VERSION "BodyCAN"

NS_ :

BS_:

BU_: CCM CEM DDM ETC ILCM PDM POT RLDM RRDM SMD SMP TRM Vector_XXX

BO_ 1120 CemBodyFr06: 8 CEM
 SG_ CmprReqAcCapReqOvr : 62|7@0+ (1,0) [0|100] "%"  CCM
 SG_ CmprReqAcCapReqOvr_UB : 63|1@0+ (1,0) [0|1] ""  CCM
 SG_ CmptmtClngPreStrtReq : 42|2@0+ (1,0) [0|3] ""  CCM
 SG_ CmptmtClngPreStrtReq_UB : 43|1@0+ (1,0) [0|1] ""  CCM
 SG_ SecRowLeDefdMassgProgCfg_UB : 13|1@0+ (1,0) [0|1] ""  Vector_XXX
 SG_ SecRowLeDefdMassgProgCfgMassgBag : 23|1@0+ (1,0) [0|1] ""  Vector_XXX
 SG_ SecRowLeDefdMassgProgCfgMas_0000 : 22|1@0+ (1,0) [0|1] ""  Vector_XXX
 SG_ SecRowLeDefdMassgProgCfgMas_0001 : 21|1@0+ (1,0) [0|1] ""  Vector_XXX
 SG_ SecRowLeDefdMassgProgCfgMas_0002 : 20|1@0+ (1,0) [0|1] ""  Vector_XXX
 SG_ SecRowLeDefdMassgProgCfgMas_0003 : 19|1@0+ (1,0) [0|1] ""  Vector_XXX
 SG_ SecRowLeDefdMassgProgCfgMas_0004 : 18|1@0+ (1,0) [0|1] ""  Vector_XXX
 SG_ SecRowLeDefdMassgProgCfgMas_0005 : 17|1@0+ (1,0) [0|1] ""  Vector_XXX
 SG_ SecRowLeDefdMassgProgCfgMas_0006 : 16|1@0+ (1,0) [0|1] ""  Vector_XXX
 SG_ SecRowLeDefdMassgProgCfgMas_0007 : 31|1@0+ (1,0) [0|1] ""  Vector_XXX
 SG_ SecRowLeDefdMassgProgCfgMas_0008 : 30|1@0+ (1,0) [0|1] ""  Vector_XXX
 SG_ SecRowLeDefdMassgProgCfgMas_0009 : 29|1@0+ (1,0) [0|1] ""  Vector_XXX
 SG_ SecRowLeDefdMassgProgCfgMas_0010 : 28|1@0+ (1,0) [0|1] ""  Vector_XXX
 SG_ SecRowLeDefdMassgProgCfgMas_0011 : 27|1@0+ (1,0) [0|1] ""  Vector_XXX
 SG_ SecRowLeDefdMassgProgCfgMas_0012 : 26|1@0+ (1,0) [0|1] ""  Vector_XXX
 SG_ SecRowLeDefdMassgProgCfgMas_0013 : 25|1@0+ (1,0) [0|1] ""  Vector_XXX
 SG_ SecRowLeDefdMassgProgCfgMas_0014 : 24|1@0+ (1,0) [0|1] ""  Vector_XXX
 SG_ SecRowLeDefdMassgProgCfgMassgFrq : 39|2@0+ (1,0) [0|3] ""  Vector_XXX
 SG_ SecRowLeDefdMassgProgCfgMassgInt : 37|2@0+ (1,0) [0|3] ""  Vector_XXX
 SG_ SecRowLeDefdMassgProgCfgMassProg : 35|4@0+ (1,0) [0|15] "Unitless"  Vector_XXX
 SG_ SecRowLeDefdMassgProgCfgMas_0015 : 9|2@0+ (1,0) [0|3] ""  Vector_XXX
 SG_ SecRowLeDefdMassgProgCfgMassSeqC : 12|3@0+ (1,0) [0|7] "Unitless"  Vector_XXX

BO_ 1171 CemBodyFr08: 8 CEM
 SG_ AmbTRaw_UB : 45|1@0+ (1,0) [0|1] ""  CCM,DDM,PDM,RLDM,RRDM
 SG_ AmbTRawAmbTVal : 42|11@0+ (0.1,-70) [-70|134.7] "degC"  CCM,DDM,PDM,RLDM,RRDM
 SG_ AmbTRawQly : 44|2@0+ (1,0) [0|3] ""  CCM,DDM,PDM,RLDM,RRDM
 SG_ BltLockStAtDrvr_UB : 21|1@0+ (1,0) [0|1] ""  CCM
 SG_ BltLockStAtDrvrBltLockSt1 : 23|1@0+ (1,0) [0|1] ""  CCM
 SG_ BltLockStAtDrvrBltLockSts : 22|1@0+ (1,0) [0|1] ""  CCM
 SG_ BltLockStAtPass_UB : 34|1@0+ (1,0) [0|1] ""  CCM
 SG_ BltLockStAtPassBltLockSt1 : 33|1@0+ (1,0) [0|1] ""  CCM
 SG_ BltLockStAtPassBltLockSts : 32|1@0+ (1,0) [0|1] ""  CCM
 SG_ BltLockStAtRowSecLe_UB : 4|1@0+ (1,0) [0|1] ""  CCM
 SG_ BltLockStAtRowSecLeBltLockEquid : 7|1@0+ (1,0) [0|1] ""  CCM
 SG_ BltLockStAtRowSecLeBltLockSt1 : 6|1@0+ (1,0) [0|1] ""  CCM
 SG_ BltLockStAtRowSecLeBltLockSts : 5|1@0+ (1,0) [0|1] ""  CCM
 SG_ BltLockStAtRowSecMid_UB : 3|1@0+ (1,0) [0|1] ""  CCM
 SG_ BltLockStAtRowSecMidBltLockEquid : 2|1@0+ (1,0) [0|1] ""  CCM
 SG_ BltLockStAtRowSecMidBltLockSt1 : 1|1@0+ (1,0) [0|1] ""  CCM
 SG_ BltLockStAtRowSecMidBltLockSts : 0|1@0+ (1,0) [0|1] ""  CCM
 SG_ BltLockStAtRowSecRi_UB : 28|1@0+ (1,0) [0|1] ""  CCM
 SG_ BltLockStAtRowSecRiBltLockEquid : 31|1@0+ (1,0) [0|1] ""  CCM
 SG_ BltLockStAtRowSecRiBltLockSt1 : 30|1@0+ (1,0) [0|1] ""  CCM
 SG_ BltLockStAtRowSecRiBltLockSts : 29|1@0+ (1,0) [0|1] ""  CCM
 SG_ BltLockStAtRowThrdLe_UB : 27|1@0+ (1,0) [0|1] ""  CCM
 SG_ BltLockStAtRowThrdLeBltLockEquid : 26|1@0+ (1,0) [0|1] ""  CCM
 SG_ BltLockStAtRowThrdLeBltLockSt1 : 25|1@0+ (1,0) [0|1] ""  CCM
 SG_ BltLockStAtRowThrdLeBltLockSts : 24|1@0+ (1,0) [0|1] ""  CCM
 SG_ BltLockStAtRowThrdRi_UB : 36|1@0+ (1,0) [0|1] ""  CCM
 SG_ BltLockStAtRowThrdRiBltLockEquid : 39|1@0+ (1,0) [0|1] ""  CCM
 SG_ BltLockStAtRowThrdRiBltLockSt1 : 38|1@0+ (1,0) [0|1] ""  CCM
 SG_ BltLockStAtRowThrdRiBltLockSts : 37|1@0+ (1,0) [0|1] ""  CCM
 SG_ CooltHeatrTIntk : 15|8@0+ (1,-40) [-40|210] "degC"  CCM
 SG_ CooltHeatrTIntk_UB : 16|1@0+ (1,0) [0|1] ""  CCM
 SG_ CooltHeatrTOutl : 63|8@0+ (1,-40) [-40|210] "degC"  CCM
 SG_ CooltHeatrTOutl_UB : 47|1@0+ (1,0) [0|1] ""  CCM
 SG_ DrvrPfmncAlrmReq : 19|3@0+ (1,0) [0|7] ""  CCM,SMD
 SG_ DrvrPfmncAlrmReq_UB : 20|1@0+ (1,0) [0|1] ""  CCM,SMD
 SG_ RemChkTInVeh : 35|1@0+ (1,0) [0|1] ""  CCM
 SG_ RemChkTInVeh_UB : 46|1@0+ (1,0) [0|1] ""  CCM

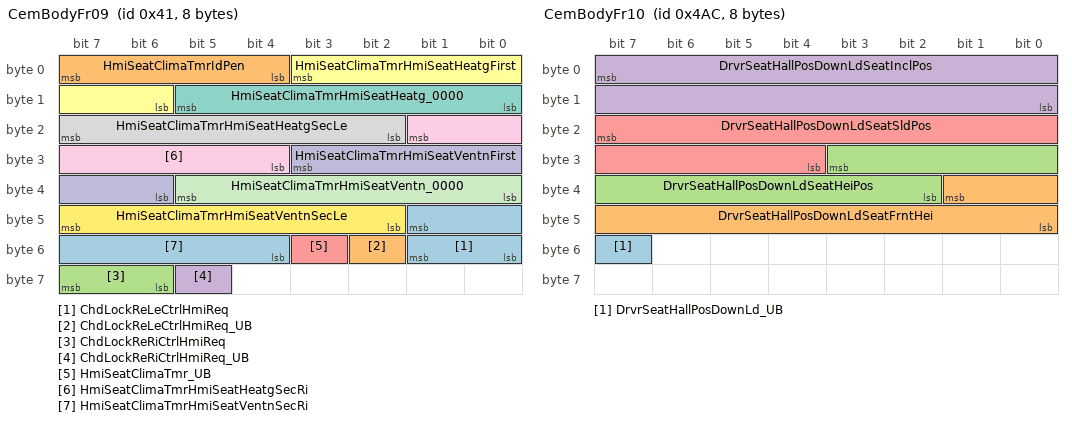
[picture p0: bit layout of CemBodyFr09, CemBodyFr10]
BO_ 65 CemBodyFr09: 8 CEM
 SG_ ChdLockReLeCtrlHmiReq : 49|2@0+ (1,0) [0|3] ""  DDM
 SG_ ChdLockReLeCtrlHmiReq_UB : 50|1@0+ (1,0) [0|1] ""  DDM
 SG_ ChdLockReRiCtrlHmiReq : 63|2@0+ (1,0) [0|3] ""  DDM
 SG_ ChdLockReRiCtrlHmiReq_UB : 61|1@0+ (1,0) [0|1] ""  DDM
 SG_ HmiSeatClimaTmr_UB : 51|1@0+ (1,0) [0|1] ""  SMD,SMP
 SG_ HmiSeatClimaTmrHmiSeatHeatgFirst : 3|6@0+ (1,0) [0|59] "Mins"  SMD,SMP
 SG_ HmiSeatClimaTmrHmiSeatHeatg_0000 : 13|6@0+ (1,0) [0|59] "Mins"  SMD,SMP
 SG_ HmiSeatClimaTmrHmiSeatHeatgSecLe : 23|6@0+ (1,0) [0|59] "Mins"  SMD,SMP
 SG_ HmiSeatClimaTmrHmiSeatHeatgSecRi : 17|6@0+ (1,0) [0|59] "Mins"  SMD,SMP
 SG_ HmiSeatClimaTmrHmiSeatVentnFirst : 27|6@0+ (1,0) [0|59] "Mins"  SMD,SMP
 SG_ HmiSeatClimaTmrHmiSeatVentn_0000 : 37|6@0+ (1,0) [0|59] "Mins"  SMD,SMP
 SG_ HmiSeatClimaTmrHmiSeatVentnSecLe : 47|6@0+ (1,0) [0|59] "Mins"  SMD,SMP
 SG_ HmiSeatClimaTmrHmiSeatVentnSecRi : 41|6@0+ (1,0) [0|59] "Mins"  SMD,SMP
 SG_ HmiSeatClimaTmrIdPen : 7|4@0+ (1,0) [0|15] ""  SMD,SMP

BO_ 1196 CemBodyFr10: 8 CEM
 SG_ DrvrSeatHallPosDownLd_UB : 55|1@0+ (1,0) [0|1] ""  SMD
 SG_ DrvrSeatHallPosDownLdSeatFrntHei : 33|10@0+ (1,0) [0|1023] "Unitless"  SMD
 SG_ DrvrSeatHallPosDownLdSeatHeiPos : 27|10@0+ (1,0) [0|1023] "Unitless"  SMD
 SG_ DrvrSeatHallPosDownLdSeatInclPos : 7|16@0+ (1,0) [0|65535] "Unitless"  SMD
 SG_ DrvrSeatHallPosDownLdSeatSldPos : 23|12@0+ (1,0) [0|4095] "Unitless"  SMD

BO_ 234 CemBodyFr102: 8 CEM
 SG_ DoorSldngLeReReq_UB : 21|1@0+ (1,0) [0|1] ""  Vector_XXX
 SG_ DoorSldngLeReReqChks : 7|8@0+ (1,0) [0|255] "Unitless"  Vector_XXX
 SG_ DoorSldngLeReReqCntr : 15|4@0+ (1,0) [0|15] "Unitless"  Vector_XXX
 SG_ DoorSldngLeReReqDoorOpenerReq : 23|2@0+ (1,0) [0|3] ""  Vector_XXX
 SG_ DoorSldngLeReReqTrigSrc : 11|3@0+ (1,0) [0|7] ""  Vector_XXX
 SG_ DoorSldngRiReReq_UB : 55|1@0+ (1,0) [0|1] ""  Vector_XXX
 SG_ DoorSldngRiReReqChks : 31|8@0+ (1,0) [0|255] "Unitless"  Vector_XXX
 SG_ DoorSldngRiReReqCntr : 39|4@0+ (1,0) [0|15] "Unitless"  Vector_XXX
 SG_ DoorSldngRiReReqDoorOpenerReq : 47|2@0+ (1,0) [0|3] ""  Vector_XXX
 SG_ DoorSldngRiReReqTrigSrc : 35|3@0+ (1,0) [0|7] ""  Vector_XXX
 SG_ FirstRowLeDefdMassgProgSeln : 45|1@0+ (1,0) [0|1] ""  SMD
 SG_ FirstRowLeDefdMassgProgSeln_UB : 44|1@0+ (1,0) [0|1] ""  SMD
 SG_ FirstRowRiDefdMassgProgSeln : 43|1@0+ (1,0) [0|1] ""  SMP
 SG_ FirstRowRiDefdMassgProgSeln_UB : 42|1@0+ (1,0) [0|1] ""  SMP
 SG_ FRDSDoorOpenInd : 41|1@0+ (1,0) [0|1] ""  Vector_XXX
 SG_ FRDSDoorOpenInd_UB : 40|1@0+ (1,0) [0|1] ""  Vector_XXX
 SG_ FRDSLockgSts : 20|1@0+ (1,0) [0|1] ""  Vector_XXX
 SG_ FRDSLockgSts_UB : 19|1@0+ (1,0) [0|1] ""  Vector_XXX
 SG_ TrsmParkLockd_UB : 54|1@0+ (1,0) [0|1] ""  Vector_XXX
 SG_ TrsmParkLockdChks : 63|8@0+ (1,0) [0|255] "Unitless"  Vector_XXX
 SG_ TrsmParkLockdCntr : 51|4@0+ (1,0) [0|15] "Unitless"  Vector_XXX
 SG_ TrsmParkLockdTrsmParkLockd : 53|2@0+ (1,0) [0|3] ""  Vector_XXX

BO_ 91 CemBodyFr103: 8 CEM
 SG_ HvBattLimnIndcn : 23|16@0+ (1,0) [0|65535] "Unitless"  DDM
 SG_ HvBattLimnIndcn_UB : 11|1@0+ (1,0) [0|1] ""  DDM
 SG_ SeatFoldRaiseReqRowSecLe : 39|2@0+ (1,0) [0|3] ""  Vector_XXX
 SG_ SeatFoldRaiseReqRowSecLe_UB : 37|1@0+ (1,0) [0|1] ""  Vector_XXX
 SG_ SeatFoldRaiseReqRowSecMid : 36|2@0+ (1,0) [0|3] ""  Vector_XXX
 SG_ SeatFoldRaiseReqRowSecMid_UB : 34|1@0+ (1,0) [0|1] ""  Vector_XXX
 SG_ SeatFoldRaiseReqRowSecRi : 33|2@0+ (1,0) [0|3] ""  Vector_XXX
 SG_ SeatFoldRaiseReqRowSecRi_UB : 47|1@0+ (1,0) [0|1] ""  Vector_XXX
 SG_ SeatFoldRaiseReqRowThrdLe : 46|2@0+ (1,0) [0|3] ""  Vector_XXX
 SG_ SeatFoldRaiseReqRowThrdLe_UB : 44|1@0+ (1,0) [0|1] ""  Vector_XXX
 SG_ SeatFoldRaiseReqRowThrdRi : 9|2@0+ (1,0) [0|3] ""  Vector_XXX
 SG_ SeatFoldRaiseReqRowThrdRi_UB : 10|1@0+ (1,0) [0|1] ""  Vector_XXX
 SG_ ShortDropWinDrvrDoor : 7|2@0+ (1,0) [0|3] ""  DDM
 SG_ ShortDropWinDrvrDoor_UB : 5|1@0+ (1,0) [0|1] ""  DDM
 SG_ ShortDropWinLeReDoor : 4|2@0+ (1,0) [0|3] ""  RLDM
 SG_ ShortDropWinLeReDoor_UB : 2|1@0+ (1,0) [0|1] ""  RLDM
 SG_ ShortDropWinPassDoor : 1|2@0+ (1,0) [0|3] ""  PDM
 SG_ ShortDropWinPassDoor_UB : 15|1@0+ (1,0) [0|1] ""  PDM
 SG_ ShortDropWinRiReDoor : 14|2@0+ (1,0) [0|3] ""  RRDM
 SG_ ShortDropWinRiReDoor_UB : 12|1@0+ (1,0) [0|1] ""  RRDM

BO_ 132 CemBodyFr104: 8 CEM
 SG_ LeReWinBtnDwn : 3|1@0+ (1,0) [0|1] ""  RLDM
 SG_ LeReWinBtnDwn_UB : 5|1@0+ (1,0) [0|1] ""  RLDM
 SG_ LeReWinBtnRise : 4|1@0+ (1,0) [0|1] ""  RLDM
 SG_ LeReWinBtnRise_UB : 6|1@0+ (1,0) [0|1] ""  RLDM
 SG_ MusicInfoForMusicShow2_UB : 2|1@0+ (1,0) [0|1] ""  ILCM
 SG_ MusicInfoForMusicShow2DownSampli : 15|4@0+ (1,0) [0|15] "Unitless"  ILCM
 SG_ MusicInfoForMusicShow2MaxFFT100m : 11|4@0+ (1,0) [0|15] "Unitless"  ILCM
 SG_ MusicInfoForMusicShow2MaxFF_0000 : 23|8@0+ (1,0) [0|255] "Unitless"  ILCM
 SG_ MusicInfoForMusicShow2Segment1FF : 31|4@0+ (1,0) [0|15] "Unitless"  ILCM
 SG_ MusicInfoForMusicShow2Segment2FF : 27|4@0+ (1,0) [0|15] "Unitless"  ILCM
 SG_ MusicInfoForMusicShow2Segment3FF : 39|4@0+ (1,0) [0|15] "Unitless"  ILCM
 SG_ MusicInfoForMusicShow2Segment4FF : 35|4@0+ (1,0) [0|15] "Unitless"  ILCM
 SG_ MusicInfoForMusicShow2Segment5FF : 47|4@0+ (1,0) [0|15] "Unitless"  ILCM
 SG_ MusicInfoForMusicShow2Segment6FF : 43|4@0+ (1,0) [0|15] "Unitless"  ILCM
 SG_ MusicInfoForMusicShow2Segment7FF : 55|4@0+ (1,0) [0|15] "Unitless"  ILCM
 SG_ MusicInfoForMusicShow2Segment8FF : 51|4@0+ (1,0) [0|15] "Unitless"  ILCM
 SG_ MusicInfoForMusicShow2StateFlagA : 1|1@0+ (1,0) [0|1] ""  ILCM
 SG_ MusicInfoForMusicShow2StateFlagN : 0|1@0+ (1,0) [0|1] ""  ILCM
 SG_ MusicInfoForMusicShow2TimeFlagAu : 63|4@0+ (1,0) [0|15] "Unitless"  ILCM
 SG_ MusicInfoForMusicShow2TimeFlagMe : 59|4@0+ (1,0) [0|15] "Unitless"  ILCM

BO_ 136 CemBodyFr105: 8 CEM
 SG_ MusicInfoForMusicShow3_UB : 2|1@0+ (1,0) [0|1] ""  ILCM
 SG_ MusicInfoForMusicShow3DownSampli : 15|4@0+ (1,0) [0|15] "Unitless"  ILCM
 SG_ MusicInfoForMusicShow3MaxFFT100m : 11|4@0+ (1,0) [0|15] "Unitless"  ILCM
 SG_ MusicInfoForMusicShow3MaxFF_0000 : 23|8@0+ (1,0) [0|255] "Unitless"  ILCM
 SG_ MusicInfoForMusicShow3Segment1FF : 31|4@0+ (1,0) [0|15] "Unitless"  ILCM
 SG_ MusicInfoForMusicShow3Segment2FF : 27|4@0+ (1,0) [0|15] "Unitless"  ILCM
 SG_ MusicInfoForMusicShow3Segment3FF : 39|4@0+ (1,0) [0|15] "Unitless"  ILCM
 SG_ MusicInfoForMusicShow3Segment4FF : 35|4@0+ (1,0) [0|15] "Unitless"  ILCM
 SG_ MusicInfoForMusicShow3Segment5FF : 47|4@0+ (1,0) [0|15] "Unitless"  ILCM
 SG_ MusicInfoForMusicShow3Segment6FF : 43|4@0+ (1,0) [0|15] "Unitless"  ILCM
 SG_ MusicInfoForMusicShow3Segment7FF : 55|4@0+ (1,0) [0|15] "Unitless"  ILCM
 SG_ MusicInfoForMusicShow3Segment8FF : 51|4@0+ (1,0) [0|15] "Unitless"  ILCM
 SG_ MusicInfoForMusicShow3StateFlagA : 1|1@0+ (1,0) [0|1] ""  ILCM
 SG_ MusicInfoForMusicShow3StateFlagN : 0|1@0+ (1,0) [0|1] ""  ILCM
 SG_ MusicInfoForMusicShow3TimeFlagAu : 63|4@0+ (1,0) [0|15] "Unitless"  ILCM
 SG_ MusicInfoForMusicShow3TimeFlagMe : 59|4@0+ (1,0) [0|15] "Unitless"  ILCM
 SG_ RiReWinBtnDwn : 3|1@0+ (1,0) [0|1] ""  RRDM
 SG_ RiReWinBtnDwn_UB : 5|1@0+ (1,0) [0|1] ""  RRDM
 SG_ RiReWinBtnRise : 4|1@0+ (1,0) [0|1] ""  RRDM
 SG_ RiReWinBtnRise_UB : 6|1@0+ (1,0) [0|1] ""  RRDM

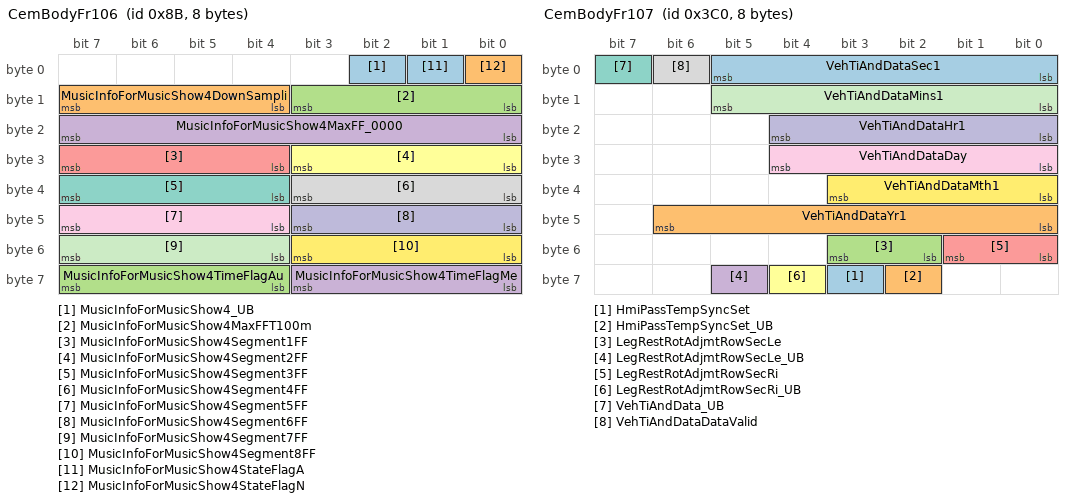
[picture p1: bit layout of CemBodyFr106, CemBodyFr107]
BO_ 139 CemBodyFr106: 8 CEM
 SG_ MusicInfoForMusicShow4_UB : 2|1@0+ (1,0) [0|1] ""  ILCM
 SG_ MusicInfoForMusicShow4DownSampli : 15|4@0+ (1,0) [0|15] "Unitless"  ILCM
 SG_ MusicInfoForMusicShow4MaxFFT100m : 11|4@0+ (1,0) [0|15] "Unitless"  ILCM
 SG_ MusicInfoForMusicShow4MaxFF_0000 : 23|8@0+ (1,0) [0|255] "Unitless"  ILCM
 SG_ MusicInfoForMusicShow4Segment1FF : 31|4@0+ (1,0) [0|15] "Unitless"  ILCM
 SG_ MusicInfoForMusicShow4Segment2FF : 27|4@0+ (1,0) [0|15] "Unitless"  ILCM
 SG_ MusicInfoForMusicShow4Segment3FF : 39|4@0+ (1,0) [0|15] "Unitless"  ILCM
 SG_ MusicInfoForMusicShow4Segment4FF : 35|4@0+ (1,0) [0|15] "Unitless"  ILCM
 SG_ MusicInfoForMusicShow4Segment5FF : 47|4@0+ (1,0) [0|15] "Unitless"  ILCM
 SG_ MusicInfoForMusicShow4Segment6FF : 43|4@0+ (1,0) [0|15] "Unitless"  ILCM
 SG_ MusicInfoForMusicShow4Segment7FF : 55|4@0+ (1,0) [0|15] "Unitless"  ILCM
 SG_ MusicInfoForMusicShow4Segment8FF : 51|4@0+ (1,0) [0|15] "Unitless"  ILCM
 SG_ MusicInfoForMusicShow4StateFlagA : 1|1@0+ (1,0) [0|1] ""  ILCM
 SG_ MusicInfoForMusicShow4StateFlagN : 0|1@0+ (1,0) [0|1] ""  ILCM
 SG_ MusicInfoForMusicShow4TimeFlagAu : 63|4@0+ (1,0) [0|15] "Unitless"  ILCM
 SG_ MusicInfoForMusicShow4TimeFlagMe : 59|4@0+ (1,0) [0|15] "Unitless"  ILCM

BO_ 960 CemBodyFr107: 8 CEM
 SG_ HmiPassTempSyncSet : 59|1@0+ (1,0) [0|1] ""  CCM
 SG_ HmiPassTempSyncSet_UB : 58|1@0+ (1,0) [0|1] ""  CCM
 SG_ LegRestRotAdjmtRowSecLe : 51|2@0+ (1,0) [0|3] ""  Vector_XXX
 SG_ LegRestRotAdjmtRowSecLe_UB : 61|1@0+ (1,0) [0|1] ""  Vector_XXX
 SG_ LegRestRotAdjmtRowSecRi : 49|2@0+ (1,0) [0|3] ""  Vector_XXX
 SG_ LegRestRotAdjmtRowSecRi_UB : 60|1@0+ (1,0) [0|1] ""  Vector_XXX
 SG_ VehTiAndData_UB : 7|1@0+ (1,0) [0|1] ""  CCM,ILCM
 SG_ VehTiAndDataDataValid : 6|1@0+ (1,0) [0|1] ""  CCM,ILCM
 SG_ VehTiAndDataDay : 28|5@0+ (1,0) [1|31] "Days"  CCM,ILCM
 SG_ VehTiAndDataHr1 : 20|5@0+ (1,0) [0|23] "hours"  CCM,ILCM
 SG_ VehTiAndDataMins1 : 13|6@0+ (1,0) [0|59] "Mins"  CCM,ILCM
 SG_ VehTiAndDataMth1 : 35|4@0+ (1,0) [1|12] "Month"  CCM,ILCM
 SG_ VehTiAndDataSec1 : 5|6@0+ (1,0) [0|59] "s"  CCM,ILCM
 SG_ VehTiAndDataYr1 : 46|7@0+ (1,0) [0|99] "Year"  CCM,ILCM

BO_ 243 CemBodyFr108: 8 CEM
 SG_ ActvnOfPudLi : 53|1@0+ (1,0) [0|1] ""  DDM,PDM
 SG_ ActvnOfPudLi_UB : 52|1@0+ (1,0) [0|1] ""  DDM,PDM
 SG_ CushExtnSecRowLe : 39|2@0+ (1,0) [0|3] ""  Vector_XXX
 SG_ CushExtnSecRowLe_UB : 47|1@0+ (1,0) [0|1] ""  Vector_XXX
 SG_ CushExtnSecRowRi : 41|2@0+ (1,0) [0|3] ""  Vector_XXX
 SG_ CushExtnSecRowRi_UB : 42|1@0+ (1,0) [0|1] ""  Vector_XXX
 SG_ HmiElecAirFrntSwtReq_UB : 62|1@0+ (1,0) [0|1] ""  CCM
 SG_ HmiElecAirFrntSwtReqHmiElecAirDr : 59|1@0+ (1,0) [0|1] ""  CCM
 SG_ HmiElecAirFrntSwtReqHmiElec_0000 : 58|1@0+ (1,0) [0|1] ""  CCM
 SG_ HmiElecAirFrntSwtReqHmiElecAirPa : 57|1@0+ (1,0) [0|1] ""  CCM
 SG_ HmiElecAirFrntSwtReqHmiElec_0001 : 56|1@0+ (1,0) [0|1] ""  CCM
 SG_ HmiElecAirReSwtReq_UB : 63|1@0+ (1,0) [0|1] ""  CCM
 SG_ HmiElecAirReSwtReqHmiElecAirReLe : 49|1@0+ (1,0) [0|1] ""  CCM
 SG_ HmiElecAirReSwtReqHmiElecAirReRi : 48|1@0+ (1,0) [0|1] ""  CCM
 SG_ RearWinDimEna : 61|2@0+ (1,0) [0|3] ""  RLDM,RRDM
 SG_ RearWinDimEna_UB : 51|1@0+ (1,0) [0|1] ""  RLDM,RRDM
 SG_ RollAgGlb_UB : 30|1@0+ (1,0) [0|1] ""  Vector_XXX
 SG_ RollAgGlbQf : 1|2@0+ (1,0) [0|3] ""  Vector_XXX
 SG_ RollAgGlbVal : 15|16@0- (3.0518E-005,0) [-0.999983306|0.999983306] "rad"  Vector_XXX
 SG_ SecRowLeLoadAndStoreReq_UB : 7|1@0+ (1,0) [0|1] ""  Vector_XXX
 SG_ SecRowLeLoadAndStoreReqErgoPosn : 3|2@0+ (1,0) [0|3] ""  Vector_XXX
 SG_ SecRowLeLoadAndStoreReqErgoSetgE : 6|3@0+ (1,0) [0|7] ""  Vector_XXX
 SG_ SecRowRiLoadAndStoreReq_UB : 29|1@0+ (1,0) [0|1] ""  Vector_XXX
 SG_ SecRowRiLoadAndStoreReqErgoPosn : 28|2@0+ (1,0) [0|3] ""  Vector_XXX
 SG_ SecRowRiLoadAndStoreReqErgoSetgE : 26|3@0+ (1,0) [0|7] ""  Vector_XXX
 SG_ SecRowRiSeatDispMassgFct_UB : 31|1@0+ (1,0) [0|1] ""  Vector_XXX
 SG_ SecRowRiSeatDispMassgFctMassgInt : 33|2@0+ (1,0) [0|3] ""  Vector_XXX
 SG_ SecRowRiSeatDispMassgFctMassgPro : 36|3@0+ (1,0) [0|7] ""  Vector_XXX
 SG_ SecRowRiSeatDispMassgFctOnOff : 37|1@0+ (1,0) [0|1] ""  Vector_XXX
 SG_ ShoulderAdjmtRowSecLe : 44|2@0+ (1,0) [0|3] ""  Vector_XXX
 SG_ ShoulderAdjmtRowSecLe_UB : 45|1@0+ (1,0) [0|1] ""  Vector_XXX
 SG_ ShoulderAdjmtRowSecRi : 55|2@0+ (1,0) [0|3] ""  Vector_XXX
 SG_ ShoulderAdjmtRowSecRi_UB : 46|1@0+ (1,0) [0|1] ""  Vector_XXX

BO_ 818 CemBodyFr109: 8 CEM
 SG_ HmiCmptmtSecRowLeAirDistbn : 7|3@0+ (1,0) [0|7] ""  CCM
 SG_ HmiCmptmtSecRowLeAirDistbn_UB : 4|1@0+ (1,0) [0|1] ""  CCM
 SG_ HmiCmptmtSecRowRiAirDistbn : 2|3@0+ (1,0) [0|7] ""  CCM
 SG_ HmiCmptmtSecRowRiAirDistbn_UB : 3|1@0+ (1,0) [0|1] ""  CCM
 SG_ HmiDrvrClimaAutReq : 17|1@0+ (1,0) [0|1] ""  CCM
 SG_ HmiDrvrClimaAutReq_UB : 18|1@0+ (1,0) [0|1] ""  CCM
 SG_ HmiDrvrHvacFanLvl : 15|4@0+ (1,0) [0|15] ""  CCM
 SG_ HmiDrvrHvacFanLvl_UB : 23|1@0+ (1,0) [0|1] ""  CCM
 SG_ HmiPassClimaAutReq : 19|1@0+ (1,0) [0|1] ""  CCM
 SG_ HmiPassClimaAutReq_UB : 20|1@0+ (1,0) [0|1] ""  CCM
 SG_ HmiPassHvacFanLvl : 11|4@0+ (1,0) [0|15] ""  CCM
 SG_ HmiPassHvacFanLvl_UB : 16|1@0+ (1,0) [0|1] ""  CCM
 SG_ HmiSecRowLeClimaAutReq : 21|1@0+ (1,0) [0|1] ""  CCM
 SG_ HmiSecRowLeClimaAutReq_UB : 22|1@0+ (1,0) [0|1] ""  CCM
 SG_ HmiSecRowLeHvacFanLvl : 31|4@0+ (1,0) [0|15] ""  CCM
 SG_ HmiSecRowLeHvacFanLvl_UB : 27|1@0+ (1,0) [0|1] ""  CCM
 SG_ HmiSecRowRiClimaAutReq : 26|1@0+ (1,0) [0|1] ""  CCM
 SG_ HmiSecRowRiClimaAutReq_UB : 25|1@0+ (1,0) [0|1] ""  CCM
 SG_ HmiSecRowRiHvacFanLvl : 39|4@0+ (1,0) [0|15] ""  CCM
 SG_ HmiSecRowRiHvacFanLvl_UB : 24|1@0+ (1,0) [0|1] ""  CCM

BO_ 224 CEMBodyFr11: 8 CEM
 SG_ DoorPassSts : 31|2@0+ (1,0) [0|3] ""  CCM,DDM,ILCM,PDM,RLDM,RRDM,SMP,TRM
 SG_ DoorPassSts_UB : 29|1@0+ (1,0) [0|1] ""  CCM,DDM,ILCM,PDM,RLDM,RRDM,SMP,TRM
 SG_ DoorRiReSts : 13|2@0+ (1,0) [0|3] ""  CCM,DDM,ILCM,PDM,RLDM,RRDM,TRM
 SG_ DoorRiReSts_UB : 14|1@0+ (1,0) [0|1] ""  CCM,DDM,ILCM,PDM,RLDM,RRDM,TRM
 SG_ HvPwrAvlForClimaEstimd : 25|10@0+ (20,0) [0|20460] "W"  CCM
 SG_ HvPwrAvlForClimaEstimd_UB : 26|1@0+ (1,0) [0|1] ""  CCM
 SG_ IntrBriSts : 43|4@0+ (1,0) [0|15] "Unitless"  CCM,DDM,ILCM,PDM,RLDM,RRDM
 SG_ IntrBriSts_UB : 44|1@0+ (1,0) [0|1] ""  CCM,DDM,ILCM,PDM,RLDM,RRDM
 SG_ MirrTintgCmd : 54|7@0+ (1,0) [0|100] "%"  DDM,PDM
 SG_ MirrTintgCmd_UB : 55|1@0+ (1,0) [0|1] ""  DDM,PDM
 SG_ SecRowLeSeatDispSpplFct : 7|3@0+ (1,0) [0|7] ""  Vector_XXX
 SG_ SecRowLeSeatDispSpplFct_UB : 4|1@0+ (1,0) [0|1] ""  Vector_XXX
 SG_ SecRowRiSeatDispSpplFct : 3|3@0+ (1,0) [0|7] ""  Vector_XXX
 SG_ SecRowRiSeatDispSpplFct_UB : 0|1@0+ (1,0) [0|1] ""  Vector_XXX
 SG_ SecRowSeatDispBtnPsd_UB : 10|1@0+ (1,0) [0|1] ""  Vector_XXX
 SG_ SecRowSeatDispBtnPsdSecRowLeSeat : 8|1@0+ (1,0) [0|1] ""  Vector_XXX
 SG_ SecRowSeatDispBtnPsdSecRowRiSeat : 9|1@0+ (1,0) [0|1] ""  Vector_XXX
 SG_ SteerWhlHeatgDesPwr : 23|8@0+ (1,0) [0|255] "Unitless"  CCM
 SG_ SteerWhlHeatgDesPwr_UB : 11|1@0+ (1,0) [0|1] ""  CCM
 SG_ TopPosTrFromHmi : 58|3@0+ (1,0) [0|7] ""  POT
 SG_ TopPosTrFromHmi_UB : 15|1@0+ (1,0) [0|1] ""  POT
 SG_ TrlrLampChkReqFromHmi : 63|2@0+ (1,0) [0|3] ""  TRM
 SG_ TrlrLampChkReqFromHmi_UB : 61|1@0+ (1,0) [0|1] ""  TRM
 SG_ TrlrLiFogActvt : 59|1@0+ (1,0) [0|1] ""  TRM
 SG_ TrlrLiFogActvt_UB : 60|1@0+ (1,0) [0|1] ""  TRM
 SG_ TrPosnUpprProgmReq : 28|1@0+ (1,0) [0|1] ""  POT
 SG_ TrPosnUpprProgmReq_UB : 27|1@0+ (1,0) [0|1] ""  POT
 SG_ TrSts : 47|2@0+ (1,0) [0|3] ""  CCM,TRM
 SG_ TrSts_UB : 45|1@0+ (1,0) [0|1] ""  CCM,TRM

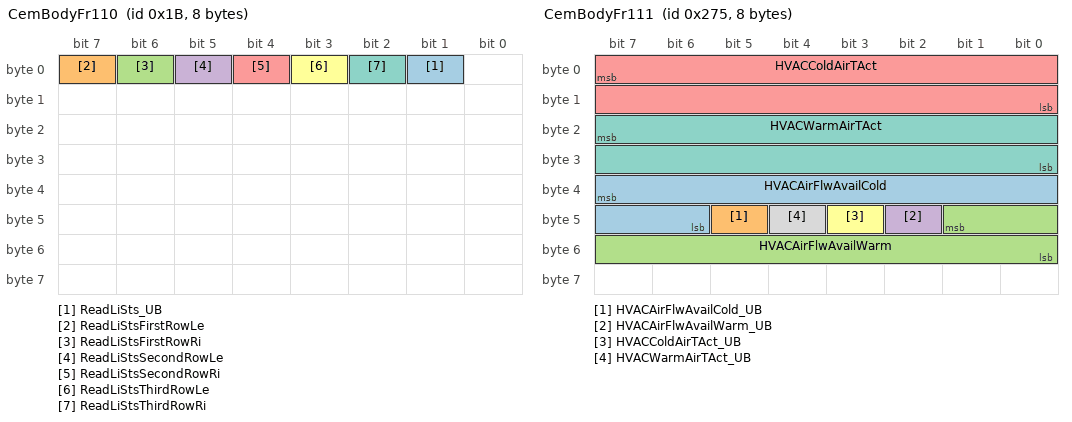
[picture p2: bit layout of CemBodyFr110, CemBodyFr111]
BO_ 27 CemBodyFr110: 8 CEM
 SG_ ReadLiSts_UB : 1|1@0+ (1,0) [0|1] ""  Vector_XXX
 SG_ ReadLiStsFirstRowLe : 7|1@0+ (1,0) [0|1] ""  Vector_XXX
 SG_ ReadLiStsFirstRowRi : 6|1@0+ (1,0) [0|1] ""  Vector_XXX
 SG_ ReadLiStsSecondRowLe : 5|1@0+ (1,0) [0|1] ""  Vector_XXX
 SG_ ReadLiStsSecondRowRi : 4|1@0+ (1,0) [0|1] ""  Vector_XXX
 SG_ ReadLiStsThirdRowLe : 3|1@0+ (1,0) [0|1] ""  Vector_XXX
 SG_ ReadLiStsThirdRowRi : 2|1@0+ (1,0) [0|1] ""  Vector_XXX

BO_ 629 CemBodyFr111: 8 CEM
 SG_ HVACAirFlwAvailCold : 39|10@0+ (1,0) [0|1000] "Kg / h"  Vector_XXX
 SG_ HVACAirFlwAvailCold_UB : 45|1@0+ (1,0) [0|1] ""  Vector_XXX
 SG_ HVACAirFlwAvailWarm : 41|10@0+ (1,0) [0|1000] "Kg / h"  Vector_XXX
 SG_ HVACAirFlwAvailWarm_UB : 42|1@0+ (1,0) [0|1] ""  Vector_XXX
 SG_ HVACColdAirTAct : 7|16@0+ (0.5,-40) [-40|254] "degC"  Vector_XXX
 SG_ HVACColdAirTAct_UB : 43|1@0+ (1,0) [0|1] ""  Vector_XXX
 SG_ HVACWarmAirTAct : 23|16@0+ (0.5,-40) [-40|254] "degC"  Vector_XXX
 SG_ HVACWarmAirTAct_UB : 44|1@0+ (1,0) [0|1] ""  Vector_XXX

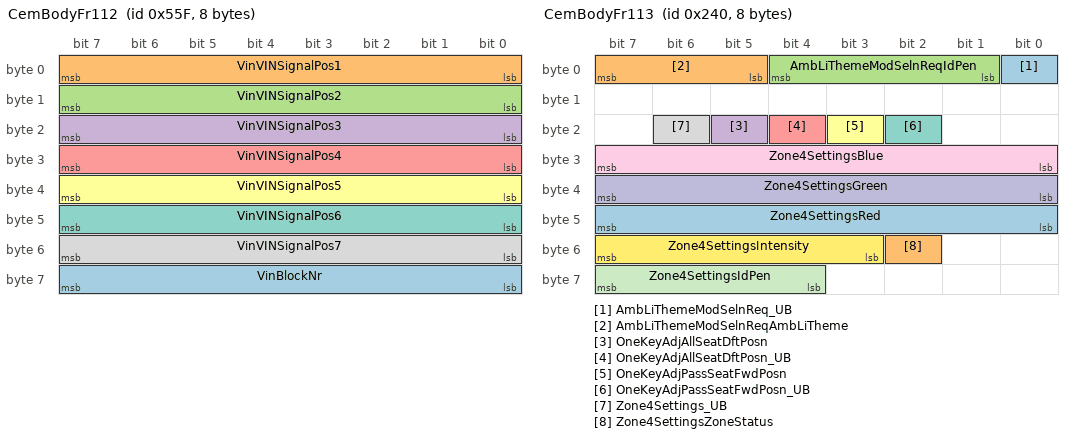
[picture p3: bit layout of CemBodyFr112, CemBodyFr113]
BO_ 1375 CemBodyFr112: 8 CEM
 SG_ VinBlockNr : 63|8@0+ (1,0) [0|255] "Unitless"  CCM
 SG_ VinVINSignalPos1 : 7|8@0+ (1,0) [0|255] "Unitless"  CCM
 SG_ VinVINSignalPos2 : 15|8@0+ (1,0) [0|255] "Unitless"  CCM
 SG_ VinVINSignalPos3 : 23|8@0+ (1,0) [0|255] "Unitless"  CCM
 SG_ VinVINSignalPos4 : 31|8@0+ (1,0) [0|255] "Unitless"  CCM
 SG_ VinVINSignalPos5 : 39|8@0+ (1,0) [0|255] "Unitless"  CCM
 SG_ VinVINSignalPos6 : 47|8@0+ (1,0) [0|255] "Unitless"  CCM
 SG_ VinVINSignalPos7 : 55|8@0+ (1,0) [0|255] "Unitless"  CCM

BO_ 576 CemBodyFr113: 8 CEM
 SG_ AmbLiThemeModSelnReq_UB : 0|1@0+ (1,0) [0|1] ""  ILCM
 SG_ AmbLiThemeModSelnReqAmbLiTheme : 7|3@0+ (1,0) [0|7] ""  ILCM
 SG_ AmbLiThemeModSelnReqIdPen : 4|4@0+ (1,0) [0|15] ""  ILCM
 SG_ OneKeyAdjAllSeatDftPosn : 21|1@0+ (1,0) [0|1] ""  SMD,SMP
 SG_ OneKeyAdjAllSeatDftPosn_UB : 20|1@0+ (1,0) [0|1] ""  SMD,SMP
 SG_ OneKeyAdjPassSeatFwdPosn : 19|1@0+ (1,0) [0|1] ""  SMP
 SG_ OneKeyAdjPassSeatFwdPosn_UB : 18|1@0+ (1,0) [0|1] ""  SMP
 SG_ Zone4Settings_UB : 22|1@0+ (1,0) [0|1] ""  ILCM
 SG_ Zone4SettingsBlue : 31|8@0+ (1,0) [0|255] "Unitless"  ILCM
 SG_ Zone4SettingsGreen : 39|8@0+ (1,0) [0|255] "Unitless"  ILCM
 SG_ Zone4SettingsIdPen : 63|4@0+ (1,0) [0|15] ""  ILCM
 SG_ Zone4SettingsIntensity : 55|5@0+ (1,0) [0|31] "Unitless"  ILCM
 SG_ Zone4SettingsRed : 47|8@0+ (1,0) [0|255] "Unitless"  ILCM
 SG_ Zone4SettingsZoneStatus : 50|1@0+ (1,0) [0|1] ""  ILCM

BO_ 592 CemBodyFr114: 8 CEM
 SG_ AmbLiSpeechCorrlnReq_UB : 10|1@0+ (1,0) [0|1] ""  ILCM
 SG_ AmbLiSpeechCorrlnReqIdPen : 4|4@0+ (1,0) [0|15] ""  ILCM
 SG_ AmbLiSpeechCorrlnReqOnOff1 : 0|1@0+ (1,0) [0|1] ""  ILCM
 SG_ DrvrSeatFldUnfld : 59|2@0+ (1,0) [0|3] ""  SMD
 SG_ DrvrSeatFldUnfld_UB : 23|1@0+ (1,0) [0|1] ""  SMD
 SG_ DrvrSeatHMIpivtCntrl : 57|2@0+ (1,0) [0|3] ""  SMD
 SG_ DrvrSeatHMIpivtCntrl_UB : 22|1@0+ (1,0) [0|1] ""  SMD
 SG_ DrvrSeatSts : 7|2@0+ (1,0) [0|3] ""  CCM,ILCM,SMD
 SG_ DrvrSeatSts_UB : 5|1@0+ (1,0) [0|1] ""  CCM,ILCM,SMD
 SG_ RoadInclnForPOD : 15|5@0+ (1,0) [0|31] ""  Vector_XXX
 SG_ RoadInclnForPOD_UB : 9|1@0+ (1,0) [0|1] ""  Vector_XXX
 SG_ RollAgGlbForPOD : 20|5@0+ (1,0) [0|31] ""  Vector_XXX
 SG_ RollAgGlbForPOD_UB : 8|1@0+ (1,0) [0|1] ""  Vector_XXX
 SG_ Zone5Settings_UB : 21|1@0+ (1,0) [0|1] ""  ILCM
 SG_ Zone5SettingsBlue : 31|8@0+ (1,0) [0|255] "Unitless"  ILCM
 SG_ Zone5SettingsGreen : 39|8@0+ (1,0) [0|255] "Unitless"  ILCM
 SG_ Zone5SettingsIdPen : 63|4@0+ (1,0) [0|15] ""  ILCM
 SG_ Zone5SettingsIntensity : 55|5@0+ (1,0) [0|31] "Unitless"  ILCM
 SG_ Zone5SettingsRed : 47|8@0+ (1,0) [0|255] "Unitless"  ILCM
 SG_ Zone5SettingsZoneStatus : 50|1@0+ (1,0) [0|1] ""  ILCM

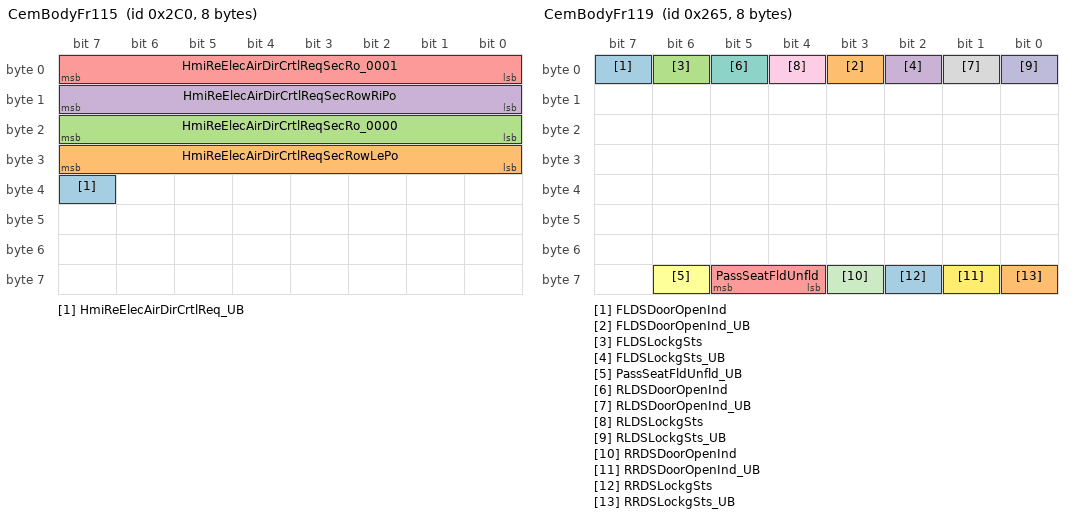
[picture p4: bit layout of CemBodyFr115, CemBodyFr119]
BO_ 704 CemBodyFr115: 8 CEM
 SG_ HmiReElecAirDirCrtlReq_UB : 39|1@0+ (1,0) [0|1] ""  CCM
 SG_ HmiReElecAirDirCrtlReqSecRowLePo : 31|8@0+ (1,0) [0|255] "Unitless"  CCM
 SG_ HmiReElecAirDirCrtlReqSecRo_0000 : 23|8@0+ (1,0) [0|255] "Unitless"  CCM
 SG_ HmiReElecAirDirCrtlReqSecRowRiPo : 15|8@0+ (1,0) [0|255] "Unitless"  CCM
 SG_ HmiReElecAirDirCrtlReqSecRo_0001 : 7|8@0+ (1,0) [0|255] "Unitless"  CCM

BO_ 529 CemBodyFr116: 8 CEM
 SG_ AirClngReq : 9|2@0+ (1,0) [0|3] ""  CCM
 SG_ AirClngReq_UB : 33|1@0+ (1,0) [0|1] ""  CCM
 SG_ AmbLiBriAutAdjmt_UB : 32|1@0+ (1,0) [0|1] ""  ILCM
 SG_ AmbLiBriAutAdjmtCenDispBriSnsrRa : 47|5@0+ (1,0) [0|31] "Unitless"  ILCM
 SG_ AmbLiBriAutAdjmtIdPen : 55|4@0+ (1,0) [0|15] ""  ILCM
 SG_ AmbLiBriAutAdjmtOnOff1 : 42|1@0+ (1,0) [0|1] ""  ILCM
 SG_ AmbLiChrgCorrlnReq_UB : 10|1@0+ (1,0) [0|1] ""  ILCM
 SG_ AmbLiChrgCorrlnReqIdPen : 15|4@0+ (1,0) [0|15] ""  ILCM
 SG_ AmbLiChrgCorrlnReqOnOff1 : 11|1@0+ (1,0) [0|1] ""  ILCM
 SG_ AmbLiClimateCorrlnReq_UB : 18|1@0+ (1,0) [0|1] ""  ILCM
 SG_ AmbLiClimateCorrlnReqIdPen : 23|4@0+ (1,0) [0|15] ""  ILCM
 SG_ AmbLiClimateCorrlnReqOnOff1 : 19|1@0+ (1,0) [0|1] ""  ILCM
 SG_ AmbLiDrvModCorrlnReq_UB : 26|1@0+ (1,0) [0|1] ""  ILCM
 SG_ AmbLiDrvModCorrlnReqIdPen : 31|4@0+ (1,0) [0|15] ""  ILCM
 SG_ AmbLiDrvModCorrlnReqOnOff1 : 27|1@0+ (1,0) [0|1] ""  ILCM
 SG_ AmbLiMod_UB : 63|1@0+ (1,0) [0|1] ""  ILCM
 SG_ AmbLiModAmbLiMod : 62|3@0+ (1,0) [0|7] ""  ILCM
 SG_ AmbLiModIdPen : 59|4@0+ (1,0) [0|15] ""  ILCM
 SG_ AmbLiStrtCorrlnReq_UB : 34|1@0+ (1,0) [0|1] ""  ILCM
 SG_ AmbLiStrtCorrlnReqIdPen : 39|4@0+ (1,0) [0|15] ""  ILCM
 SG_ AmbLiStrtCorrlnReqOnOff1 : 35|1@0+ (1,0) [0|1] ""  ILCM
 SG_ AmbLiStyleSelnReq_UB : 0|1@0+ (1,0) [0|1] ""  ILCM
 SG_ AmbLiStyleSelnReqIdPen : 7|4@0+ (1,0) [0|15] ""  ILCM
 SG_ AmbLiStyleSelnReqScene : 3|3@0+ (1,0) [0|7] ""  ILCM

BO_ 641 CemBodyFr117: 8 CEM
 SG_ ExtSysClimaAirDist : 3|3@0+ (1,0) [0|7] ""  Vector_XXX
 SG_ ExtSysClimaAirDist_UB : 6|1@0+ (1,0) [0|1] ""  Vector_XXX
 SG_ ExtSysClimaAutDefrst : 0|1@0+ (1,0) [0|1] ""  Vector_XXX
 SG_ ExtSysClimaAutDefrst_UB : 5|1@0+ (1,0) [0|1] ""  Vector_XXX
 SG_ ExtSysClimaFanLvl_UB : 4|1@0+ (1,0) [0|1] ""  Vector_XXX
 SG_ ExtSysClimaFanLvlFanLvlFrntRowLe : 15|4@0+ (1,0) [0|15] "Unitless"  Vector_XXX
 SG_ ExtSysClimaFanLvlFanLvlFrntRowRi : 11|4@0+ (1,0) [0|15] "Unitless"  Vector_XXX
 SG_ ExtSysClimaFanLvlFanLvlSecRowLef : 23|4@0+ (1,0) [0|15] "Unitless"  Vector_XXX
 SG_ ExtSysClimaFanLvlFanLvlSecRowRig : 19|4@0+ (1,0) [0|15] "Unitless"  Vector_XXX
 SG_ ExtSysClimaModes : 31|4@0+ (1,0) [0|15] "Unitless"  Vector_XXX
 SG_ ExtSysClimaModes_UB : 7|1@0+ (1,0) [0|1] ""  Vector_XXX
 SG_ ExtSysClimaRecirc : 27|1@0+ (1,0) [0|1] ""  Vector_XXX
 SG_ ExtSysClimaRecirc_UB : 25|1@0+ (1,0) [0|1] ""  Vector_XXX
 SG_ ExtSysClimaReq : 26|1@0+ (1,0) [0|1] ""  Vector_XXX
 SG_ ExtSysClimaReq_UB : 24|1@0+ (1,0) [0|1] ""  Vector_XXX
 SG_ ExtSysClimaTempSp_UB : 37|1@0+ (1,0) [0|1] ""  Vector_XXX
 SG_ ExtSysClimaTempSpTempFrntRowLeft : 36|5@0+ (0.5,15) [15|30.5] "Deg"  Vector_XXX
 SG_ ExtSysClimaTempSpTempFrntRowRigh : 47|5@0+ (0.5,15) [15|30.5] "Deg"  Vector_XXX
 SG_ ExtSysClimaTempSpTempSecRowLeft : 55|5@0+ (0.5,15) [15|30.5] "Deg"  Vector_XXX
 SG_ ExtSysClimaTempSpTempSecRowRight : 63|5@0+ (0.5,15) [15|30.5] "Deg"  Vector_XXX

BO_ 392 CemBodyFr118: 8 CEM
 SG_ DISClimaCmptTempSp : 44|5@0+ (0.5,15) [15|30.5] "Deg"  Vector_XXX
 SG_ DISClimaCmptTempSp_UB : 53|1@0+ (1,0) [0|1] ""  Vector_XXX
 SG_ DISClimaDefrstReq : 55|1@0+ (1,0) [0|1] ""  Vector_XXX
 SG_ DISClimaDefrstReq_UB : 52|1@0+ (1,0) [0|1] ""  Vector_XXX
 SG_ DISClimaFanLvl : 20|4@0+ (1,0) [0|15] "Unitless"  Vector_XXX
 SG_ DISClimaFanLvl_UB : 16|1@0+ (1,0) [0|1] ""  Vector_XXX
 SG_ DISClimaRecircReq : 54|1@0+ (1,0) [0|1] ""  Vector_XXX
 SG_ DISClimaRecircReq_UB : 51|1@0+ (1,0) [0|1] ""  Vector_XXX
 SG_ DoorSwipDrvrOperReq_UB : 21|1@0+ (1,0) [0|1] ""  Vector_XXX
 SG_ DoorSwipDrvrOperReqChks : 7|8@0+ (1,0) [0|255] "Unitless"  Vector_XXX
 SG_ DoorSwipDrvrOperReqCntr : 15|4@0+ (1,0) [0|15] "Unitless"  Vector_XXX
 SG_ DoorSwipDrvrOperReqDoorOpenerReq : 23|2@0+ (1,0) [0|3] ""  Vector_XXX
 SG_ DoorSwipDrvrOperReqTrigSrc : 11|3@0+ (1,0) [0|7] ""  Vector_XXX
 SG_ DoorSwipLeReOperReq_UB : 45|1@0+ (1,0) [0|1] ""  Vector_XXX
 SG_ DoorSwipLeReOperReqChks : 31|8@0+ (1,0) [0|255] "Unitless"  Vector_XXX
 SG_ DoorSwipLeReOperReqCntr : 39|4@0+ (1,0) [0|15] "Unitless"  Vector_XXX
 SG_ DoorSwipLeReOperReqDoorOpenerReq : 47|2@0+ (1,0) [0|3] ""  Vector_XXX
 SG_ DoorSwipLeReOperReqTrigSrc : 35|3@0+ (1,0) [0|7] ""  Vector_XXX
 SG_ PassSeatHMIpivtCntrl : 50|2@0+ (1,0) [0|3] ""  SMP
 SG_ PassSeatHMIpivtCntrl_UB : 48|1@0+ (1,0) [0|1] ""  SMP
 SG_ SwipDoorDrvrDisb : 63|1@0+ (1,0) [0|1] ""  Vector_XXX
 SG_ SwipDoorDrvrDisb_UB : 59|1@0+ (1,0) [0|1] ""  Vector_XXX
 SG_ SwipDoorLeReDisb : 62|1@0+ (1,0) [0|1] ""  Vector_XXX
 SG_ SwipDoorLeReDisb_UB : 58|1@0+ (1,0) [0|1] ""  Vector_XXX
 SG_ SwipDoorPassDisb : 61|1@0+ (1,0) [0|1] ""  Vector_XXX
 SG_ SwipDoorPassDisb_UB : 57|1@0+ (1,0) [0|1] ""  Vector_XXX
 SG_ SwipDoorRiReDisb : 60|1@0+ (1,0) [0|1] ""  Vector_XXX
 SG_ SwipDoorRiReDisb_UB : 56|1@0+ (1,0) [0|1] ""  Vector_XXX

BO_ 613 CemBodyFr119: 8 CEM
 SG_ FLDSDoorOpenInd : 7|1@0+ (1,0) [0|1] ""  Vector_XXX
 SG_ FLDSDoorOpenInd_UB : 3|1@0+ (1,0) [0|1] ""  Vector_XXX
 SG_ FLDSLockgSts : 6|1@0+ (1,0) [0|1] ""  Vector_XXX
 SG_ FLDSLockgSts_UB : 2|1@0+ (1,0) [0|1] ""  Vector_XXX
 SG_ PassSeatFldUnfld : 61|2@0+ (1,0) [0|3] ""  SMP
 SG_ PassSeatFldUnfld_UB : 62|1@0+ (1,0) [0|1] ""  SMP
 SG_ RLDSDoorOpenInd : 5|1@0+ (1,0) [0|1] ""  Vector_XXX
 SG_ RLDSDoorOpenInd_UB : 1|1@0+ (1,0) [0|1] ""  Vector_XXX
 SG_ RLDSLockgSts : 4|1@0+ (1,0) [0|1] ""  Vector_XXX
 SG_ RLDSLockgSts_UB : 0|1@0+ (1,0) [0|1] ""  Vector_XXX
 SG_ RRDSDoorOpenInd : 59|1@0+ (1,0) [0|1] ""  Vector_XXX
 SG_ RRDSDoorOpenInd_UB : 57|1@0+ (1,0) [0|1] ""  Vector_XXX
 SG_ RRDSLockgSts : 58|1@0+ (1,0) [0|1] ""  Vector_XXX
 SG_ RRDSLockgSts_UB : 56|1@0+ (1,0) [0|1] ""  Vector_XXX

BO_ 240 CEMBodyFr12: 8 CEM
 SG_ DoorDrvrHndlCmd : 43|2@0+ (1,0) [0|3] ""  DDM
 SG_ DoorDrvrHndlCmd_UB : 47|1@0+ (1,0) [0|1] ""  DDM
 SG_ DoorLeReHndlCmd : 41|2@0+ (1,0) [0|3] ""  RLDM
 SG_ DoorLeReHndlCmd_UB : 54|1@0+ (1,0) [0|1] ""  RLDM
 SG_ DoorPassHndlCmd : 49|2@0+ (1,0) [0|3] ""  PDM
 SG_ DoorPassHndlCmd_UB : 53|1@0+ (1,0) [0|1] ""  PDM
 SG_ DoorRiReHndlCmd : 51|2@0+ (1,0) [0|3] ""  RRDM
 SG_ DoorRiReHndlCmd_UB : 52|1@0+ (1,0) [0|1] ""  RRDM
 SG_ DrvrCtrlOfPassSeatFrntReqd : 60|1@0+ (1,0) [0|1] ""  SMD
 SG_ DrvrCtrlOfPassSeatFrntReqd_UB : 61|1@0+ (1,0) [0|1] ""  SMD
 SG_ OnBdChrgrHndlSts1 : 59|4@0+ (1,0) [0|15] ""  CCM
 SG_ OnBdChrgrHndlSts1_UB : 55|1@0+ (1,0) [0|1] ""  CCM
 SG_ TrlrLiPosnActvt : 45|2@0+ (1,0) [0|3] ""  TRM
 SG_ TrlrLiPosnActvt_UB : 46|1@0+ (1,0) [0|1] ""  TRM
 SG_ VehModMngtGlbSafe1_UB : 7|1@0+ (1,0) [0|1] ""  CCM,DDM,ILCM,PDM,POT,RLDM,RRDM,SMD,SMP,TRM
 SG_ VehModMngtGlbSafe1CarModSts1 : 2|3@0+ (1,0) [0|7] ""  CCM,DDM,ILCM,PDM,POT,RLDM,RRDM,SMD,SMP,TRM
 SG_ VehModMngtGlbSafe1CarModSubtypWd : 5|3@0+ (1,0) [0|7] "Unitless"  CCM,DDM,ILCM,PDM,POT,RLDM,RRDM,SMD,SMP,TRM
 SG_ VehModMngtGlbSafe1Chks : 39|8@0+ (1,0) [0|255] "Unitless"  CCM,DDM,ILCM,PDM,POT,RLDM,RRDM,SMD,SMP,TRM
 SG_ VehModMngtGlbSafe1Cntr : 15|4@0+ (1,0) [0|15] "Unitless"  CCM,DDM,ILCM,PDM,POT,RLDM,RRDM,SMD,SMP,TRM
 SG_ VehModMngtGlbSafe1EgyLvlElecMai : 27|4@0+ (1,0) [0|15] "Unitless"  CCM,DDM,ILCM,PDM,POT,RLDM,RRDM,SMD,SMP,TRM
 SG_ VehModMngtGlbSafe1EgyLvlElecSubt : 31|4@0+ (1,0) [0|15] "Unitless"  CCM,DDM,ILCM,PDM,POT,RLDM,RRDM,SMD,SMP,TRM
 SG_ VehModMngtGlbSafe1FltEgyCnsWdSts : 6|1@0+ (1,0) [0|1] ""  CCM,DDM,ILCM,PDM,POT,RLDM,RRDM,SMD,SMP,TRM
 SG_ VehModMngtGlbSafe1PwrLvlElecMai : 19|4@0+ (1,0) [0|15] "Unitless"  CCM,DDM,ILCM,PDM,POT,RLDM,RRDM,SMD,SMP,TRM
 SG_ VehModMngtGlbSafe1PwrLvlElecSubt : 23|4@0+ (1,0) [0|15] "Unitless"  CCM,DDM,ILCM,PDM,POT,RLDM,RRDM,SMD,SMP,TRM
 SG_ VehModMngtGlbSafe1UsgModSts : 11|4@0+ (1,0) [0|15] ""  CCM,DDM,ILCM,PDM,POT,RLDM,RRDM,SMD,SMP,TRM

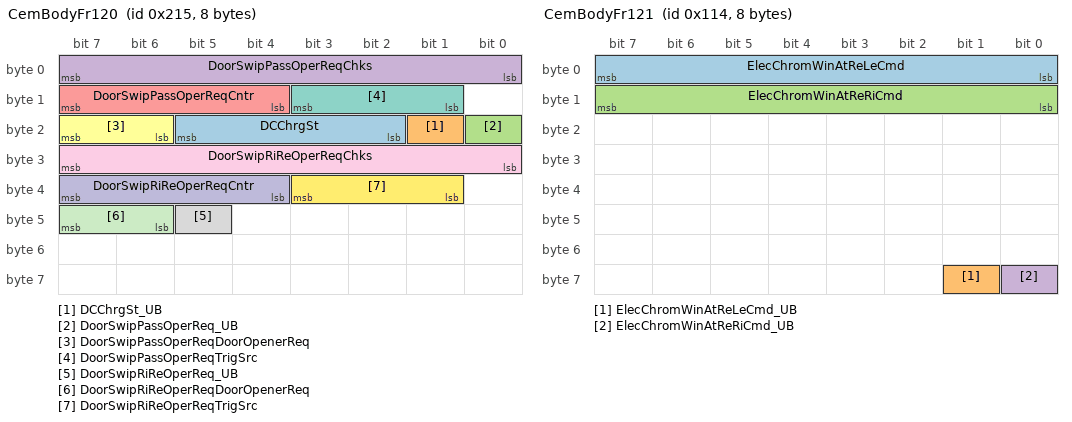
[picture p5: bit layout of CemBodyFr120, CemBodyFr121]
BO_ 533 CemBodyFr120: 8 CEM
 SG_ DCChrgSt : 21|4@0+ (1,0) [0|15] ""  ILCM
 SG_ DCChrgSt_UB : 17|1@0+ (1,0) [0|1] ""  ILCM
 SG_ DoorSwipPassOperReq_UB : 16|1@0+ (1,0) [0|1] ""  Vector_XXX
 SG_ DoorSwipPassOperReqChks : 7|8@0+ (1,0) [0|255] "Unitless"  Vector_XXX
 SG_ DoorSwipPassOperReqCntr : 15|4@0+ (1,0) [0|15] "Unitless"  Vector_XXX
 SG_ DoorSwipPassOperReqDoorOpenerReq : 23|2@0+ (1,0) [0|3] ""  Vector_XXX
 SG_ DoorSwipPassOperReqTrigSrc : 11|3@0+ (1,0) [0|7] ""  Vector_XXX
 SG_ DoorSwipRiReOperReq_UB : 45|1@0+ (1,0) [0|1] ""  Vector_XXX
 SG_ DoorSwipRiReOperReqChks : 31|8@0+ (1,0) [0|255] "Unitless"  Vector_XXX
 SG_ DoorSwipRiReOperReqCntr : 39|4@0+ (1,0) [0|15] "Unitless"  Vector_XXX
 SG_ DoorSwipRiReOperReqDoorOpenerReq : 47|2@0+ (1,0) [0|3] ""  Vector_XXX
 SG_ DoorSwipRiReOperReqTrigSrc : 35|3@0+ (1,0) [0|7] ""  Vector_XXX

BO_ 276 CemBodyFr121: 8 CEM
 SG_ ElecChromWinAtReLeCmd : 7|8@0+ (1,0) [0|100] "%"  RLDM
 SG_ ElecChromWinAtReLeCmd_UB : 57|1@0+ (1,0) [0|1] ""  RLDM
 SG_ ElecChromWinAtReRiCmd : 15|8@0+ (1,0) [0|100] "%"  RRDM
 SG_ ElecChromWinAtReRiCmd_UB : 56|1@0+ (1,0) [0|1] ""  RRDM

BO_ 310 CemBodyFr122: 8 CEM
 SG_ BackrestAdjmtRowSecLe : 7|2@0+ (1,0) [0|3] ""  Vector_XXX
 SG_ BackrestAdjmtRowSecLe_UB : 5|1@0+ (1,0) [0|1] ""  Vector_XXX
 SG_ BackrestAdjmtRowSecRi : 4|2@0+ (1,0) [0|3] ""  Vector_XXX
 SG_ BackrestAdjmtRowSecRi_UB : 2|1@0+ (1,0) [0|1] ""  Vector_XXX
 SG_ BackrestAdjmtRowThrdLe : 15|2@0+ (1,0) [0|3] ""  Vector_XXX
 SG_ BackrestAdjmtRowThrdLe_UB : 13|1@0+ (1,0) [0|1] ""  Vector_XXX
 SG_ BackrestAdjmtRowThrdRi : 12|2@0+ (1,0) [0|3] ""  Vector_XXX
 SG_ BackrestAdjmtRowThrdRi_UB : 10|1@0+ (1,0) [0|1] ""  Vector_XXX
 SG_ CushTiltAdjmtRowSecLe : 23|2@0+ (1,0) [0|3] ""  Vector_XXX
 SG_ CushTiltAdjmtRowSecLe_UB : 21|1@0+ (1,0) [0|1] ""  Vector_XXX
 SG_ CushTiltAdjmtRowSecRi : 20|2@0+ (1,0) [0|3] ""  Vector_XXX
 SG_ CushTiltAdjmtRowSecRi_UB : 18|1@0+ (1,0) [0|1] ""  Vector_XXX
 SG_ HdrestAdjmtRowSecLe : 31|2@0+ (1,0) [0|3] ""  Vector_XXX
 SG_ HdrestAdjmtRowSecLe_UB : 29|1@0+ (1,0) [0|1] ""  Vector_XXX
 SG_ HdrestAdjmtRowSecRi : 28|2@0+ (1,0) [0|3] ""  Vector_XXX
 SG_ HdrestAdjmtRowSecRi_UB : 26|1@0+ (1,0) [0|1] ""  Vector_XXX
 SG_ HdrestHeiAdjmtRowSecLe : 39|2@0+ (1,0) [0|3] ""  Vector_XXX
 SG_ HdrestHeiAdjmtRowSecLe_UB : 37|1@0+ (1,0) [0|1] ""  Vector_XXX
 SG_ HdrestHeiAdjmtRowSecRi : 36|2@0+ (1,0) [0|3] ""  Vector_XXX
 SG_ HdrestHeiAdjmtRowSecRi_UB : 34|1@0+ (1,0) [0|1] ""  Vector_XXX
 SG_ LegRestExtonAdjmtRowSecLe : 47|2@0+ (1,0) [0|3] ""  Vector_XXX
 SG_ LegRestExtonAdjmtRowSecLe_UB : 45|1@0+ (1,0) [0|1] ""  Vector_XXX
 SG_ LegRestExtonAdjmtRowSecRi : 44|2@0+ (1,0) [0|3] ""  Vector_XXX
 SG_ LegRestExtonAdjmtRowSecRi_UB : 42|1@0+ (1,0) [0|1] ""  Vector_XXX
 SG_ LenAdjmtRowSecLe : 1|2@0+ (1,0) [0|3] ""  Vector_XXX
 SG_ LenAdjmtRowSecLe_UB : 17|1@0+ (1,0) [0|1] ""  Vector_XXX
 SG_ LenAdjmtRowSecRi : 9|2@0+ (1,0) [0|3] ""  Vector_XXX
 SG_ LenAdjmtRowSecRi_UB : 16|1@0+ (1,0) [0|1] ""  Vector_XXX

BO_ 256 CEMBodyFr13: 8 CEM
 SG_ EgyCnsAllwdForClima : 30|7@0+ (1,0) [0|127] "Wh"  CCM
 SG_ EgyCnsAllwdForClima_UB : 31|1@0+ (1,0) [0|1] ""  CCM
 SG_ ExtrMirrAdjHmiReq : 39|3@0+ (1,0) [0|7] ""  DDM
 SG_ ExtrMirrAdjHmiReq_UB : 7|1@0+ (1,0) [0|1] ""  DDM
 SG_ ExtrMirrFoldHmiReq : 34|1@0+ (1,0) [0|1] ""  DDM
 SG_ ExtrMirrFoldHmiReq_UB : 23|1@0+ (1,0) [0|1] ""  DDM
 SG_ ExtrMirrFoldSetg_UB : 6|1@0+ (1,0) [0|1] ""  DDM
 SG_ ExtrMirrFoldSetgIdPen : 3|4@0+ (1,0) [0|15] ""  DDM
 SG_ ExtrMirrFoldSetgMirrDrvr : 4|1@0+ (1,0) [0|1] ""  DDM
 SG_ ExtrMirrFoldSetgMirrPass : 5|1@0+ (1,0) [0|1] ""  DDM
 SG_ ExtrMirrSelnHmiReq : 36|2@0+ (1,0) [0|3] ""  DDM
 SG_ ExtrMirrSelnHmiReq_UB : 47|1@0+ (1,0) [0|1] ""  DDM
 SG_ ExtrMirrTiltSetg_UB : 22|1@0+ (1,0) [0|1] ""  DDM
 SG_ ExtrMirrTiltSetgIdPen : 19|4@0+ (1,0) [0|15] ""  DDM
 SG_ ExtrMirrTiltSetgMirrDrvr : 20|1@0+ (1,0) [0|1] ""  DDM
 SG_ ExtrMirrTiltSetgMirrPass : 21|1@0+ (1,0) [0|1] ""  DDM
 SG_ IncomingAirQlyCtrlFromHmi : 33|1@0+ (1,0) [0|1] ""  CCM
 SG_ IncomingAirQlyCtrlFromHmi_UB : 32|1@0+ (1,0) [0|1] ""  CCM
 SG_ LockgCenSts_UB : 8|1@0+ (1,0) [0|1] ""  CCM,DDM,ILCM,PDM,RLDM,RRDM
 SG_ LockgCenStsLockSt : 11|2@0+ (1,0) [0|3] ""  CCM,DDM,ILCM,PDM,RLDM,RRDM
 SG_ LockgCenStsTrigSrc : 15|4@0+ (1,0) [0|15] ""  CCM,DDM,ILCM,PDM,RLDM,RRDM
 SG_ LockgCenStsUpdEve : 9|1@0+ (1,0) [0|1] ""  CCM,DDM,ILCM,PDM,RLDM,RRDM
 SG_ PrkgAssiSysRemPrkgSts : 43|4@0+ (1,0) [0|15] ""  DDM
 SG_ PrkgAssiSysRemPrkgSts_UB : 59|1@0+ (1,0) [0|1] ""  DDM
 SG_ RelHumSnsrQf : 46|1@0+ (1,0) [0|1] ""  CCM
 SG_ RelHumSnsrQf_UB : 63|1@0+ (1,0) [0|1] ""  CCM
 SG_ SteerWhlHeatgPwrAct : 55|8@0+ (1,0) [0|255] "Unitless"  CCM
 SG_ SteerWhlHeatgPwrAct_UB : 60|1@0+ (1,0) [0|1] ""  CCM

BO_ 320 CEMBodyFr14: 8 CEM
 SG_ CbnOverHeatProtnEna : 2|1@0+ (1,0) [0|1] ""  CCM
 SG_ CbnOverHeatProtnEna_UB : 13|1@0+ (1,0) [0|1] ""  CCM
 SG_ CmptmtCoolgSts : 23|4@0+ (1,0) [0|15] ""  CCM
 SG_ CmptmtCoolgSts_UB : 19|1@0+ (1,0) [0|1] ""  CCM
 SG_ FragRefrshAutSetg : 1|1@0+ (1,0) [0|1] ""  CCM
 SG_ FragRefrshAutSetg_UB : 12|1@0+ (1,0) [0|1] ""  CCM
 SG_ HmiDefrstMaxReq : 47|2@0+ (1,0) [0|3] ""  CCM
 SG_ HmiDefrstMaxReq_UB : 45|1@0+ (1,0) [0|1] ""  CCM
 SG_ HmiHvacFanLvlFrnt : 7|4@0+ (1,0) [0|15] ""  CCM
 SG_ HmiHvacFanLvlFrnt_UB : 3|1@0+ (1,0) [0|1] ""  CCM
 SG_ HmiHvacFanLvlRe : 51|4@0+ (1,0) [0|15] ""  CCM
 SG_ HmiHvacFanLvlRe_UB : 55|1@0+ (1,0) [0|1] ""  CCM
 SG_ HmiHvacRecircCmd : 53|2@0+ (1,0) [0|3] ""  CCM
 SG_ HmiHvacRecircCmd_UB : 54|1@0+ (1,0) [0|1] ""  CCM
 SG_ HmiHvacReCtrl : 63|2@0+ (1,0) [0|3] ""  CCM
 SG_ HmiHvacReCtrl_UB : 61|1@0+ (1,0) [0|1] ""  CCM
 SG_ HmiIImSptFragraReq : 0|1@0+ (1,0) [0|1] ""  CCM
 SG_ HmiIImSptFragraReq_UB : 11|1@0+ (1,0) [0|1] ""  CCM
 SG_ HvClimaCmd : 17|2@0+ (1,0) [0|3] ""  CCM
 SG_ HvClimaCmd_UB : 18|1@0+ (1,0) [0|1] ""  CCM
 SG_ HvCooltHeatrStsSig : 42|3@0+ (1,0) [0|7] ""  CCM
 SG_ HvCooltHeatrStsSig_UB : 43|1@0+ (1,0) [0|1] ""  CCM
 SG_ HvSysRlySts_UB : 30|1@0+ (1,0) [0|1] ""  CCM,SMD,SMP
 SG_ HvSysRlyStsChks : 39|8@0+ (1,0) [0|255] "Unitless"  CCM,SMD,SMP
 SG_ HvSysRlyStsCntr : 27|4@0+ (1,0) [0|15] "Unitless"  CCM,SMD,SMP
 SG_ HvSysRlyStsHvSysRlySts : 29|2@0+ (1,0) [0|3] ""  CCM,SMD,SMP
 SG_ IncomingAirQlyPopUpReq : 60|1@0+ (1,0) [0|1] ""  CCM
 SG_ IncomingAirQlyPopUpReq_UB : 59|1@0+ (1,0) [0|1] ""  CCM
 SG_ SecClimaAutoSet : 44|1@0+ (1,0) [0|1] ""  CCM
 SG_ SecClimaAutoSet_UB : 56|1@0+ (1,0) [0|1] ""  CCM
 SG_ TWinRfClsdPopUpReq : 15|1@0+ (1,0) [0|1] ""  CCM
 SG_ TWinRfClsdPopUpReq_UB : 14|1@0+ (1,0) [0|1] ""  CCM

BO_ 384 CEMBodyFr15: 8 CEM
 SG_ DrvrAirCdnrSetg_UB : 48|1@0+ (1,0) [0|1] ""  CCM
 SG_ DrvrAirCdnrSetgAirCdnrSetg : 59|2@0+ (1,0) [0|3] ""  CCM
 SG_ DrvrAirCdnrSetgIdPen : 63|4@0+ (1,0) [0|15] ""  CCM
 SG_ HmiCmptmtCoolgReq : 52|1@0+ (1,0) [0|1] ""  CCM
 SG_ HmiCmptmtCoolgReq_UB : 51|1@0+ (1,0) [0|1] ""  CCM
 SG_ HmiCmptmtTSp_UB : 7|1@0+ (1,0) [0|1] ""  CCM,ILCM
 SG_ HmiCmptmtTSpForRowFirstLe : 4|5@0+ (0.5,15) [15|30.5] "Deg"  CCM,ILCM
 SG_ HmiCmptmtTSpForRowFirstRi : 12|5@0+ (0.5,15) [15|30.5] "Deg"  CCM,ILCM
 SG_ HmiCmptmtTSpForRowSecLe : 20|5@0+ (0.5,15) [15|30.5] "Deg"  CCM,ILCM
 SG_ HmiCmptmtTSpForRowSecRi : 28|5@0+ (0.5,15) [15|30.5] "Deg"  CCM,ILCM
 SG_ HmiCmptmtTSpSpclForRowFirstLe : 6|2@0+ (1,0) [0|3] ""  CCM,ILCM
 SG_ HmiCmptmtTSpSpclForRowFirstRi : 14|2@0+ (1,0) [0|3] ""  CCM,ILCM
 SG_ HmiCmptmtTSpSpclForRowSecLe : 22|2@0+ (1,0) [0|3] ""  CCM,ILCM
 SG_ HmiCmptmtTSpSpclForRowSecRi : 30|2@0+ (1,0) [0|3] ""  CCM,ILCM
 SG_ HmiElecAirDrvrSwtReq : 40|1@0+ (1,0) [0|1] ""  CCM
 SG_ HmiElecAirDrvrSwtReq_UB : 41|1@0+ (1,0) [0|1] ""  CCM
 SG_ HmiElecAirPassSwtReq : 42|1@0+ (1,0) [0|1] ""  CCM
 SG_ HmiElecAirPassSwtReq_UB : 43|1@0+ (1,0) [0|1] ""  CCM
 SG_ HpcDeiceReq : 55|3@0+ (1,0) [0|7] ""  CCM
 SG_ HpcDeiceReq_UB : 50|1@0+ (1,0) [0|1] ""  CCM
 SG_ HpcHpCoolgPwrSts : 47|1@0+ (1,0) [0|1] ""  CCM
 SG_ HpcHpCoolgPwrSts_UB : 49|1@0+ (1,0) [0|1] ""  CCM
 SG_ HpcHpHeatgPwrSts : 46|1@0+ (1,0) [0|1] ""  CCM
 SG_ HpcHpHeatgPwrSts_UB : 45|1@0+ (1,0) [0|1] ""  CCM
 SG_ HpcHpModReq : 38|7@0+ (1,0) [0|127] ""  CCM
 SG_ HpcHpModReq_UB : 39|1@0+ (1,0) [0|1] ""  CCM
 SG_ TrlrLiRvsgActvt : 56|1@0+ (1,0) [0|1] ""  TRM
 SG_ TrlrLiRvsgActvt_UB : 57|1@0+ (1,0) [0|1] ""  TRM

CM_ SG_ 1120 CmprReqAcCapReqOvr "request aircond compressor displacement duty override.";
CM_ SG_ 1120 CmptmtClngPreStrtReq "Activate function clean compartment.";
CM_ SG_ 1120 SecRowLeDefdMassgProgCfgMassgBag "to confirm if the pneumatic bags 01 is selected ";
CM_ SG_ 1120 SecRowLeDefdMassgProgCfgMas_0000 "to confirm if the pneumatic bags 02 is selected ";
CM_ SG_ 1120 SecRowLeDefdMassgProgCfgMas_0001 "to confirm if the pneumatic bags 03 is selected ";
CM_ SG_ 1120 SecRowLeDefdMassgProgCfgMas_0002 "to confirm if the pneumatic bags 04 is selected ";
CM_ SG_ 1120 SecRowLeDefdMassgProgCfgMas_0003 "to confirm if the pneumatic bags 05 is selected ";
CM_ SG_ 1120 SecRowLeDefdMassgProgCfgMas_0004 "to confirm if the pneumatic bags 06 is selected ";
CM_ SG_ 1120 SecRowLeDefdMassgProgCfgMas_0005 "to confirm if the pneumatic bags 07 is selected ";
CM_ SG_ 1120 SecRowLeDefdMassgProgCfgMas_0006 "to confirm if the pneumatic bags 08 is selected ";
CM_ SG_ 1120 SecRowLeDefdMassgProgCfgMas_0007 "to confirm if the pneumatic bags 09 is selected ";
CM_ SG_ 1120 SecRowLeDefdMassgProgCfgMas_0008 "to confirm if the pneumatic bags 10 is selected ";
CM_ SG_ 1120 SecRowLeDefdMassgProgCfgMas_0009 "to confirm if the pneumatic bags 11 is selected ";
CM_ SG_ 1120 SecRowLeDefdMassgProgCfgMas_0010 "to confirm if the pneumatic bags 12 is selected ";
CM_ SG_ 1120 SecRowLeDefdMassgProgCfgMas_0011 "to confirm if the pneumatic bags 13 is selected ";
CM_ SG_ 1120 SecRowLeDefdMassgProgCfgMas_0012 "to confirm if the pneumatic bags 14 is selected ";
CM_ SG_ 1120 SecRowLeDefdMassgProgCfgMas_0013 "to confirm if the pneumatic bags 15 is selected ";
CM_ SG_ 1120 SecRowLeDefdMassgProgCfgMas_0014 "to confirm if the pneumatic bags 16 is selected ";
CM_ SG_ 1120 SecRowLeDefdMassgProgCfgMassgFrq "different levels of frequency could be selected";
CM_ SG_ 1120 SecRowLeDefdMassgProgCfgMassgInt "different levels of strength could be selected";
CM_ SG_ 1120 SecRowLeDefdMassgProgCfgMassProg "to store the customized massage Program ID";
CM_ SG_ 1120 SecRowLeDefdMassgProgCfgMas_0015 "used for configuring/remove/save functions";
CM_ SG_ 1120 SecRowLeDefdMassgProgCfgMassSeqC "to store the sequence ID in each customized massage Program";
CM_ SG_ 1171 AmbTRawAmbTVal "Unfiltered ambient temp raw data in deg C. Ambient temp value";
CM_ SG_ 1171 AmbTRawQly "Unfiltered ambient temp raw data in deg C. Quality Factor of the ambient temp";
CM_ SG_ 1171 BltLockStAtDrvrBltLockSt1 "State of belt lock at driver seating position Belt lock state, locked/unlocked";
CM_ SG_ 1171 BltLockStAtDrvrBltLockSts "State of belt lock at driver seating position Belt lock status, OK/NOK";
CM_ SG_ 1171 BltLockStAtPassBltLockSt1 "State of belt lock at passenger seating position Belt lock state, locked/unlocked";
CM_ SG_ 1171 BltLockStAtPassBltLockSts "State of belt lock at passenger seating position Belt lock status, OK/NOK";
CM_ SG_ 1171 BltLockStAtRowSecLeBltLockEquid "State of belt lock at seating position at left of second row If the belt lock is equipped";
CM_ SG_ 1171 BltLockStAtRowSecLeBltLockSt1 "State of belt lock at seating position at left of second row Belt lock state,  locked/unlocked";
CM_ SG_ 1171 BltLockStAtRowSecLeBltLockSts "State of belt lock at seating position at left of second row Belt lock status, OK/NOK";
CM_ SG_ 1171 BltLockStAtRowSecMidBltLockEquid "State of belt lock at seating position at middle of second row If the belt lock is equipped";
CM_ SG_ 1171 BltLockStAtRowSecMidBltLockSt1 "State of belt lock at seating position at middle of second row Belt lock state,  locked/unlocked";
CM_ SG_ 1171 BltLockStAtRowSecMidBltLockSts "State of belt lock at seating position at middle of second row Belt lock status, OK/NOK";
CM_ SG_ 1171 BltLockStAtRowSecRiBltLockEquid "State of belt lock at seating position at right of second row If the belt lock is equipped";
CM_ SG_ 1171 BltLockStAtRowSecRiBltLockSt1 "State of belt lock at seating position at right of second row Belt lock state,  locked/unlocked";
CM_ SG_ 1171 BltLockStAtRowSecRiBltLockSts "State of belt lock at seating position at right of second row Belt lock status, OK/NOK";
CM_ SG_ 1171 BltLockStAtRowThrdLeBltLockEquid "State of belt lock at seating position at left of third row If the belt lock is equipped";
CM_ SG_ 1171 BltLockStAtRowThrdLeBltLockSt1 "State of belt lock at seating position at left of third row Belt lock state,  locked/unlocked";
CM_ SG_ 1171 BltLockStAtRowThrdLeBltLockSts "State of belt lock at seating position at left of third row Belt lock status, OK/NOK";
CM_ SG_ 1171 BltLockStAtRowThrdRiBltLockEquid "State of belt lock at seating position at right of third row If the belt lock is equipped";
CM_ SG_ 1171 BltLockStAtRowThrdRiBltLockSt1 "State of belt lock at seating position at right of third row Belt lock state,  locked/unlocked";
CM_ SG_ 1171 BltLockStAtRowThrdRiBltLockSts "State of belt lock at seating position at right of third row Belt lock status, OK/NOK";
CM_ SG_ 1171 CooltHeatrTIntk "Coolant temperature at  intake of heater.";
CM_ SG_ 1171 CooltHeatrTOutl "Coolant temperature at outlet of heater.";
CM_ SG_ 1171 DrvrPfmncAlrmReq " the warning level of driver";
CM_ SG_ 1171 RemChkTInVeh "Remote Check Temperature In Vehicle";
CM_ SG_ 65 ChdLockReLeCtrlHmiReq "Child lock rear left lock or unlock request";
CM_ SG_ 65 ChdLockReRiCtrlHmiReq "Child lock rear right lock or unlock request";
CM_ SG_ 65 HmiSeatClimaTmrHmiSeatHeatgFirst "Hmi set timer for seat heat and ventilation";
CM_ SG_ 65 HmiSeatClimaTmrHmiSeatHeatg_0000 "Hmi set timer for seat heat and ventilation";
CM_ SG_ 65 HmiSeatClimaTmrHmiSeatHeatgSecLe "Hmi set timer for seat heat and ventilation";
CM_ SG_ 65 HmiSeatClimaTmrHmiSeatHeatgSecRi "Hmi set timer for seat heat and ventilation";
CM_ SG_ 65 HmiSeatClimaTmrHmiSeatVentnFirst "Hmi set timer for seat heat and ventilation";
CM_ SG_ 65 HmiSeatClimaTmrHmiSeatVentn_0000 "Hmi set timer for seat heat and ventilation";
CM_ SG_ 65 HmiSeatClimaTmrHmiSeatVentnSecLe "Hmi set timer for seat heat and ventilation";
CM_ SG_ 65 HmiSeatClimaTmrHmiSeatVentnSecRi "Hmi set timer for seat heat and ventilation";
CM_ SG_ 65 HmiSeatClimaTmrIdPen "Hmi set timer for seat heat and ventilation";
CM_ SG_ 1196 DrvrSeatHallPosDownLdSeatFrntHei "Seat Front Height Position";
CM_ SG_ 1196 DrvrSeatHallPosDownLdSeatHeiPos "Seat Height Position";
CM_ SG_ 1196 DrvrSeatHallPosDownLdSeatInclPos "Seat Inclanation Position";
CM_ SG_ 1196 DrvrSeatHallPosDownLdSeatSldPos "Seat Slide Position";
CM_ SG_ 234 DoorSldngLeReReqChks "Checksum for E2E";
CM_ SG_ 234 DoorSldngLeReReqCntr "Counter for E2E";
CM_ SG_ 234 DoorSldngLeReReqDoorOpenerReq "DoorOpenerReq

DoorOpenerIdle - No request
DoorOpenerOpen - Request to Open
DoorOpenerCls - Request to Close
DoorOpenerStop - Request to stop any ongoing sliding door movement";
CM_ SG_ 234 DoorSldngLeReReqTrigSrc "TrigSrc
NoTrigSrc - No trig source
KeyRem - Remote Key
IntrDisp - Interior display
Telm - Telematics
HandlOutd - Outer door handle
HandlInsd - Inside door handle
BrkPedl - Brake pedal press
VoiceCmd - Voice command
ManF - Manual force";
CM_ SG_ 234 DoorSldngRiReReqChks "Checksum for E2E";
CM_ SG_ 234 DoorSldngRiReReqCntr "Counter for E2E";
CM_ SG_ 234 DoorSldngRiReReqDoorOpenerReq "DoorOpenerReq

DoorOpenerIdle - No request
DoorOpenerOpen - Request to Open
DoorOpenerCls - Request to Close
DoorOpenerStop - Request to stop any ongoing sliding door movement";
CM_ SG_ 234 DoorSldngRiReReqTrigSrc "TrigSrc
NoTrigSrc - No trig source
KeyRem - Remote Key
IntrDisp - Interior display
Telm - Telematics
HandlOutd - Outer door handle
HandlInsd - Inside door handle
BrkPedl - Brake pedal press
VoiceCmd - Voice command
ManF - Manual force";
CM_ SG_ 234 FirstRowLeDefdMassgProgSeln "The selection for customized-/defaulted Massage function could be differentiated for driver seat";
CM_ SG_ 234 FirstRowRiDefdMassgProgSeln "The selection for customized-/defaulted Massage function could be differentiated for passager seat";
CM_ SG_ 234 FRDSDoorOpenInd "Door open lamp indicator sent to FRDS";
CM_ SG_ 234 FRDSLockgSts "Lamp indicator of locking status in Passenger door";
CM_ SG_ 234 TrsmParkLockdChks "Checksum for TrsmParkLockd";
CM_ SG_ 234 TrsmParkLockdCntr "Counter for TrsmParkLockd";
CM_ SG_ 234 TrsmParkLockdTrsmParkLockd "Transmission park lock status";
CM_ SG_ 91 HvBattLimnIndcn "Propulsion related LOS (Limited Operation Strategy) information from Hv Battery. LOS";
CM_ SG_ 91 SeatFoldRaiseReqRowSecLe "seat fold req";
CM_ SG_ 91 SeatFoldRaiseReqRowSecMid "seat fold req";
CM_ SG_ 91 SeatFoldRaiseReqRowSecRi "seat fold req";
CM_ SG_ 91 SeatFoldRaiseReqRowThrdLe "seat fold req";
CM_ SG_ 91 SeatFoldRaiseReqRowThrdRi "seart fold req";
CM_ SG_ 91 ShortDropWinDrvrDoor "Driver window short drop request to open-close frameless doors. Idleshort drop (No request), ShorDropClose (short drop requested when door close), ShortDropOpen (Short Drop requested when door open)";
CM_ SG_ 91 ShortDropWinLeReDoor "Left Rear window short drop request to open-close frameless doors. Idleshort drop (No request), ShorDropClose (short drop requested when door close), ShortDropOpen (Short Drop requested when door open)";
CM_ SG_ 91 ShortDropWinPassDoor "Passenger window short drop request to open-close frameless doors. Idleshort drop (No request), ShorDropClose (short drop requested when door close), ShortDropOpen (Short Drop requested when door open)";
CM_ SG_ 91 ShortDropWinRiReDoor "Right Rear window short drop request to open-close frameless doors. Idleshort drop (No request), ShorDropClose (short drop requested when door close), ShortDropOpen (Short Drop requested when door open)";
CM_ SG_ 132 LeReWinBtnDwn "down";
CM_ SG_ 132 LeReWinBtnRise "rise";
CM_ SG_ 132 MusicInfoForMusicShow2DownSampli "The down-sampling amplitude of 10ms raw PCM audio data ";
CM_ SG_ 132 MusicInfoForMusicShow2MaxFFT100m "The amplitude of max amplitude-frequency point among
100Hz-2.65kHz,";
CM_ SG_ 132 MusicInfoForMusicShow2MaxFF_0000 "The frequency of max amplitude-frequency point among
100Hz-2.65kHz,";
CM_ SG_ 132 MusicInfoForMusicShow2Segment1FF "10ms amplitude-frequency results of 1st segment";
CM_ SG_ 132 MusicInfoForMusicShow2Segment2FF "10ms amplitude-frequency results of 2nd segment";
CM_ SG_ 132 MusicInfoForMusicShow2Segment3FF "10ms amplitude-frequency results of 3rd segment";
CM_ SG_ 132 MusicInfoForMusicShow2Segment4FF "10ms amplitude-frequency results of 4th segment";
CM_ SG_ 132 MusicInfoForMusicShow2Segment5FF "10ms amplitude-frequency results of 5th segment";
CM_ SG_ 132 MusicInfoForMusicShow2Segment6FF "10ms amplitude-frequency results of 6th segment";
CM_ SG_ 132 MusicInfoForMusicShow2Segment7FF "10ms amplitude-frequency results of 7th segment";
CM_ SG_ 132 MusicInfoForMusicShow2Segment8FF "10ms amplitude-frequency results of 8th segment";
CM_ SG_ 132 MusicInfoForMusicShow2StateFlagA "The flag of audio playing status";
CM_ SG_ 132 MusicInfoForMusicShow2StateFlagN "The flag of a new audio";
CM_ SG_ 132 MusicInfoForMusicShow2TimeFlagAu "The time stamp of the playing audio";
CM_ SG_ 132 MusicInfoForMusicShow2TimeFlagMe "The time stamp of data transmission";
CM_ SG_ 136 MusicInfoForMusicShow3DownSampli "The down-sampling amplitude of 10ms raw PCM audio data ";
CM_ SG_ 136 MusicInfoForMusicShow3MaxFFT100m "The amplitude of max amplitude-frequency point among
100Hz-2.65kHz,";
CM_ SG_ 136 MusicInfoForMusicShow3MaxFF_0000 "The frequency of max amplitude-frequency point among
100Hz-2.65kHz,";
CM_ SG_ 136 MusicInfoForMusicShow3Segment1FF "10ms amplitude-frequency results of 1st segment";
CM_ SG_ 136 MusicInfoForMusicShow3Segment2FF "10ms amplitude-frequency results of 2nd segment";
CM_ SG_ 136 MusicInfoForMusicShow3Segment3FF "10ms amplitude-frequency results of 3rd segment";
CM_ SG_ 136 MusicInfoForMusicShow3Segment4FF "10ms amplitude-frequency results of 4th segment";
CM_ SG_ 136 MusicInfoForMusicShow3Segment5FF "10ms amplitude-frequency results of 5th segment";
CM_ SG_ 136 MusicInfoForMusicShow3Segment6FF "10ms amplitude-frequency results of 6th segment";
CM_ SG_ 136 MusicInfoForMusicShow3Segment7FF "10ms amplitude-frequency results of 7th segment";
CM_ SG_ 136 MusicInfoForMusicShow3Segment8FF "10ms amplitude-frequency results of 8th segment";
CM_ SG_ 136 MusicInfoForMusicShow3StateFlagA "The flag of audio playing status";
CM_ SG_ 136 MusicInfoForMusicShow3StateFlagN "The flag of a new audio";
CM_ SG_ 136 MusicInfoForMusicShow3TimeFlagAu "The time stamp of the playing audio";
CM_ SG_ 136 MusicInfoForMusicShow3TimeFlagMe "The time stamp of data transmission";
CM_ SG_ 136 RiReWinBtnDwn "down";
CM_ SG_ 136 RiReWinBtnRise "rise
";
CM_ SG_ 139 MusicInfoForMusicShow4DownSampli "The down-sampling amplitude of 10ms raw PCM audio data ";
CM_ SG_ 139 MusicInfoForMusicShow4MaxFFT100m "The amplitude of max amplitude-frequency point among
100Hz-2.65kHz,";
CM_ SG_ 139 MusicInfoForMusicShow4MaxFF_0000 "The frequency of max amplitude-frequency point among
100Hz-2.65kHz,";
CM_ SG_ 139 MusicInfoForMusicShow4Segment1FF "10ms amplitude-frequency results of 1st segment";
CM_ SG_ 139 MusicInfoForMusicShow4Segment2FF "10ms amplitude-frequency results of 2nd segment";
CM_ SG_ 139 MusicInfoForMusicShow4Segment3FF "10ms amplitude-frequency results of 3rd segment";
CM_ SG_ 139 MusicInfoForMusicShow4Segment4FF "10ms amplitude-frequency results of 4th segment";
CM_ SG_ 139 MusicInfoForMusicShow4Segment5FF "10ms amplitude-frequency results of 5th segment";
CM_ SG_ 139 MusicInfoForMusicShow4Segment6FF "10ms amplitude-frequency results of 6th segment";
CM_ SG_ 139 MusicInfoForMusicShow4Segment7FF "10ms amplitude-frequency results of 7th segment";
CM_ SG_ 139 MusicInfoForMusicShow4Segment8FF "10ms amplitude-frequency results of 8th segment";
CM_ SG_ 139 MusicInfoForMusicShow4StateFlagA "The flag of audio playing status";
CM_ SG_ 139 MusicInfoForMusicShow4StateFlagN "The flag of a new audio";
CM_ SG_ 139 MusicInfoForMusicShow4TimeFlagAu "The time stamp of the playing audio";
CM_ SG_ 139 MusicInfoForMusicShow4TimeFlagMe "The time stamp of data transmission";
CM_ SG_ 960 HmiPassTempSyncSet "Passenger Temp Sync Setting management check seat whether have a person";
CM_ SG_ 960 LegRestRotAdjmtRowSecLe "The second row left seat leg rest rotiation(up/down) adjustment";
CM_ SG_ 960 LegRestRotAdjmtRowSecRi "The second row right seat leg rest rotiation(up/down) adjustment";
CM_ SG_ 960 VehTiAndDataDataValid "Vehicle time (Hr, Min and Sec) and date (Year, Months and days) data for indication. See requirement for more information about the signals. Signal qualifier, No means values should be ignored.";
CM_ SG_ 960 VehTiAndDataDay "Vehicle time (Hr, Min and Sec) and date (Year, Months and days) data for indication. See requirement for more information about the signals. Day";
CM_ SG_ 960 VehTiAndDataHr1 "Vehicle time (Hr, Min and Sec) and date (Year, Months and days) data for indication. See requirement for more information about the signals. Hour";
CM_ SG_ 960 VehTiAndDataMins1 "Vehicle time (Hr, Min and Sec) and date (Year, Months and days) data for indication. See requirement for more information about the signals. Minutes";
CM_ SG_ 960 VehTiAndDataMth1 "Vehicle time (Hr, Min and Sec) and date (Year, Months and days) data for indication. See requirement for more information about the signals. Month, 1-12";
CM_ SG_ 960 VehTiAndDataSec1 "Vehicle time (Hr, Min and Sec) and date (Year, Months and days) data for indication. See requirement for more information about the signals. Seconds";
CM_ SG_ 960 VehTiAndDataYr1 "Vehicle time (Hr, Min and Sec) and date (Year, Months and days) data for indication. See requirement for more information about the signals. Year, 0-99";
CM_ SG_ 243 ActvnOfPudLi "Activate Puddle light";
CM_ SG_ 243 CushExtnSecRowLe "the cushion extension of second row left";
CM_ SG_ 243 CushExtnSecRowRi "the cushion extension of second row right";
CM_ SG_ 243 HmiElecAirFrntSwtReqHmiElecAirDr "open/close the each electric air ventilation in front driver seat Left";
CM_ SG_ 243 HmiElecAirFrntSwtReqHmiElec_0000 "open/close the each electric air ventilation in front driver seat right";
CM_ SG_ 243 HmiElecAirFrntSwtReqHmiElecAirPa "open/close the each electric air ventilation in front passenger seat Left";
CM_ SG_ 243 HmiElecAirFrntSwtReqHmiElec_0001 "open/close the each electric air ventilation in front passenger seat right";
CM_ SG_ 243 HmiElecAirReSwtReqHmiElecAirReLe "open/close the each electric air ventilation in rear seat Left";
CM_ SG_ 243 HmiElecAirReSwtReqHmiElecAirReRi "open/close the each electric air ventilation in rear seat right";
CM_ SG_ 243 RearWinDimEna "enable signal for window dimming system";
CM_ SG_ 243 RollAgGlbQf "Lateral inclination of vehicle against horizon Qualifier flag";
CM_ SG_ 243 RollAgGlbVal "Lateral inclination of vehicle against horizon Roll angle in radians";
CM_ SG_ 243 SecRowLeLoadAndStoreReqErgoPosn "EgroPosn is second-row-seat,memory position signal, contain PassMemPosn.Idle,PassMemPosn.MemBnk1,PassMemPosn.MemBnk2,PassMemPosn.MemBnk3.";
CM_ SG_ 243 SecRowLeLoadAndStoreReqErgoSetgE "ErgoSetgEve is contains five command signal,EveMemPosn.Idle,EveMemPosn.Store,EveMemPosn.Load, EveMemPosn.Stop, EveMemPosn.AutMovmt";
CM_ SG_ 243 SecRowRiLoadAndStoreReqErgoPosn "EgroPosn is second-row-seat,memory position signal, contain PassMemPosn.Idle,PassMemPosn.MemBnk1,PassMemPosn.MemBnk2,PassMemPosn.MemBnk3.";
CM_ SG_ 243 SecRowRiLoadAndStoreReqErgoSetgE "ErgoSetgEve is contains five command signal,EveMemPosn.Idle,EveMemPosn.Store,EveMemPosn.Load, EveMemPosn.Stop, EveMemPosn.AutMovmt";
CM_ SG_ 243 SecRowRiSeatDispMassgFctMassgInt "Massage program Intensity Level";
CM_ SG_ 243 SecRowRiSeatDispMassgFctMassgPro "Massage Programs Types";
CM_ SG_ 243 SecRowRiSeatDispMassgFctOnOff "Turn on or off seat massage";
CM_ SG_ 243 ShoulderAdjmtRowSecLe "The second row left seat shoulder side support adjustment";
CM_ SG_ 243 ShoulderAdjmtRowSecRi "The second row right seat shoulder side support adjustment";
CM_ SG_ 818 HmiCmptmtSecRowLeAirDistbn "HMI compartment second row left air distribution ";
CM_ SG_ 818 HmiCmptmtSecRowRiAirDistbn "HMI compartment second row right air distribution";
CM_ SG_ 818 HmiDrvrClimaAutReq "HMI Driver Climatisation Automatic Request";
CM_ SG_ 818 HmiDrvrHvacFanLvl "HMI Driver Hvac Fan Level";
CM_ SG_ 818 HmiPassClimaAutReq "HMI Passenger Climatisation Automatic Request";
CM_ SG_ 818 HmiPassHvacFanLvl "HMI Driver Hvac Fan Level";
CM_ SG_ 818 HmiSecRowLeClimaAutReq "HMI second row left Climatisation Automatic Request ";
CM_ SG_ 818 HmiSecRowLeHvacFanLvl "HMI second row left Hvac Fan Level 
";
CM_ SG_ 818 HmiSecRowRiClimaAutReq "HMI second row right Climatisation Automatic Request";
CM_ SG_ 818 HmiSecRowRiHvacFanLvl "HMI second row Right Hvac Fan Level ";
CM_ SG_ 224 DoorPassSts "DoorPassSts - Passenger Door Status
Ukwn - Unknown status
Opend - Opened
Clsd - Closed";
CM_ SG_ 224 DoorRiReSts "DoorRiReSts - Right Rear Side Door Status
Ukwn - Unknown status
Opend - Opened
Clsd - Closed";
CM_ SG_ 224 HvPwrAvlForClimaEstimd "An estimation of how much HV-power that is available for climatization.";
CM_ SG_ 224 IntrBriSts "Rheostat setting. Set by user through rheostat wheel situated on MyCar Module.";
CM_ SG_ 224 MirrTintgCmd "Dimming level of the outer rear view mirrors. 0-100%.";
CM_ SG_ 224 SecRowLeSeatDispSpplFct "Handles the two way communication for second row left multi seat control.";
CM_ SG_ 224 SecRowRiSeatDispSpplFct "Handles the two way communication for second row right multi seat control.";
CM_ SG_ 224 SecRowSeatDispBtnPsdSecRowLeSeat "Second row the left seat display button pressed";
CM_ SG_ 224 SecRowSeatDispBtnPsdSecRowRiSeat "Second row the right seat display button pressed";
CM_ SG_ 224 SteerWhlHeatgDesPwr "Desired power consumption for steering wheel heating activation.";
CM_ SG_ 224 TopPosTrFromHmi "This signal is used to set top position of tailgate";
CM_ SG_ 224 TrlrLampChkReqFromHmi "Distribution of trailer lamp check activation from DIM";
CM_ SG_ 224 TrlrLiFogActvt "Controls the trailer foglight on and off.";
CM_ SG_ 224 TrPosnUpprProgmReq "TrPosnUpprProgmReq - Tailgate Upper Position Program Request
POT shall program upper position when this signal changes value from Off to On.";
CM_ SG_ 224 TrSts "TrSts - Tailgate or Bootlid Status
Ukwn - Unknown status
Opend - Opened
Clsd - Closed";
CM_ SG_ 27 ReadLiStsFirstRowLe "First row left reading light lamp status information ";
CM_ SG_ 27 ReadLiStsFirstRowRi "First row right reading light lamp status information ";
CM_ SG_ 27 ReadLiStsSecondRowLe "Second row left reading light lamp status information ";
CM_ SG_ 27 ReadLiStsSecondRowRi "Second row right reading light lamp status information ";
CM_ SG_ 27 ReadLiStsThirdRowLe "Third row left reading light lamp status information ";
CM_ SG_ 27 ReadLiStsThirdRowRi "Third row right reading light lamp status information ";
CM_ SG_ 629 HVACAirFlwAvailCold "Maximum airflow available for the cabin from the cold side of the HVAC";
CM_ SG_ 629 HVACAirFlwAvailWarm "Maximum airflow available for the cabin from the warm side of the HVAC";
CM_ SG_ 629 HVACColdAirTAct "Actual air temperature from the cold side of the HVAC";
CM_ SG_ 629 HVACWarmAirTAct "Actual air temperature from the warm side of the HVAC";
CM_ SG_ 1375 VinBlockNr "VIN number block counter. ";
CM_ SG_ 1375 VinVINSignalPos1 "VIN byte 1. Used for character 1, 8 and 15.";
CM_ SG_ 1375 VinVINSignalPos2 "VIN byte 2. Used for character 2, 9 and 16.";
CM_ SG_ 1375 VinVINSignalPos3 "VIN byte 3. Used for character 3, 10 and 17.";
CM_ SG_ 1375 VinVINSignalPos4 "VIN byte 4. Used for character 4 and 11.";
CM_ SG_ 1375 VinVINSignalPos5 "VIN byte 5. Used for character 5 and 12.";
CM_ SG_ 1375 VinVINSignalPos6 "VIN byte 6. Used for character 6 and 13.";
CM_ SG_ 1375 VinVINSignalPos7 "VIN byte 7. Used for character 7 and 14.";
CM_ SG_ 576 AmbLiThemeModSelnReqAmbLiTheme "After user select theme mode, HMI send which theme user select";
CM_ SG_ 576 AmbLiThemeModSelnReqIdPen "After user select theme mode, HMI send which theme user select";
CM_ SG_ 576 OneKeyAdjAllSeatDftPosn "One-key to recover all seat to default position";
CM_ SG_ 576 OneKeyAdjPassSeatFwdPosn "One-key to adjust passseat to forward position";
CM_ SG_ 576 Zone4SettingsBlue "Color, intensity and status settings for zone 4";
CM_ SG_ 576 Zone4SettingsGreen "Color, intensity and status settings for zone 4";
CM_ SG_ 576 Zone4SettingsIdPen "Color, intensity and status settings for zone 4";
CM_ SG_ 576 Zone4SettingsIntensity "Color, intensity and status settings for zone 4";
CM_ SG_ 576 Zone4SettingsRed "Color, intensity and status settings for zone 4";
CM_ SG_ 576 Zone4SettingsZoneStatus "Color, intensity and status settings for zone 4";
CM_ SG_ 592 AmbLiSpeechCorrlnReqIdPen "Open or close ambience light speech correlation";
CM_ SG_ 592 AmbLiSpeechCorrlnReqOnOff1 "Open or close ambience light speech correlation";
CM_ SG_ 592 DrvrSeatFldUnfld "Driver seat Fold or Unfold request.";
CM_ SG_ 592 DrvrSeatHMIpivtCntrl "Driver seat pivot request.";
CM_ SG_ 592 DrvrSeatSts "Describes if an occupant is detected in the driver seat.";
CM_ SG_ 592 RoadInclnForPOD "Estimated Road inclination used to inform Power operated doors (POD).

From -14 to 14 in intervals of 2 degrees.";
CM_ SG_ 592 RollAgGlbForPOD "Estimated roll angle of chassis used to inform Power operated doors (POD).

From -14 to 14 in intervals of 2 degrees.";
CM_ SG_ 592 Zone5SettingsBlue "Color, intensity and status settings for zone 5";
CM_ SG_ 592 Zone5SettingsGreen "Color, intensity and status settings for zone 5";
CM_ SG_ 592 Zone5SettingsIdPen "Color, intensity and status settings for zone 5";
CM_ SG_ 592 Zone5SettingsIntensity "Color, intensity and status settings for zone 5";
CM_ SG_ 592 Zone5SettingsRed "Color, intensity and status settings for zone 5";
CM_ SG_ 592 Zone5SettingsZoneStatus "Color, intensity and status settings for zone 5";
CM_ SG_ 704 HmiReElecAirDirCrtlReqSecRowLePo "HMI request manual control electric air ventilation direction for rear seat of second row left in X coordinate";
CM_ SG_ 704 HmiReElecAirDirCrtlReqSecRo_0000 "HMI request manual control electric air ventilation direction for rear seat left of second row in X coordinate";
CM_ SG_ 704 HmiReElecAirDirCrtlReqSecRowRiPo "HMI request manual control electric air ventilation direction for rear seat of second row right in X coordinate";
CM_ SG_ 704 HmiReElecAirDirCrtlReqSecRo_0001 "HMI request manual control electric air ventilation direction for rear seat of second row right in Y coordinate";
CM_ SG_ 529 AirClngReq "to switch on/off the air cleaning with ionizer";
CM_ SG_ 529 AmbLiBriAutAdjmtCenDispBriSnsrRa "according to the values of the sensor, the level of brightness to provide to adjust the ambiance light automaticlly  ";
CM_ SG_ 529 AmbLiBriAutAdjmtIdPen "to store the profil ID";
CM_ SG_ 529 AmbLiBriAutAdjmtOnOff1 "provide the soft button to switch on/off the automatic brightness adjustment ";
CM_ SG_ 529 AmbLiChrgCorrlnReqIdPen "Open or close ambience light indication when charging.";
CM_ SG_ 529 AmbLiChrgCorrlnReqOnOff1 "Open or close ambience light indication when charging.";
CM_ SG_ 529 AmbLiClimateCorrlnReqIdPen "Open or close ambience light HVAC correlation.";
CM_ SG_ 529 AmbLiClimateCorrlnReqOnOff1 "Open or close ambience light HVAC correlation.";
CM_ SG_ 529 AmbLiDrvModCorrlnReqIdPen "Open or close ambience light indication when drive mode changes.";
CM_ SG_ 529 AmbLiDrvModCorrlnReqOnOff1 "Open or close ambience light indication when drive mode changes.";
CM_ SG_ 529 AmbLiModAmbLiMod "Ambient light mode setting";
CM_ SG_ 529 AmbLiModIdPen "Ambient light mode setting";
CM_ SG_ 529 AmbLiStrtCorrlnReqIdPen "Open or close ambience light indication when start vehicle.";
CM_ SG_ 529 AmbLiStrtCorrlnReqOnOff1 "Open or close ambience light indication when start vehicle.";
CM_ SG_ 529 AmbLiStyleSelnReqIdPen "Select color style";
CM_ SG_ 529 AmbLiStyleSelnReqScene "Select color style";
CM_ SG_ 641 ExtSysClimaAirDist "Air Distribution requested from Vehicle API";
CM_ SG_ 641 ExtSysClimaAutDefrst "Request to enable auto defrost from Vehicle API";
CM_ SG_ 641 ExtSysClimaFanLvlFanLvlFrntRowLe "Auto fan level front row left seat";
CM_ SG_ 641 ExtSysClimaFanLvlFanLvlFrntRowRi "Auto fan level front row right seat";
CM_ SG_ 641 ExtSysClimaFanLvlFanLvlSecRowLef "Auto fan level second row left seat";
CM_ SG_ 641 ExtSysClimaFanLvlFanLvlSecRowRig "Auto fan level second row right seat";
CM_ SG_ 641 ExtSysClimaModes "Climate Mode option from vehicle API";
CM_ SG_ 641 ExtSysClimaRecirc "Full Recirculation requested from vehicle API";
CM_ SG_ 641 ExtSysClimaReq "Activation of Cabin climate from Vehicle API";
CM_ SG_ 641 ExtSysClimaTempSpTempFrntRowLeft "Temperature setpoint front row left seat";
CM_ SG_ 641 ExtSysClimaTempSpTempFrntRowRigh "Temperature setpoint front row right seat";
CM_ SG_ 641 ExtSysClimaTempSpTempSecRowLeft "Temperature setpoint second row left seat";
CM_ SG_ 641 ExtSysClimaTempSpTempSecRowRight "Temperature setpoint second row right seat";
CM_ SG_ 392 DISClimaCmptTempSp "DIS Climate Compartment Temperature Set Point";
CM_ SG_ 392 DISClimaDefrstReq "DIS Climate Defrost Request";
CM_ SG_ 392 DISClimaFanLvl "DIS Climate Fan Level";
CM_ SG_ 392 DISClimaRecircReq "DIS Climate Recirculation Request";
CM_ SG_ 392 DoorSwipDrvrOperReqChks "Checksum";
CM_ SG_ 392 DoorSwipDrvrOperReqCntr "Counter";
CM_ SG_ 392 DoorSwipDrvrOperReqDoorOpenerReq "Operation request to driver door";
CM_ SG_ 392 DoorSwipDrvrOperReqTrigSrc "Trigger Source";
CM_ SG_ 392 DoorSwipLeReOperReqChks "Checksum";
CM_ SG_ 392 DoorSwipLeReOperReqCntr "Counter";
CM_ SG_ 392 DoorSwipLeReOperReqDoorOpenerReq "Door operation request to Left Rear door";
CM_ SG_ 392 DoorSwipLeReOperReqTrigSrc "Trigger Source";
CM_ SG_ 392 PassSeatHMIpivtCntrl "passenger seat pivot request.";
CM_ SG_ 392 SwipDoorDrvrDisb "Swiping Driver door disabled";
CM_ SG_ 392 SwipDoorLeReDisb "Swiping Left Reardoor disabled";
CM_ SG_ 392 SwipDoorPassDisb "Swiping Passenger door disabled";
CM_ SG_ 392 SwipDoorRiReDisb "Swiping Right Rear door disabled";
CM_ SG_ 613 FLDSDoorOpenInd "Door open lamp indicator sent to FLDS";
CM_ SG_ 613 FLDSLockgSts "Lamp indicator of locking status in Driver door";
CM_ SG_ 613 PassSeatFldUnfld "Passenger seat fold and unfold request.";
CM_ SG_ 613 RLDSDoorOpenInd "Door open lamp indicator sent to RLDS";
CM_ SG_ 613 RLDSLockgSts "Lamp indicator of locking status in Rear left door";
CM_ SG_ 613 RRDSDoorOpenInd "Door open lamp indicator sent to RRDS";
CM_ SG_ 613 RRDSLockgSts "Lamp indicator of locking status in Rear right door";
CM_ SG_ 240 DoorDrvrHndlCmd "Shall send command to operate the deployable driver door handle according to
DoorDrvrHndlCmd
- Idle
- Deploy
- Retract";
CM_ SG_ 240 DoorLeReHndlCmd "Shall send command to operate the deployable left rear door handle according to
DoorLeReHndlCmd
- Idle
- Deploy
- Retract";
CM_ SG_ 240 DoorPassHndlCmd "Shall send command to operate the deployable passenger door handle according to
DoorPassHndlCmd
- Idle
- Deploy
- Retract";
CM_ SG_ 240 DoorRiReHndlCmd "Shall send command to operate the deployable right rear door handle according to
DoorRiReHndlCmd
- Idle
- Deploy
- Retract";
CM_ SG_ 240 DrvrCtrlOfPassSeatFrntReqd "Distribution of activation request for gentleman function";
CM_ SG_ 240 OnBdChrgrHndlSts1 "Status of the Onboard Charger connection to the grid. ";
CM_ SG_ 240 TrlrLiPosnActvt "Activation of rear position light including rear SML (Side Marker Light).";
CM_ SG_ 240 VehModMngtGlbSafe1CarModSts1 "CarMode Status";
CM_ SG_ 240 VehModMngtGlbSafe1CarModSubtypWd "CarMode substate status";
CM_ SG_ 240 VehModMngtGlbSafe1Chks "Checksum";
CM_ SG_ 240 VehModMngtGlbSafe1Cntr "Counter";
CM_ SG_ 240 VehModMngtGlbSafe1EgyLvlElecMai "Main energy level in the vehicle.";
CM_ SG_ 240 VehModMngtGlbSafe1EgyLvlElecSubt "Substate of the energy level in the vehicle.";
CM_ SG_ 240 VehModMngtGlbSafe1FltEgyCnsWdSts "High quiescent current detected by CEM via BMS.";
CM_ SG_ 240 VehModMngtGlbSafe1PwrLvlElecMai "Main Power level in the vehicle.";
CM_ SG_ 240 VehModMngtGlbSafe1PwrLvlElecSubt "Substate of the power level in the vehicle.";
CM_ SG_ 240 VehModMngtGlbSafe1UsgModSts "UsageMode Status";
CM_ SG_ 533 DCChrgSt "DC charging state";
CM_ SG_ 533 DoorSwipPassOperReqChks "Checksum";
CM_ SG_ 533 DoorSwipPassOperReqCntr "Counter";
CM_ SG_ 533 DoorSwipPassOperReqDoorOpenerReq "Door operation request to Passenger door";
CM_ SG_ 533 DoorSwipPassOperReqTrigSrc "Trigger source";
CM_ SG_ 533 DoorSwipRiReOperReqChks "Checksum";
CM_ SG_ 533 DoorSwipRiReOperReqCntr "Counter";
CM_ SG_ 533 DoorSwipRiReOperReqDoorOpenerReq "Door operation request to Right Rear door";
CM_ SG_ 533 DoorSwipRiReOperReqTrigSrc "Trigger source";
CM_ SG_ 276 ElecChromWinAtReLeCmd "transparency control for rear left window";
CM_ SG_ 276 ElecChromWinAtReRiCmd "transparency control for rear right window";
CM_ SG_ 310 BackrestAdjmtRowSecLe "the backrest adjustment of the second row left seat";
CM_ SG_ 310 BackrestAdjmtRowSecRi "the backrest adjustment of the second row right seat";
CM_ SG_ 310 BackrestAdjmtRowThrdLe "the backrest adjustment of the third row left seat";
CM_ SG_ 310 BackrestAdjmtRowThrdRi "the backrest adjustment of the third row right seat";
CM_ SG_ 310 CushTiltAdjmtRowSecLe "Second row left seat cushion tilt adjustment";
CM_ SG_ 310 CushTiltAdjmtRowSecRi "Second row ri seat cushion tilt adjustment";
CM_ SG_ 310 HdrestAdjmtRowSecLe "HdrestAdjmtRowSecLe";
CM_ SG_ 310 HdrestAdjmtRowSecRi "HdrestAdjmtRowSecRi";
CM_ SG_ 310 HdrestHeiAdjmtRowSecLe "HdrestHeiAdjmtRowSecLe";
CM_ SG_ 310 HdrestHeiAdjmtRowSecRi "HdrestHeiAdjmtRowSecRi";
CM_ SG_ 310 LegRestExtonAdjmtRowSecLe "The second row left seat leg rest extension(forward/backward) adjustment";
CM_ SG_ 310 LegRestExtonAdjmtRowSecRi "The second row right seat leg rest extension(forward/backward) adjustment";
CM_ SG_ 310 LenAdjmtRowSecLe "Second row left seat length adjustment";
CM_ SG_ 310 LenAdjmtRowSecRi "Second row Ri seat length adjustment";
CM_ SG_ 256 EgyCnsAllwdForClima "Energy consumption allowed for climate.";
CM_ SG_ 256 ExtrMirrAdjHmiReq "Adjust the exterior mirror position";
CM_ SG_ 256 ExtrMirrFoldHmiReq "Fold the left and right exterior mirror request";
CM_ SG_ 256 ExtrMirrFoldSetgIdPen "Personal Settings";
CM_ SG_ 256 ExtrMirrFoldSetgMirrDrvr "Driver side mirror tilting";
CM_ SG_ 256 ExtrMirrFoldSetgMirrPass "Passenger side mirror tilting";
CM_ SG_ 256 ExtrMirrSelnHmiReq "Select left or right exterior mirror to adjust";
CM_ SG_ 256 ExtrMirrTiltSetgIdPen "Determine the setting for Mirror Tilting";
CM_ SG_ 256 ExtrMirrTiltSetgMirrDrvr "Determine the setting for Mirror Tilting";
CM_ SG_ 256 ExtrMirrTiltSetgMirrPass "Determine the setting for Mirror Tilting";
CM_ SG_ 256 IncomingAirQlyCtrlFromHmi "PM2.5 Sensor OnOff setting";
CM_ SG_ 256 LockgCenStsLockSt "Signal LockgCenSts provides central locking status to other subsystems.
Signal is a record with three items
- LockSt (Lock State)
- TrigSrc (Trig Source)
- UpdEve (Will be set to TRUE during one second at each new central locking or unlocking event)";
CM_ SG_ 256 LockgCenStsTrigSrc "Signal LockgCenSts provides central locking status to other subsystems.
Signal is a record with three items
- LockSt (Lock State)
- TrigSrc (Trig Source)
- UpdEve (Will be set to TRUE during one second at each new central locking or unlocking event)";
CM_ SG_ 256 LockgCenStsUpdEve "Signal LockgCenSts provides central locking status to other subsystems.
Signal is a record with three items
- LockSt (Lock State)
- TrigSrc (Trig Source)
- UpdEve (Will be set to TRUE during one second at each new central locking or unlocking event)";
CM_ SG_ 256 PrkgAssiSysRemPrkgSts "RPA work status";
CM_ SG_ 256 RelHumSnsrQf "compartment relative humidity quality flag for climate control.";
CM_ SG_ 256 SteerWhlHeatgPwrAct "The calculated power draw of the heated steering wheel (averaged over the last 30 s)";
CM_ SG_ 320 CbnOverHeatProtnEna "HMI request to enable/disable Cabin Overheat protection setting";
CM_ SG_ 320 CmptmtCoolgSts "Status of compartment cooling";
CM_ SG_ 320 FragRefrshAutSetg "Fragrant refresh automatic setting";
CM_ SG_ 320 HmiDefrstMaxReq "Max defroster request by user";
CM_ SG_ 320 HmiHvacFanLvlFrnt "Hmi Hvac Fan Level Front";
CM_ SG_ 320 HmiHvacFanLvlRe "Hmi Hvac Fan Level Rear";
CM_ SG_ 320 HmiHvacRecircCmd "Interpretation: 0 - OsaFull - Full OSA 1 - RecircFull - Full recirculation 2 - RecircFullWithTiOut - Full REC with timeout 3 - AutWithAirQly - AUTO with AQS 4 - Aut - Auto 5 - Resd - Reserved ";
CM_ SG_ 320 HmiHvacReCtrl "Third row climate activated. ";
CM_ SG_ 320 HmiIImSptFragraReq "Intelligentize Spot fragrance function setting";
CM_ SG_ 320 HvClimaCmd "Information for climate if climatisation is allowed";
CM_ SG_ 320 HvCooltHeatrStsSig "Informs of HVCH status.";
CM_ SG_ 320 HvSysRlyStsChks "Checksum for E2E";
CM_ SG_ 320 HvSysRlyStsCntr "Counter for E2E";
CM_ SG_ 320 HvSysRlyStsHvSysRlySts "Actual state of the main contactors.";
CM_ SG_ 320 IncomingAirQlyPopUpReq "PM2.5 PopUp function setting Request";
CM_ SG_ 320 SecClimaAutoSet "Adapted to Second row climate function settiing ,If nobody sencond row climate turn closed";
CM_ SG_ 320 TWinRfClsdPopUpReq "Temperature comfort level closed windows remind setting";
CM_ SG_ 384 DrvrAirCdnrSetgAirCdnrSetg "Determine the setting for air conditioner in Drive Mode Individual";
CM_ SG_ 384 DrvrAirCdnrSetgIdPen "Id Pen";
CM_ SG_ 384 HmiCmptmtCoolgReq "Hmi Compartment Cooling Request";
CM_ SG_ 384 HmiCmptmtTSpForRowFirstLe "First row, left side, climate set point settings from HMI";
CM_ SG_ 384 HmiCmptmtTSpForRowFirstRi "First row, right side, climate setpoint temperature from HMI";
CM_ SG_ 384 HmiCmptmtTSpForRowSecLe "Second row, left side, climate setpoint temperature from HMI";
CM_ SG_ 384 HmiCmptmtTSpForRowSecRi "Second row, right side, climate setpoint temperature from HMI";
CM_ SG_ 384 HmiCmptmtTSpSpclForRowFirstLe "HI/LO setting first row left";
CM_ SG_ 384 HmiCmptmtTSpSpclForRowFirstRi "HI/LO first row right";
CM_ SG_ 384 HmiCmptmtTSpSpclForRowSecLe "HI/LO second row left side";
CM_ SG_ 384 HmiCmptmtTSpSpclForRowSecRi "HI/LO second row, right side ";
CM_ SG_ 384 HmiElecAirDrvrSwtReq "HMI request Driver electric air ventilation Switch";
CM_ SG_ 384 HmiElecAirPassSwtReq "HMI request Passenger electric air ventilation Switch";
CM_ SG_ 384 HpcDeiceReq "Deice request from heat pump.";
CM_ SG_ 384 HpcHpCoolgPwrSts "Whether heat pump satisfies cooling request of climate control.";
CM_ SG_ 384 HpcHpHeatgPwrSts "Whether heat pump satisfies heating request of climate control.";
CM_ SG_ 384 HpcHpModReq "Heat pump mode request.";
CM_ SG_ 384 TrlrLiRvsgActvt "Activation of reverse light.";
BA_DEF_ BO_  "GenMsgSendType" ENUM  "cyclic","spontaneous","not-used","not-used","not-used","cyclicAndSpontaneous","not-used","cyclicIfActive","NoMsgSendType";
BA_DEF_ BO_  "GenMsgCycleTime" INT 0 65536;
BA_DEF_ BO_  "GenMsgStartDelayTime" INT 0 65536;
BA_DEF_ BO_  "GenMsgDelayTime" INT 0 65536;
BA_DEF_ SG_  "GenSigSendType" ENUM  "Cyclic","OnWrite","OnWriteWithRepetition","OnChange","OnChangeWithRepetition","IfActive","IfActiveWithRepetition","NoSigSendType";
BA_DEF_ SG_  "GenSigStartValue" HEX 0 80000000;
BA_DEF_ BO_  "GenMsgILSupport" ENUM  "No","Yes";
BA_DEF_ BO_  "NmAsrMessage" ENUM  "No","Yes";
BA_DEF_ SG_  "GenSigFuncType" ENUM  "NoFunction","n/a","n/a","n/a","n/a","n/a","n/a","n/a","n/a","n/a","n/a","n/a","n/a","n/a","n/a","CHK","CNTR","n/a","n/a","n/a","CNTR_AR_01","CRC_AR_01_BOTH","CRC_AR_01_ALT","CRC_AR_01_LOW","CRC_AR_01_NIBBLE","CNTR_AR_04","CRC_AR_04A","CNTR_AR_05","CRC_AR_05";
BA_DEF_ SG_  "GenSigDataID" STRING ;
BA_DEF_ SG_  "SystemSignalLongSymbol" STRING ;
BA_DEF_DEF_  "GenMsgSendType" "NoMsgSendType";
BA_DEF_DEF_  "GenMsgCycleTime" 0;
BA_DEF_DEF_  "GenMsgStartDelayTime" 0;
BA_DEF_DEF_  "GenMsgDelayTime" 0;
BA_DEF_DEF_  "GenSigSendType" "NoSigSendType";
BA_DEF_DEF_  "GenSigStartValue" 0;
BA_DEF_DEF_  "GenMsgILSupport" "Yes";
BA_DEF_DEF_  "NmAsrMessage" "No";
BA_DEF_DEF_  "GenSigFuncType" "NoFunction";
BA_DEF_DEF_  "GenSigDataID" "";
BA_DEF_DEF_  "SystemSignalLongSymbol" "";
BA_ "GenMsgSendType" BO_ 1120 0;
BA_ "GenMsgCycleTime" BO_ 1120 190;
BA_ "GenMsgSendType" BO_ 1171 0;
BA_ "GenMsgCycleTime" BO_ 1171 100;
BA_ "GenMsgSendType" BO_ 65 0;
BA_ "GenMsgCycleTime" BO_ 65 15;
BA_ "GenMsgSendType" BO_ 1196 1;
BA_ "GenMsgDelayTime" BO_ 1196 495;
BA_ "GenMsgSendType" BO_ 234 0;
BA_ "GenMsgCycleTime" BO_ 234 40;
BA_ "GenMsgSendType" BO_ 91 0;
BA_ "GenMsgCycleTime" BO_ 91 15;
BA_ "GenMsgSendType" BO_ 132 0;
BA_ "GenMsgCycleTime" BO_ 132 30;
BA_ "GenMsgSendType" BO_ 136 0;
BA_ "GenMsgCycleTime" BO_ 136 30;
BA_ "GenMsgSendType" BO_ 139 0;
BA_ "GenMsgCycleTime" BO_ 139 30;
BA_ "GenMsgSendType" BO_ 960 0;
BA_ "GenMsgCycleTime" BO_ 960 400;
BA_ "GenMsgSendType" BO_ 243 0;
BA_ "GenMsgCycleTime" BO_ 243 60;
BA_ "GenMsgSendType" BO_ 818 0;
BA_ "GenMsgCycleTime" BO_ 818 280;
BA_ "GenMsgSendType" BO_ 224 0;
BA_ "GenMsgCycleTime" BO_ 224 40;
BA_ "GenMsgSendType" BO_ 27 0;
BA_ "GenMsgCycleTime" BO_ 27 10;
BA_ "GenMsgSendType" BO_ 629 0;
BA_ "GenMsgCycleTime" BO_ 629 130;
BA_ "GenMsgSendType" BO_ 1375 1;
BA_ "GenMsgDelayTime" BO_ 1375 135;
BA_ "GenMsgSendType" BO_ 576 0;
BA_ "GenMsgCycleTime" BO_ 576 80;
BA_ "GenMsgSendType" BO_ 592 0;
BA_ "GenMsgCycleTime" BO_ 592 90;
BA_ "GenMsgSendType" BO_ 704 0;
BA_ "GenMsgCycleTime" BO_ 704 180;
BA_ "GenMsgSendType" BO_ 529 0;
BA_ "GenMsgCycleTime" BO_ 529 60;
BA_ "GenMsgSendType" BO_ 641 0;
BA_ "GenMsgCycleTime" BO_ 641 130;
BA_ "GenMsgSendType" BO_ 392 0;
BA_ "GenMsgCycleTime" BO_ 392 50;
BA_ "GenMsgSendType" BO_ 613 0;
BA_ "GenMsgCycleTime" BO_ 613 100;
BA_ "GenMsgSendType" BO_ 240 0;
BA_ "GenMsgCycleTime" BO_ 240 65;
BA_ "GenMsgSendType" BO_ 533 0;
BA_ "GenMsgCycleTime" BO_ 533 60;
BA_ "GenMsgSendType" BO_ 276 0;
BA_ "GenMsgCycleTime" BO_ 276 30;
BA_ "GenMsgSendType" BO_ 310 0;
BA_ "GenMsgCycleTime" BO_ 310 70;
BA_ "GenMsgSendType" BO_ 256 0;
BA_ "GenMsgCycleTime" BO_ 256 80;
BA_ "GenMsgSendType" BO_ 320 0;
BA_ "GenMsgCycleTime" BO_ 320 200;
BA_ "GenMsgSendType" BO_ 384 0;
BA_ "GenMsgCycleTime" BO_ 384 200;
BA_ "GenSigSendType" SG_ 1120 CmptmtClngPreStrtReq 0;
BA_ "GenSigSendType" SG_ 1120 SecRowLeDefdMassgProgCfgMassgBag 0;
BA_ "SystemSignalLongSymbol" SG_ 1120 SecRowLeDefdMassgProgCfgMassgBag "SecRowLeDefdMassgProgCfgMassgBag01Select";
BA_ "GenSigSendType" SG_ 1120 SecRowLeDefdMassgProgCfgMas_0000 0;
BA_ "SystemSignalLongSymbol" SG_ 1120 SecRowLeDefdMassgProgCfgMas_0000 "SecRowLeDefdMassgProgCfgMassgBag02Select";
BA_ "GenSigSendType" SG_ 1120 SecRowLeDefdMassgProgCfgMas_0001 0;
BA_ "SystemSignalLongSymbol" SG_ 1120 SecRowLeDefdMassgProgCfgMas_0001 "SecRowLeDefdMassgProgCfgMassgBag03Select";
BA_ "GenSigSendType" SG_ 1120 SecRowLeDefdMassgProgCfgMas_0002 0;
BA_ "SystemSignalLongSymbol" SG_ 1120 SecRowLeDefdMassgProgCfgMas_0002 "SecRowLeDefdMassgProgCfgMassgBag04Select";
BA_ "GenSigSendType" SG_ 1120 SecRowLeDefdMassgProgCfgMas_0003 0;
BA_ "SystemSignalLongSymbol" SG_ 1120 SecRowLeDefdMassgProgCfgMas_0003 "SecRowLeDefdMassgProgCfgMassgBag05Select";
BA_ "GenSigSendType" SG_ 1120 SecRowLeDefdMassgProgCfgMas_0004 0;
BA_ "SystemSignalLongSymbol" SG_ 1120 SecRowLeDefdMassgProgCfgMas_0004 "SecRowLeDefdMassgProgCfgMassgBag06Select";
BA_ "GenSigSendType" SG_ 1120 SecRowLeDefdMassgProgCfgMas_0005 0;
BA_ "SystemSignalLongSymbol" SG_ 1120 SecRowLeDefdMassgProgCfgMas_0005 "SecRowLeDefdMassgProgCfgMassgBag07Select";
BA_ "GenSigSendType" SG_ 1120 SecRowLeDefdMassgProgCfgMas_0006 0;
BA_ "SystemSignalLongSymbol" SG_ 1120 SecRowLeDefdMassgProgCfgMas_0006 "SecRowLeDefdMassgProgCfgMassgBag08Select";
BA_ "GenSigSendType" SG_ 1120 SecRowLeDefdMassgProgCfgMas_0007 0;
BA_ "SystemSignalLongSymbol" SG_ 1120 SecRowLeDefdMassgProgCfgMas_0007 "SecRowLeDefdMassgProgCfgMassgBag09Select";
BA_ "GenSigSendType" SG_ 1120 SecRowLeDefdMassgProgCfgMas_0008 0;
BA_ "SystemSignalLongSymbol" SG_ 1120 SecRowLeDefdMassgProgCfgMas_0008 "SecRowLeDefdMassgProgCfgMassgBag10Select";
BA_ "GenSigSendType" SG_ 1120 SecRowLeDefdMassgProgCfgMas_0009 0;
BA_ "SystemSignalLongSymbol" SG_ 1120 SecRowLeDefdMassgProgCfgMas_0009 "SecRowLeDefdMassgProgCfgMassgBag11Select";
BA_ "GenSigSendType" SG_ 1120 SecRowLeDefdMassgProgCfgMas_0010 0;
BA_ "SystemSignalLongSymbol" SG_ 1120 SecRowLeDefdMassgProgCfgMas_0010 "SecRowLeDefdMassgProgCfgMassgBag12Select";
BA_ "GenSigSendType" SG_ 1120 SecRowLeDefdMassgProgCfgMas_0011 0;
BA_ "SystemSignalLongSymbol" SG_ 1120 SecRowLeDefdMassgProgCfgMas_0011 "SecRowLeDefdMassgProgCfgMassgBag13Select";
BA_ "GenSigSendType" SG_ 1120 SecRowLeDefdMassgProgCfgMas_0012 0;
BA_ "SystemSignalLongSymbol" SG_ 1120 SecRowLeDefdMassgProgCfgMas_0012 "SecRowLeDefdMassgProgCfgMassgBag14Select";
BA_ "GenSigSendType" SG_ 1120 SecRowLeDefdMassgProgCfgMas_0013 0;
BA_ "SystemSignalLongSymbol" SG_ 1120 SecRowLeDefdMassgProgCfgMas_0013 "SecRowLeDefdMassgProgCfgMassgBag15Select";
BA_ "GenSigSendType" SG_ 1120 SecRowLeDefdMassgProgCfgMas_0014 0;
BA_ "SystemSignalLongSymbol" SG_ 1120 SecRowLeDefdMassgProgCfgMas_0014 "SecRowLeDefdMassgProgCfgMassgBag16Select";
BA_ "GenSigSendType" SG_ 1120 SecRowLeDefdMassgProgCfgMassgFrq 0;
BA_ "SystemSignalLongSymbol" SG_ 1120 SecRowLeDefdMassgProgCfgMassgFrq "SecRowLeDefdMassgProgCfgMassgFrqSelect";
BA_ "GenSigSendType" SG_ 1120 SecRowLeDefdMassgProgCfgMassgInt 0;
BA_ "SystemSignalLongSymbol" SG_ 1120 SecRowLeDefdMassgProgCfgMassgInt "SecRowLeDefdMassgProgCfgMassgIntenSelect";
BA_ "GenSigStartValue" SG_ 1120 SecRowLeDefdMassgProgCfgMassProg 1;
BA_ "GenSigSendType" SG_ 1120 SecRowLeDefdMassgProgCfgMassProg 0;
BA_ "SystemSignalLongSymbol" SG_ 1120 SecRowLeDefdMassgProgCfgMassProg "SecRowLeDefdMassgProgCfgMassProgCntr";
BA_ "GenSigSendType" SG_ 1120 SecRowLeDefdMassgProgCfgMas_0015 0;
BA_ "SystemSignalLongSymbol" SG_ 1120 SecRowLeDefdMassgProgCfgMas_0015 "SecRowLeDefdMassgProgCfgMassProgEdit";
BA_ "GenSigStartValue" SG_ 1120 SecRowLeDefdMassgProgCfgMassSeqC 1;
BA_ "GenSigSendType" SG_ 1120 SecRowLeDefdMassgProgCfgMassSeqC 0;
BA_ "SystemSignalLongSymbol" SG_ 1120 SecRowLeDefdMassgProgCfgMassSeqC "SecRowLeDefdMassgProgCfgMassSeqCntr";
BA_ "GenSigStartValue" SG_ 1171 AmbTRawAmbTVal 700;
BA_ "GenSigSendType" SG_ 1171 AmbTRawAmbTVal 0;
BA_ "GenSigSendType" SG_ 1171 AmbTRawQly 0;
BA_ "GenSigStartValue" SG_ 1171 BltLockStAtDrvrBltLockSt1 1;
BA_ "GenSigSendType" SG_ 1171 BltLockStAtDrvrBltLockSt1 0;
BA_ "GenSigSendType" SG_ 1171 BltLockStAtDrvrBltLockSts 0;
BA_ "GenSigStartValue" SG_ 1171 BltLockStAtPassBltLockSt1 1;
BA_ "GenSigSendType" SG_ 1171 BltLockStAtPassBltLockSt1 0;
BA_ "GenSigSendType" SG_ 1171 BltLockStAtPassBltLockSts 0;
BA_ "GenSigStartValue" SG_ 1171 BltLockStAtRowSecLeBltLockEquid 1;
BA_ "GenSigSendType" SG_ 1171 BltLockStAtRowSecLeBltLockEquid 0;
BA_ "GenSigSendType" SG_ 1171 BltLockStAtRowSecLeBltLockSt1 0;
BA_ "GenSigStartValue" SG_ 1171 BltLockStAtRowSecLeBltLockSts 1;
BA_ "GenSigSendType" SG_ 1171 BltLockStAtRowSecLeBltLockSts 0;
BA_ "GenSigStartValue" SG_ 1171 BltLockStAtRowSecMidBltLockEquid 1;
BA_ "GenSigSendType" SG_ 1171 BltLockStAtRowSecMidBltLockEquid 0;
BA_ "GenSigSendType" SG_ 1171 BltLockStAtRowSecMidBltLockSt1 0;
BA_ "GenSigStartValue" SG_ 1171 BltLockStAtRowSecMidBltLockSts 1;
BA_ "GenSigSendType" SG_ 1171 BltLockStAtRowSecMidBltLockSts 0;
BA_ "GenSigStartValue" SG_ 1171 BltLockStAtRowSecRiBltLockEquid 1;
BA_ "GenSigSendType" SG_ 1171 BltLockStAtRowSecRiBltLockEquid 0;
BA_ "GenSigSendType" SG_ 1171 BltLockStAtRowSecRiBltLockSt1 0;
BA_ "GenSigStartValue" SG_ 1171 BltLockStAtRowSecRiBltLockSts 1;
BA_ "GenSigSendType" SG_ 1171 BltLockStAtRowSecRiBltLockSts 0;
BA_ "GenSigStartValue" SG_ 1171 BltLockStAtRowThrdLeBltLockEquid 1;
BA_ "GenSigSendType" SG_ 1171 BltLockStAtRowThrdLeBltLockEquid 0;
BA_ "GenSigSendType" SG_ 1171 BltLockStAtRowThrdLeBltLockSt1 0;
BA_ "GenSigStartValue" SG_ 1171 BltLockStAtRowThrdLeBltLockSts 1;
BA_ "GenSigSendType" SG_ 1171 BltLockStAtRowThrdLeBltLockSts 0;
BA_ "GenSigStartValue" SG_ 1171 BltLockStAtRowThrdRiBltLockEquid 1;
BA_ "GenSigSendType" SG_ 1171 BltLockStAtRowThrdRiBltLockEquid 0;
BA_ "GenSigSendType" SG_ 1171 BltLockStAtRowThrdRiBltLockSt1 0;
BA_ "GenSigStartValue" SG_ 1171 BltLockStAtRowThrdRiBltLockSts 1;
BA_ "GenSigSendType" SG_ 1171 BltLockStAtRowThrdRiBltLockSts 0;
BA_ "GenSigStartValue" SG_ 1171 CooltHeatrTIntk 40;
BA_ "GenSigSendType" SG_ 1171 CooltHeatrTIntk 0;
BA_ "GenSigStartValue" SG_ 1171 CooltHeatrTOutl 40;
BA_ "GenSigSendType" SG_ 1171 CooltHeatrTOutl 0;
BA_ "GenSigSendType" SG_ 1171 DrvrPfmncAlrmReq 0;
BA_ "GenSigSendType" SG_ 1171 RemChkTInVeh 1;
BA_ "GenSigSendType" SG_ 65 ChdLockReLeCtrlHmiReq 0;
BA_ "GenSigSendType" SG_ 65 ChdLockReRiCtrlHmiReq 0;
BA_ "GenSigStartValue" SG_ 65 HmiSeatClimaTmrHmiSeatHeatgFirst 15;
BA_ "GenSigSendType" SG_ 65 HmiSeatClimaTmrHmiSeatHeatgFirst 0;
BA_ "SystemSignalLongSymbol" SG_ 65 HmiSeatClimaTmrHmiSeatHeatgFirst "HmiSeatClimaTmrHmiSeatHeatgFirstLeTmr";
BA_ "GenSigStartValue" SG_ 65 HmiSeatClimaTmrHmiSeatHeatg_0000 15;
BA_ "GenSigSendType" SG_ 65 HmiSeatClimaTmrHmiSeatHeatg_0000 0;
BA_ "SystemSignalLongSymbol" SG_ 65 HmiSeatClimaTmrHmiSeatHeatg_0000 "HmiSeatClimaTmrHmiSeatHeatgFirstRiTmr";
BA_ "GenSigStartValue" SG_ 65 HmiSeatClimaTmrHmiSeatHeatgSecLe 15;
BA_ "GenSigSendType" SG_ 65 HmiSeatClimaTmrHmiSeatHeatgSecLe 0;
BA_ "SystemSignalLongSymbol" SG_ 65 HmiSeatClimaTmrHmiSeatHeatgSecLe "HmiSeatClimaTmrHmiSeatHeatgSecLeTmr";
BA_ "GenSigStartValue" SG_ 65 HmiSeatClimaTmrHmiSeatHeatgSecRi 15;
BA_ "GenSigSendType" SG_ 65 HmiSeatClimaTmrHmiSeatHeatgSecRi 0;
BA_ "SystemSignalLongSymbol" SG_ 65 HmiSeatClimaTmrHmiSeatHeatgSecRi "HmiSeatClimaTmrHmiSeatHeatgSecRiTmr";
BA_ "GenSigStartValue" SG_ 65 HmiSeatClimaTmrHmiSeatVentnFirst 15;
BA_ "GenSigSendType" SG_ 65 HmiSeatClimaTmrHmiSeatVentnFirst 0;
BA_ "SystemSignalLongSymbol" SG_ 65 HmiSeatClimaTmrHmiSeatVentnFirst "HmiSeatClimaTmrHmiSeatVentnFirstLeTmr";
BA_ "GenSigStartValue" SG_ 65 HmiSeatClimaTmrHmiSeatVentn_0000 15;
BA_ "GenSigSendType" SG_ 65 HmiSeatClimaTmrHmiSeatVentn_0000 0;
BA_ "SystemSignalLongSymbol" SG_ 65 HmiSeatClimaTmrHmiSeatVentn_0000 "HmiSeatClimaTmrHmiSeatVentnFirstRiTmr";
BA_ "GenSigStartValue" SG_ 65 HmiSeatClimaTmrHmiSeatVentnSecLe 15;
BA_ "GenSigSendType" SG_ 65 HmiSeatClimaTmrHmiSeatVentnSecLe 0;
BA_ "SystemSignalLongSymbol" SG_ 65 HmiSeatClimaTmrHmiSeatVentnSecLe "HmiSeatClimaTmrHmiSeatVentnSecLeTmr";
BA_ "GenSigStartValue" SG_ 65 HmiSeatClimaTmrHmiSeatVentnSecRi 15;
BA_ "GenSigSendType" SG_ 65 HmiSeatClimaTmrHmiSeatVentnSecRi 0;
BA_ "SystemSignalLongSymbol" SG_ 65 HmiSeatClimaTmrHmiSeatVentnSecRi "HmiSeatClimaTmrHmiSeatVentnSecRiTmr";
BA_ "GenSigSendType" SG_ 65 HmiSeatClimaTmrIdPen 0;
BA_ "GenSigSendType" SG_ 1196 DrvrSeatHallPosDownLdSeatFrntHei 1;
BA_ "SystemSignalLongSymbol" SG_ 1196 DrvrSeatHallPosDownLdSeatFrntHei "DrvrSeatHallPosDownLdSeatFrntHeiPos";
BA_ "GenSigSendType" SG_ 1196 DrvrSeatHallPosDownLdSeatHeiPos 1;
BA_ "GenSigSendType" SG_ 1196 DrvrSeatHallPosDownLdSeatInclPos 1;
BA_ "GenSigSendType" SG_ 1196 DrvrSeatHallPosDownLdSeatSldPos 1;
BA_ "GenSigStartValue" SG_ 234 DoorSldngLeReReqChks 255;
BA_ "GenSigSendType" SG_ 234 DoorSldngLeReReqChks 0;
BA_ "GenSigSendType" SG_ 234 DoorSldngLeReReqCntr 0;
BA_ "GenSigSendType" SG_ 234 DoorSldngLeReReqDoorOpenerReq 0;
BA_ "GenSigSendType" SG_ 234 DoorSldngLeReReqTrigSrc 0;
BA_ "GenSigStartValue" SG_ 234 DoorSldngRiReReqChks 255;
BA_ "GenSigSendType" SG_ 234 DoorSldngRiReReqChks 0;
BA_ "GenSigSendType" SG_ 234 DoorSldngRiReReqCntr 0;
BA_ "GenSigSendType" SG_ 234 DoorSldngRiReReqDoorOpenerReq 0;
BA_ "GenSigSendType" SG_ 234 DoorSldngRiReReqTrigSrc 0;
BA_ "GenSigSendType" SG_ 234 FirstRowLeDefdMassgProgSeln 0;
BA_ "GenSigSendType" SG_ 234 FirstRowRiDefdMassgProgSeln 0;
BA_ "GenSigSendType" SG_ 234 FRDSDoorOpenInd 0;
BA_ "GenSigSendType" SG_ 234 FRDSLockgSts 0;
BA_ "GenSigSendType" SG_ 234 TrsmParkLockdChks 0;
BA_ "GenSigFuncType" SG_ 234 TrsmParkLockdChks 15;
BA_ "GenSigDataID" SG_ 234 TrsmParkLockdChks "0x32";
BA_ "GenSigSendType" SG_ 234 TrsmParkLockdCntr 0;
BA_ "GenSigFuncType" SG_ 234 TrsmParkLockdCntr 16;
BA_ "GenSigStartValue" SG_ 234 TrsmParkLockdTrsmParkLockd 3;
BA_ "GenSigSendType" SG_ 234 TrsmParkLockdTrsmParkLockd 0;
BA_ "GenSigSendType" SG_ 91 HvBattLimnIndcn 0;
BA_ "GenSigSendType" SG_ 91 SeatFoldRaiseReqRowSecLe 0;
BA_ "GenSigSendType" SG_ 91 SeatFoldRaiseReqRowSecMid 0;
BA_ "GenSigSendType" SG_ 91 SeatFoldRaiseReqRowSecRi 0;
BA_ "GenSigSendType" SG_ 91 SeatFoldRaiseReqRowThrdLe 0;
BA_ "GenSigSendType" SG_ 91 SeatFoldRaiseReqRowThrdRi 0;
BA_ "GenSigSendType" SG_ 91 ShortDropWinDrvrDoor 0;
BA_ "GenSigSendType" SG_ 91 ShortDropWinLeReDoor 0;
BA_ "GenSigSendType" SG_ 91 ShortDropWinPassDoor 0;
BA_ "GenSigSendType" SG_ 91 ShortDropWinRiReDoor 0;
BA_ "GenSigSendType" SG_ 132 MusicInfoForMusicShow2DownSampli 0;
BA_ "SystemSignalLongSymbol" SG_ 132 MusicInfoForMusicShow2DownSampli "MusicInfoForMusicShow2DownSamplingAmplitude";
BA_ "GenSigSendType" SG_ 132 MusicInfoForMusicShow2MaxFFT100m 0;
BA_ "SystemSignalLongSymbol" SG_ 132 MusicInfoForMusicShow2MaxFFT100m "MusicInfoForMusicShow2MaxFFT100ms3kAmplitude";
BA_ "GenSigSendType" SG_ 132 MusicInfoForMusicShow2MaxFF_0000 0;
BA_ "SystemSignalLongSymbol" SG_ 132 MusicInfoForMusicShow2MaxFF_0000 "MusicInfoForMusicShow2MaxFFT100ms3kFrequency";
BA_ "GenSigSendType" SG_ 132 MusicInfoForMusicShow2Segment1FF 0;
BA_ "SystemSignalLongSymbol" SG_ 132 MusicInfoForMusicShow2Segment1FF "MusicInfoForMusicShow2Segment1FFTamplitude";
BA_ "GenSigSendType" SG_ 132 MusicInfoForMusicShow2Segment2FF 0;
BA_ "SystemSignalLongSymbol" SG_ 132 MusicInfoForMusicShow2Segment2FF "MusicInfoForMusicShow2Segment2FFTamplitude";
BA_ "GenSigSendType" SG_ 132 MusicInfoForMusicShow2Segment3FF 0;
BA_ "SystemSignalLongSymbol" SG_ 132 MusicInfoForMusicShow2Segment3FF "MusicInfoForMusicShow2Segment3FFTamplitude";
BA_ "GenSigSendType" SG_ 132 MusicInfoForMusicShow2Segment4FF 0;
BA_ "SystemSignalLongSymbol" SG_ 132 MusicInfoForMusicShow2Segment4FF "MusicInfoForMusicShow2Segment4FFTamplitude";
BA_ "GenSigSendType" SG_ 132 MusicInfoForMusicShow2Segment5FF 0;
BA_ "SystemSignalLongSymbol" SG_ 132 MusicInfoForMusicShow2Segment5FF "MusicInfoForMusicShow2Segment5FFTamplitude";
BA_ "GenSigSendType" SG_ 132 MusicInfoForMusicShow2Segment6FF 0;
BA_ "SystemSignalLongSymbol" SG_ 132 MusicInfoForMusicShow2Segment6FF "MusicInfoForMusicShow2Segment6FFTamplitude";
BA_ "GenSigSendType" SG_ 132 MusicInfoForMusicShow2Segment7FF 0;
BA_ "SystemSignalLongSymbol" SG_ 132 MusicInfoForMusicShow2Segment7FF "MusicInfoForMusicShow2Segment7FFTamplitude";
BA_ "GenSigSendType" SG_ 132 MusicInfoForMusicShow2Segment8FF 0;
BA_ "SystemSignalLongSymbol" SG_ 132 MusicInfoForMusicShow2Segment8FF "MusicInfoForMusicShow2Segment8FFTamplitude";
BA_ "GenSigSendType" SG_ 132 MusicInfoForMusicShow2StateFlagA 0;
BA_ "SystemSignalLongSymbol" SG_ 132 MusicInfoForMusicShow2StateFlagA "MusicInfoForMusicShow2StateFlagAudioPlay";
BA_ "GenSigSendType" SG_ 132 MusicInfoForMusicShow2StateFlagN 0;
BA_ "SystemSignalLongSymbol" SG_ 132 MusicInfoForMusicShow2StateFlagN "MusicInfoForMusicShow2StateFlagNewAudio";
BA_ "GenSigSendType" SG_ 132 MusicInfoForMusicShow2TimeFlagAu 0;
BA_ "SystemSignalLongSymbol" SG_ 132 MusicInfoForMusicShow2TimeFlagAu "MusicInfoForMusicShow2TimeFlagAudioPlay";
BA_ "GenSigSendType" SG_ 132 MusicInfoForMusicShow2TimeFlagMe 0;
BA_ "SystemSignalLongSymbol" SG_ 132 MusicInfoForMusicShow2TimeFlagMe "MusicInfoForMusicShow2TimeFlagMessage";
BA_ "GenSigSendType" SG_ 136 MusicInfoForMusicShow3DownSampli 0;
BA_ "SystemSignalLongSymbol" SG_ 136 MusicInfoForMusicShow3DownSampli "MusicInfoForMusicShow3DownSamplingAmplitude";
BA_ "GenSigSendType" SG_ 136 MusicInfoForMusicShow3MaxFFT100m 0;
BA_ "SystemSignalLongSymbol" SG_ 136 MusicInfoForMusicShow3MaxFFT100m "MusicInfoForMusicShow3MaxFFT100ms3kAmplitude";
BA_ "GenSigSendType" SG_ 136 MusicInfoForMusicShow3MaxFF_0000 0;
BA_ "SystemSignalLongSymbol" SG_ 136 MusicInfoForMusicShow3MaxFF_0000 "MusicInfoForMusicShow3MaxFFT100ms3kFrequency";
BA_ "GenSigSendType" SG_ 136 MusicInfoForMusicShow3Segment1FF 0;
BA_ "SystemSignalLongSymbol" SG_ 136 MusicInfoForMusicShow3Segment1FF "MusicInfoForMusicShow3Segment1FFTamplitude";
BA_ "GenSigSendType" SG_ 136 MusicInfoForMusicShow3Segment2FF 0;
BA_ "SystemSignalLongSymbol" SG_ 136 MusicInfoForMusicShow3Segment2FF "MusicInfoForMusicShow3Segment2FFTamplitude";
BA_ "GenSigSendType" SG_ 136 MusicInfoForMusicShow3Segment3FF 0;
BA_ "SystemSignalLongSymbol" SG_ 136 MusicInfoForMusicShow3Segment3FF "MusicInfoForMusicShow3Segment3FFTamplitude";
BA_ "GenSigSendType" SG_ 136 MusicInfoForMusicShow3Segment4FF 0;
BA_ "SystemSignalLongSymbol" SG_ 136 MusicInfoForMusicShow3Segment4FF "MusicInfoForMusicShow3Segment4FFTamplitude";
BA_ "GenSigSendType" SG_ 136 MusicInfoForMusicShow3Segment5FF 0;
BA_ "SystemSignalLongSymbol" SG_ 136 MusicInfoForMusicShow3Segment5FF "MusicInfoForMusicShow3Segment5FFTamplitude";
BA_ "GenSigSendType" SG_ 136 MusicInfoForMusicShow3Segment6FF 0;
BA_ "SystemSignalLongSymbol" SG_ 136 MusicInfoForMusicShow3Segment6FF "MusicInfoForMusicShow3Segment6FFTamplitude";
BA_ "GenSigSendType" SG_ 136 MusicInfoForMusicShow3Segment7FF 0;
BA_ "SystemSignalLongSymbol" SG_ 136 MusicInfoForMusicShow3Segment7FF "MusicInfoForMusicShow3Segment7FFTamplitude";
BA_ "GenSigSendType" SG_ 136 MusicInfoForMusicShow3Segment8FF 0;
BA_ "SystemSignalLongSymbol" SG_ 136 MusicInfoForMusicShow3Segment8FF "MusicInfoForMusicShow3Segment8FFTamplitude";
BA_ "GenSigSendType" SG_ 136 MusicInfoForMusicShow3StateFlagA 0;
BA_ "SystemSignalLongSymbol" SG_ 136 MusicInfoForMusicShow3StateFlagA "MusicInfoForMusicShow3StateFlagAudioPlay";
BA_ "GenSigSendType" SG_ 136 MusicInfoForMusicShow3StateFlagN 0;
BA_ "SystemSignalLongSymbol" SG_ 136 MusicInfoForMusicShow3StateFlagN "MusicInfoForMusicShow3StateFlagNewAudio";
BA_ "GenSigSendType" SG_ 136 MusicInfoForMusicShow3TimeFlagAu 0;
BA_ "SystemSignalLongSymbol" SG_ 136 MusicInfoForMusicShow3TimeFlagAu "MusicInfoForMusicShow3TimeFlagAudioPlay";
BA_ "GenSigSendType" SG_ 136 MusicInfoForMusicShow3TimeFlagMe 0;
BA_ "SystemSignalLongSymbol" SG_ 136 MusicInfoForMusicShow3TimeFlagMe "MusicInfoForMusicShow3TimeFlagMessage";
BA_ "GenSigSendType" SG_ 139 MusicInfoForMusicShow4DownSampli 0;
BA_ "SystemSignalLongSymbol" SG_ 139 MusicInfoForMusicShow4DownSampli "MusicInfoForMusicShow4DownSamplingAmplitude";
BA_ "GenSigSendType" SG_ 139 MusicInfoForMusicShow4MaxFFT100m 0;
BA_ "SystemSignalLongSymbol" SG_ 139 MusicInfoForMusicShow4MaxFFT100m "MusicInfoForMusicShow4MaxFFT100ms3kAmplitude";
BA_ "GenSigSendType" SG_ 139 MusicInfoForMusicShow4MaxFF_0000 0;
BA_ "SystemSignalLongSymbol" SG_ 139 MusicInfoForMusicShow4MaxFF_0000 "MusicInfoForMusicShow4MaxFFT100ms3kFrequency";
BA_ "GenSigSendType" SG_ 139 MusicInfoForMusicShow4Segment1FF 0;
BA_ "SystemSignalLongSymbol" SG_ 139 MusicInfoForMusicShow4Segment1FF "MusicInfoForMusicShow4Segment1FFTamplitude";
BA_ "GenSigSendType" SG_ 139 MusicInfoForMusicShow4Segment2FF 0;
BA_ "SystemSignalLongSymbol" SG_ 139 MusicInfoForMusicShow4Segment2FF "MusicInfoForMusicShow4Segment2FFTamplitude";
BA_ "GenSigSendType" SG_ 139 MusicInfoForMusicShow4Segment3FF 0;
BA_ "SystemSignalLongSymbol" SG_ 139 MusicInfoForMusicShow4Segment3FF "MusicInfoForMusicShow4Segment3FFTamplitude";
BA_ "GenSigSendType" SG_ 139 MusicInfoForMusicShow4Segment4FF 0;
BA_ "SystemSignalLongSymbol" SG_ 139 MusicInfoForMusicShow4Segment4FF "MusicInfoForMusicShow4Segment4FFTamplitude";
BA_ "GenSigSendType" SG_ 139 MusicInfoForMusicShow4Segment5FF 0;
BA_ "SystemSignalLongSymbol" SG_ 139 MusicInfoForMusicShow4Segment5FF "MusicInfoForMusicShow4Segment5FFTamplitude";
BA_ "GenSigSendType" SG_ 139 MusicInfoForMusicShow4Segment6FF 0;
BA_ "SystemSignalLongSymbol" SG_ 139 MusicInfoForMusicShow4Segment6FF "MusicInfoForMusicShow4Segment6FFTamplitude";
BA_ "GenSigSendType" SG_ 139 MusicInfoForMusicShow4Segment7FF 0;
BA_ "SystemSignalLongSymbol" SG_ 139 MusicInfoForMusicShow4Segment7FF "MusicInfoForMusicShow4Segment7FFTamplitude";
BA_ "GenSigSendType" SG_ 139 MusicInfoForMusicShow4Segment8FF 0;
BA_ "SystemSignalLongSymbol" SG_ 139 MusicInfoForMusicShow4Segment8FF "MusicInfoForMusicShow4Segment8FFTamplitude";
BA_ "GenSigSendType" SG_ 139 MusicInfoForMusicShow4StateFlagA 0;
BA_ "SystemSignalLongSymbol" SG_ 139 MusicInfoForMusicShow4StateFlagA "MusicInfoForMusicShow4StateFlagAudioPlay";
BA_ "GenSigSendType" SG_ 139 MusicInfoForMusicShow4StateFlagN 0;
BA_ "SystemSignalLongSymbol" SG_ 139 MusicInfoForMusicShow4StateFlagN "MusicInfoForMusicShow4StateFlagNewAudio";
BA_ "GenSigSendType" SG_ 139 MusicInfoForMusicShow4TimeFlagAu 0;
BA_ "SystemSignalLongSymbol" SG_ 139 MusicInfoForMusicShow4TimeFlagAu "MusicInfoForMusicShow4TimeFlagAudioPlay";
BA_ "GenSigSendType" SG_ 139 MusicInfoForMusicShow4TimeFlagMe 0;
BA_ "SystemSignalLongSymbol" SG_ 139 MusicInfoForMusicShow4TimeFlagMe "MusicInfoForMusicShow4TimeFlagMessage";
BA_ "GenSigStartValue" SG_ 960 HmiPassTempSyncSet 1;
BA_ "GenSigSendType" SG_ 960 HmiPassTempSyncSet 0;
BA_ "GenSigSendType" SG_ 960 LegRestRotAdjmtRowSecLe 0;
BA_ "GenSigSendType" SG_ 960 LegRestRotAdjmtRowSecRi 0;
BA_ "GenSigSendType" SG_ 960 VehTiAndDataDataValid 0;
BA_ "GenSigStartValue" SG_ 960 VehTiAndDataDay 1;
BA_ "GenSigSendType" SG_ 960 VehTiAndDataDay 0;
BA_ "GenSigSendType" SG_ 960 VehTiAndDataHr1 0;
BA_ "GenSigSendType" SG_ 960 VehTiAndDataMins1 0;
BA_ "GenSigStartValue" SG_ 960 VehTiAndDataMth1 1;
BA_ "GenSigSendType" SG_ 960 VehTiAndDataMth1 0;
BA_ "GenSigSendType" SG_ 960 VehTiAndDataSec1 0;
BA_ "GenSigSendType" SG_ 960 VehTiAndDataYr1 0;
BA_ "GenSigSendType" SG_ 243 ActvnOfPudLi 0;
BA_ "GenSigSendType" SG_ 243 CushExtnSecRowLe 0;
BA_ "GenSigSendType" SG_ 243 CushExtnSecRowRi 0;
BA_ "GenSigSendType" SG_ 243 HmiElecAirFrntSwtReqHmiElecAirDr 0;
BA_ "SystemSignalLongSymbol" SG_ 243 HmiElecAirFrntSwtReqHmiElecAirDr "HmiElecAirFrntSwtReqHmiElecAirDrvrLeSwtReq";
BA_ "GenSigSendType" SG_ 243 HmiElecAirFrntSwtReqHmiElec_0000 0;
BA_ "SystemSignalLongSymbol" SG_ 243 HmiElecAirFrntSwtReqHmiElec_0000 "HmiElecAirFrntSwtReqHmiElecAirDrvrRiSwtReq";
BA_ "GenSigSendType" SG_ 243 HmiElecAirFrntSwtReqHmiElecAirPa 0;
BA_ "SystemSignalLongSymbol" SG_ 243 HmiElecAirFrntSwtReqHmiElecAirPa "HmiElecAirFrntSwtReqHmiElecAirPassLeSwtReq";
BA_ "GenSigSendType" SG_ 243 HmiElecAirFrntSwtReqHmiElec_0001 0;
BA_ "SystemSignalLongSymbol" SG_ 243 HmiElecAirFrntSwtReqHmiElec_0001 "HmiElecAirFrntSwtReqHmiElecAirPassRiSwtReq";
BA_ "GenSigSendType" SG_ 243 HmiElecAirReSwtReqHmiElecAirReLe 0;
BA_ "SystemSignalLongSymbol" SG_ 243 HmiElecAirReSwtReqHmiElecAirReLe "HmiElecAirReSwtReqHmiElecAirReLeSwtReq";
BA_ "GenSigSendType" SG_ 243 HmiElecAirReSwtReqHmiElecAirReRi 0;
BA_ "SystemSignalLongSymbol" SG_ 243 HmiElecAirReSwtReqHmiElecAirReRi "HmiElecAirReSwtReqHmiElecAirReRiSwtReq";
BA_ "GenSigSendType" SG_ 243 RearWinDimEna 0;
BA_ "GenSigStartValue" SG_ 243 RollAgGlbQf 1;
BA_ "GenSigSendType" SG_ 243 RollAgGlbQf 0;
BA_ "GenSigSendType" SG_ 243 RollAgGlbVal 0;
BA_ "GenSigSendType" SG_ 243 SecRowLeLoadAndStoreReqErgoPosn 0;
BA_ "GenSigSendType" SG_ 243 SecRowLeLoadAndStoreReqErgoSetgE 0;
BA_ "SystemSignalLongSymbol" SG_ 243 SecRowLeLoadAndStoreReqErgoSetgE "SecRowLeLoadAndStoreReqErgoSetgEve";
BA_ "GenSigSendType" SG_ 243 SecRowRiLoadAndStoreReqErgoPosn 0;
BA_ "GenSigSendType" SG_ 243 SecRowRiLoadAndStoreReqErgoSetgE 0;
BA_ "SystemSignalLongSymbol" SG_ 243 SecRowRiLoadAndStoreReqErgoSetgE "SecRowRiLoadAndStoreReqErgoSetgEve";
BA_ "GenSigSendType" SG_ 243 SecRowRiSeatDispMassgFctMassgInt 0;
BA_ "SystemSignalLongSymbol" SG_ 243 SecRowRiSeatDispMassgFctMassgInt "SecRowRiSeatDispMassgFctMassgInten";
BA_ "GenSigSendType" SG_ 243 SecRowRiSeatDispMassgFctMassgPro 0;
BA_ "SystemSignalLongSymbol" SG_ 243 SecRowRiSeatDispMassgFctMassgPro "SecRowRiSeatDispMassgFctMassgProg";
BA_ "GenSigSendType" SG_ 243 SecRowRiSeatDispMassgFctOnOff 0;
BA_ "GenSigSendType" SG_ 243 ShoulderAdjmtRowSecLe 0;
BA_ "GenSigSendType" SG_ 243 ShoulderAdjmtRowSecRi 0;
BA_ "GenSigSendType" SG_ 818 HmiCmptmtSecRowLeAirDistbn 0;
BA_ "GenSigSendType" SG_ 818 HmiCmptmtSecRowRiAirDistbn 0;
BA_ "GenSigSendType" SG_ 818 HmiDrvrClimaAutReq 0;
BA_ "GenSigSendType" SG_ 818 HmiDrvrHvacFanLvl 0;
BA_ "GenSigSendType" SG_ 818 HmiPassClimaAutReq 0;
BA_ "GenSigSendType" SG_ 818 HmiPassHvacFanLvl 0;
BA_ "GenSigSendType" SG_ 818 HmiSecRowLeClimaAutReq 0;
BA_ "GenSigSendType" SG_ 818 HmiSecRowLeHvacFanLvl 0;
BA_ "GenSigSendType" SG_ 818 HmiSecRowRiClimaAutReq 0;
BA_ "GenSigSendType" SG_ 818 HmiSecRowRiHvacFanLvl 0;
BA_ "GenSigSendType" SG_ 224 DoorPassSts 0;
BA_ "GenSigSendType" SG_ 224 DoorRiReSts 0;
BA_ "GenSigSendType" SG_ 224 HvPwrAvlForClimaEstimd 0;
BA_ "GenSigSendType" SG_ 224 IntrBriSts 0;
BA_ "GenSigSendType" SG_ 224 MirrTintgCmd 0;
BA_ "GenSigSendType" SG_ 224 SecRowLeSeatDispSpplFct 0;
BA_ "GenSigSendType" SG_ 224 SecRowRiSeatDispSpplFct 0;
BA_ "GenSigSendType" SG_ 224 SecRowSeatDispBtnPsdSecRowLeSeat 0;
BA_ "SystemSignalLongSymbol" SG_ 224 SecRowSeatDispBtnPsdSecRowLeSeat "SecRowSeatDispBtnPsdSecRowLeSeatDispBtnPsd";
BA_ "GenSigSendType" SG_ 224 SecRowSeatDispBtnPsdSecRowRiSeat 0;
BA_ "SystemSignalLongSymbol" SG_ 224 SecRowSeatDispBtnPsdSecRowRiSeat "SecRowSeatDispBtnPsdSecRowRiSeatDispBtnPsd";
BA_ "GenSigSendType" SG_ 224 SteerWhlHeatgDesPwr 0;
BA_ "GenSigSendType" SG_ 224 TopPosTrFromHmi 1;
BA_ "GenSigSendType" SG_ 224 TrlrLampChkReqFromHmi 0;
BA_ "GenSigSendType" SG_ 224 TrlrLiFogActvt 0;
BA_ "GenSigSendType" SG_ 224 TrPosnUpprProgmReq 0;
BA_ "GenSigSendType" SG_ 224 TrSts 0;
BA_ "GenSigSendType" SG_ 27 ReadLiStsFirstRowLe 0;
BA_ "GenSigSendType" SG_ 27 ReadLiStsFirstRowRi 0;
BA_ "GenSigSendType" SG_ 27 ReadLiStsSecondRowLe 0;
BA_ "GenSigSendType" SG_ 27 ReadLiStsSecondRowRi 0;
BA_ "GenSigSendType" SG_ 27 ReadLiStsThirdRowLe 0;
BA_ "GenSigSendType" SG_ 27 ReadLiStsThirdRowRi 0;
BA_ "GenSigStartValue" SG_ 629 HVACColdAirTAct 80;
BA_ "GenSigStartValue" SG_ 629 HVACWarmAirTAct 80;
BA_ "GenSigSendType" SG_ 1375 VinBlockNr 1;
BA_ "GenSigSendType" SG_ 1375 VinVINSignalPos1 1;
BA_ "GenSigSendType" SG_ 1375 VinVINSignalPos2 1;
BA_ "GenSigSendType" SG_ 1375 VinVINSignalPos3 1;
BA_ "GenSigSendType" SG_ 1375 VinVINSignalPos4 1;
BA_ "GenSigSendType" SG_ 1375 VinVINSignalPos5 1;
BA_ "GenSigSendType" SG_ 1375 VinVINSignalPos6 1;
BA_ "GenSigSendType" SG_ 1375 VinVINSignalPos7 1;
BA_ "GenSigSendType" SG_ 576 AmbLiThemeModSelnReqAmbLiTheme 0;
BA_ "GenSigSendType" SG_ 576 AmbLiThemeModSelnReqIdPen 0;
BA_ "GenSigSendType" SG_ 576 OneKeyAdjAllSeatDftPosn 0;
BA_ "GenSigSendType" SG_ 576 OneKeyAdjPassSeatFwdPosn 0;
BA_ "GenSigSendType" SG_ 576 Zone4SettingsBlue 0;
BA_ "GenSigSendType" SG_ 576 Zone4SettingsGreen 0;
BA_ "GenSigSendType" SG_ 576 Zone4SettingsIdPen 0;
BA_ "GenSigSendType" SG_ 576 Zone4SettingsIntensity 0;
BA_ "GenSigSendType" SG_ 576 Zone4SettingsRed 0;
BA_ "GenSigSendType" SG_ 576 Zone4SettingsZoneStatus 0;
BA_ "GenSigSendType" SG_ 592 AmbLiSpeechCorrlnReqIdPen 0;
BA_ "GenSigSendType" SG_ 592 AmbLiSpeechCorrlnReqOnOff1 0;
BA_ "GenSigStartValue" SG_ 592 DrvrSeatSts 1;
BA_ "GenSigSendType" SG_ 592 DrvrSeatSts 0;
BA_ "GenSigStartValue" SG_ 592 RoadInclnForPOD 8;
BA_ "GenSigSendType" SG_ 592 RoadInclnForPOD 0;
BA_ "GenSigStartValue" SG_ 592 RollAgGlbForPOD 8;
BA_ "GenSigSendType" SG_ 592 RollAgGlbForPOD 0;
BA_ "GenSigSendType" SG_ 592 Zone5SettingsBlue 0;
BA_ "GenSigSendType" SG_ 592 Zone5SettingsGreen 0;
BA_ "GenSigSendType" SG_ 592 Zone5SettingsIdPen 0;
BA_ "GenSigSendType" SG_ 592 Zone5SettingsIntensity 0;
BA_ "GenSigSendType" SG_ 592 Zone5SettingsRed 0;
BA_ "GenSigSendType" SG_ 592 Zone5SettingsZoneStatus 0;
BA_ "GenSigSendType" SG_ 704 HmiReElecAirDirCrtlReqSecRowLePo 0;
BA_ "SystemSignalLongSymbol" SG_ 704 HmiReElecAirDirCrtlReqSecRowLePo "HmiReElecAirDirCrtlReqSecRowLePosX";
BA_ "GenSigSendType" SG_ 704 HmiReElecAirDirCrtlReqSecRo_0000 0;
BA_ "SystemSignalLongSymbol" SG_ 704 HmiReElecAirDirCrtlReqSecRo_0000 "HmiReElecAirDirCrtlReqSecRowLePosY";
BA_ "GenSigSendType" SG_ 704 HmiReElecAirDirCrtlReqSecRowRiPo 0;
BA_ "SystemSignalLongSymbol" SG_ 704 HmiReElecAirDirCrtlReqSecRowRiPo "HmiReElecAirDirCrtlReqSecRowRiPosX";
BA_ "GenSigSendType" SG_ 704 HmiReElecAirDirCrtlReqSecRo_0001 0;
BA_ "SystemSignalLongSymbol" SG_ 704 HmiReElecAirDirCrtlReqSecRo_0001 "HmiReElecAirDirCrtlReqSecRowRiPosY";
BA_ "GenSigStartValue" SG_ 529 AirClngReq 1;
BA_ "GenSigSendType" SG_ 529 AirClngReq 0;
BA_ "GenSigSendType" SG_ 529 AmbLiBriAutAdjmtCenDispBriSnsrRa 0;
BA_ "SystemSignalLongSymbol" SG_ 529 AmbLiBriAutAdjmtCenDispBriSnsrRa "AmbLiBriAutAdjmtCenDispBriSnsrRaw";
BA_ "GenSigSendType" SG_ 529 AmbLiBriAutAdjmtIdPen 0;
BA_ "GenSigSendType" SG_ 529 AmbLiBriAutAdjmtOnOff1 0;
BA_ "GenSigSendType" SG_ 529 AmbLiChrgCorrlnReqIdPen 0;
BA_ "GenSigSendType" SG_ 529 AmbLiChrgCorrlnReqOnOff1 0;
BA_ "GenSigSendType" SG_ 529 AmbLiClimateCorrlnReqIdPen 0;
BA_ "GenSigSendType" SG_ 529 AmbLiClimateCorrlnReqOnOff1 0;
BA_ "GenSigSendType" SG_ 529 AmbLiDrvModCorrlnReqIdPen 0;
BA_ "GenSigSendType" SG_ 529 AmbLiDrvModCorrlnReqOnOff1 0;
BA_ "GenSigSendType" SG_ 529 AmbLiModAmbLiMod 0;
BA_ "GenSigSendType" SG_ 529 AmbLiModIdPen 0;
BA_ "GenSigSendType" SG_ 529 AmbLiStrtCorrlnReqIdPen 0;
BA_ "GenSigSendType" SG_ 529 AmbLiStrtCorrlnReqOnOff1 0;
BA_ "GenSigSendType" SG_ 529 AmbLiStyleSelnReqIdPen 0;
BA_ "GenSigSendType" SG_ 529 AmbLiStyleSelnReqScene 0;
BA_ "GenSigStartValue" SG_ 641 ExtSysClimaAirDist 7;
BA_ "SystemSignalLongSymbol" SG_ 641 ExtSysClimaFanLvlFanLvlFrntRowLe "ExtSysClimaFanLvlFanLvlFrntRowLeft";
BA_ "SystemSignalLongSymbol" SG_ 641 ExtSysClimaFanLvlFanLvlFrntRowRi "ExtSysClimaFanLvlFanLvlFrntRowRight";
BA_ "SystemSignalLongSymbol" SG_ 641 ExtSysClimaFanLvlFanLvlSecRowLef "ExtSysClimaFanLvlFanLvlSecRowLeft";
BA_ "SystemSignalLongSymbol" SG_ 641 ExtSysClimaFanLvlFanLvlSecRowRig "ExtSysClimaFanLvlFanLvlSecRowRight";
BA_ "GenSigStartValue" SG_ 641 ExtSysClimaTempSpTempFrntRowLeft 14;
BA_ "GenSigStartValue" SG_ 641 ExtSysClimaTempSpTempFrntRowRigh 14;
BA_ "SystemSignalLongSymbol" SG_ 641 ExtSysClimaTempSpTempFrntRowRigh "ExtSysClimaTempSpTempFrntRowRight";
BA_ "GenSigStartValue" SG_ 641 ExtSysClimaTempSpTempSecRowLeft 14;
BA_ "GenSigStartValue" SG_ 641 ExtSysClimaTempSpTempSecRowRight 14;
BA_ "GenSigStartValue" SG_ 392 DISClimaCmptTempSp 14;
BA_ "GenSigStartValue" SG_ 392 DoorSwipDrvrOperReqChks 255;
BA_ "GenSigSendType" SG_ 392 DoorSwipDrvrOperReqChks 0;
BA_ "GenSigSendType" SG_ 392 DoorSwipDrvrOperReqCntr 0;
BA_ "GenSigSendType" SG_ 392 DoorSwipDrvrOperReqDoorOpenerReq 0;
BA_ "GenSigSendType" SG_ 392 DoorSwipDrvrOperReqTrigSrc 0;
BA_ "GenSigStartValue" SG_ 392 DoorSwipLeReOperReqChks 255;
BA_ "GenSigSendType" SG_ 392 DoorSwipLeReOperReqChks 0;
BA_ "GenSigSendType" SG_ 392 DoorSwipLeReOperReqCntr 0;
BA_ "GenSigSendType" SG_ 392 DoorSwipLeReOperReqDoorOpenerReq 0;
BA_ "GenSigSendType" SG_ 392 DoorSwipLeReOperReqTrigSrc 0;
BA_ "GenSigSendType" SG_ 392 SwipDoorDrvrDisb 0;
BA_ "GenSigSendType" SG_ 392 SwipDoorLeReDisb 0;
BA_ "GenSigSendType" SG_ 392 SwipDoorPassDisb 0;
BA_ "GenSigSendType" SG_ 392 SwipDoorRiReDisb 0;
BA_ "GenSigSendType" SG_ 613 FLDSDoorOpenInd 0;
BA_ "GenSigSendType" SG_ 613 FLDSLockgSts 0;
BA_ "GenSigSendType" SG_ 613 RLDSDoorOpenInd 0;
BA_ "GenSigSendType" SG_ 613 RLDSLockgSts 0;
BA_ "GenSigSendType" SG_ 613 RRDSDoorOpenInd 0;
BA_ "GenSigSendType" SG_ 613 RRDSLockgSts 0;
BA_ "GenSigSendType" SG_ 240 DoorDrvrHndlCmd 0;
BA_ "GenSigSendType" SG_ 240 DoorLeReHndlCmd 0;
BA_ "GenSigSendType" SG_ 240 DoorPassHndlCmd 0;
BA_ "GenSigSendType" SG_ 240 DoorRiReHndlCmd 0;
BA_ "GenSigSendType" SG_ 240 DrvrCtrlOfPassSeatFrntReqd 0;
BA_ "GenSigStartValue" SG_ 240 OnBdChrgrHndlSts1 8;
BA_ "GenSigSendType" SG_ 240 OnBdChrgrHndlSts1 0;
BA_ "GenSigStartValue" SG_ 240 TrlrLiPosnActvt 1;
BA_ "GenSigSendType" SG_ 240 TrlrLiPosnActvt 0;
BA_ "GenSigSendType" SG_ 240 VehModMngtGlbSafe1CarModSts1 0;
BA_ "GenSigSendType" SG_ 240 VehModMngtGlbSafe1CarModSubtypWd 0;
BA_ "SystemSignalLongSymbol" SG_ 240 VehModMngtGlbSafe1CarModSubtypWd "VehModMngtGlbSafe1CarModSubtypWdCarModSubtyp";
BA_ "GenSigSendType" SG_ 240 VehModMngtGlbSafe1Chks 0;
BA_ "GenSigFuncType" SG_ 240 VehModMngtGlbSafe1Chks 15;
BA_ "GenSigDataID" SG_ 240 VehModMngtGlbSafe1Chks "0x74";
BA_ "GenSigSendType" SG_ 240 VehModMngtGlbSafe1Cntr 0;
BA_ "GenSigFuncType" SG_ 240 VehModMngtGlbSafe1Cntr 16;
BA_ "GenSigSendType" SG_ 240 VehModMngtGlbSafe1EgyLvlElecMai 0;
BA_ "GenSigSendType" SG_ 240 VehModMngtGlbSafe1EgyLvlElecSubt 0;
BA_ "SystemSignalLongSymbol" SG_ 240 VehModMngtGlbSafe1EgyLvlElecSubt "VehModMngtGlbSafe1EgyLvlElecSubtyp";
BA_ "GenSigSendType" SG_ 240 VehModMngtGlbSafe1FltEgyCnsWdSts 0;
BA_ "GenSigSendType" SG_ 240 VehModMngtGlbSafe1PwrLvlElecMai 0;
BA_ "GenSigSendType" SG_ 240 VehModMngtGlbSafe1PwrLvlElecSubt 0;
BA_ "SystemSignalLongSymbol" SG_ 240 VehModMngtGlbSafe1PwrLvlElecSubt "VehModMngtGlbSafe1PwrLvlElecSubtyp";
BA_ "GenSigStartValue" SG_ 240 VehModMngtGlbSafe1UsgModSts 1;
BA_ "GenSigSendType" SG_ 240 VehModMngtGlbSafe1UsgModSts 0;
BA_ "GenSigSendType" SG_ 533 DCChrgSt 0;
BA_ "GenSigStartValue" SG_ 533 DoorSwipPassOperReqChks 255;
BA_ "GenSigSendType" SG_ 533 DoorSwipPassOperReqChks 0;
BA_ "GenSigSendType" SG_ 533 DoorSwipPassOperReqCntr 0;
BA_ "GenSigSendType" SG_ 533 DoorSwipPassOperReqDoorOpenerReq 0;
BA_ "GenSigSendType" SG_ 533 DoorSwipPassOperReqTrigSrc 0;
BA_ "GenSigStartValue" SG_ 533 DoorSwipRiReOperReqChks 255;
BA_ "GenSigSendType" SG_ 533 DoorSwipRiReOperReqChks 0;
BA_ "GenSigSendType" SG_ 533 DoorSwipRiReOperReqCntr 0;
BA_ "GenSigSendType" SG_ 533 DoorSwipRiReOperReqDoorOpenerReq 0;
BA_ "GenSigSendType" SG_ 533 DoorSwipRiReOperReqTrigSrc 0;
BA_ "GenSigStartValue" SG_ 276 ElecChromWinAtReLeCmd 10;
BA_ "GenSigSendType" SG_ 276 ElecChromWinAtReLeCmd 0;
BA_ "GenSigStartValue" SG_ 276 ElecChromWinAtReRiCmd 10;
BA_ "GenSigSendType" SG_ 276 ElecChromWinAtReRiCmd 0;
BA_ "GenSigSendType" SG_ 310 BackrestAdjmtRowSecLe 0;
BA_ "GenSigSendType" SG_ 310 BackrestAdjmtRowSecRi 0;
BA_ "GenSigSendType" SG_ 310 BackrestAdjmtRowThrdLe 0;
BA_ "GenSigSendType" SG_ 310 BackrestAdjmtRowThrdRi 0;
BA_ "GenSigSendType" SG_ 310 CushTiltAdjmtRowSecLe 0;
BA_ "GenSigSendType" SG_ 310 CushTiltAdjmtRowSecRi 0;
BA_ "GenSigSendType" SG_ 310 HdrestAdjmtRowSecLe 0;
BA_ "GenSigSendType" SG_ 310 HdrestAdjmtRowSecRi 0;
BA_ "GenSigSendType" SG_ 310 HdrestHeiAdjmtRowSecLe 0;
BA_ "GenSigSendType" SG_ 310 HdrestHeiAdjmtRowSecRi 0;
BA_ "GenSigSendType" SG_ 310 LegRestExtonAdjmtRowSecLe 0;
BA_ "GenSigSendType" SG_ 310 LegRestExtonAdjmtRowSecRi 0;
BA_ "GenSigSendType" SG_ 310 LenAdjmtRowSecLe 0;
BA_ "GenSigSendType" SG_ 310 LenAdjmtRowSecRi 0;
BA_ "GenSigSendType" SG_ 256 EgyCnsAllwdForClima 0;
BA_ "GenSigSendType" SG_ 256 ExtrMirrAdjHmiReq 0;
BA_ "GenSigSendType" SG_ 256 ExtrMirrFoldHmiReq 0;
BA_ "GenSigSendType" SG_ 256 ExtrMirrFoldSetgIdPen 0;
BA_ "GenSigSendType" SG_ 256 ExtrMirrFoldSetgMirrDrvr 0;
BA_ "GenSigSendType" SG_ 256 ExtrMirrFoldSetgMirrPass 0;
BA_ "GenSigSendType" SG_ 256 ExtrMirrSelnHmiReq 0;
BA_ "GenSigSendType" SG_ 256 ExtrMirrTiltSetgIdPen 0;
BA_ "GenSigSendType" SG_ 256 ExtrMirrTiltSetgMirrDrvr 0;
BA_ "GenSigSendType" SG_ 256 ExtrMirrTiltSetgMirrPass 0;
BA_ "GenSigStartValue" SG_ 256 IncomingAirQlyCtrlFromHmi 1;
BA_ "GenSigSendType" SG_ 256 IncomingAirQlyCtrlFromHmi 0;
BA_ "GenSigSendType" SG_ 256 LockgCenStsLockSt 0;
BA_ "GenSigSendType" SG_ 256 LockgCenStsTrigSrc 0;
BA_ "GenSigSendType" SG_ 256 LockgCenStsUpdEve 0;
BA_ "GenSigSendType" SG_ 256 PrkgAssiSysRemPrkgSts 0;
BA_ "GenSigStartValue" SG_ 256 RelHumSnsrQf 1;
BA_ "GenSigSendType" SG_ 256 RelHumSnsrQf 0;
BA_ "GenSigSendType" SG_ 256 SteerWhlHeatgPwrAct 0;
BA_ "GenSigSendType" SG_ 320 CbnOverHeatProtnEna 0;
BA_ "GenSigSendType" SG_ 320 CmptmtCoolgSts 0;
BA_ "GenSigStartValue" SG_ 320 FragRefrshAutSetg 1;
BA_ "GenSigSendType" SG_ 320 FragRefrshAutSetg 0;
BA_ "GenSigSendType" SG_ 320 HmiDefrstMaxReq 0;
BA_ "GenSigSendType" SG_ 320 HmiHvacFanLvlFrnt 0;
BA_ "GenSigSendType" SG_ 320 HmiHvacFanLvlRe 0;
BA_ "GenSigSendType" SG_ 320 HmiHvacRecircCmd 0;
BA_ "GenSigSendType" SG_ 320 HmiHvacReCtrl 0;
BA_ "GenSigStartValue" SG_ 320 HmiIImSptFragraReq 1;
BA_ "GenSigSendType" SG_ 320 HmiIImSptFragraReq 0;
BA_ "GenSigStartValue" SG_ 320 HvClimaCmd 1;
BA_ "GenSigSendType" SG_ 320 HvClimaCmd 0;
BA_ "GenSigSendType" SG_ 320 HvSysRlyStsChks 0;
BA_ "GenSigFuncType" SG_ 320 HvSysRlyStsChks 15;
BA_ "GenSigDataID" SG_ 320 HvSysRlyStsChks "0x15";
BA_ "GenSigSendType" SG_ 320 HvSysRlyStsCntr 0;
BA_ "GenSigFuncType" SG_ 320 HvSysRlyStsCntr 16;
BA_ "GenSigStartValue" SG_ 320 HvSysRlyStsHvSysRlySts 2;
BA_ "GenSigSendType" SG_ 320 HvSysRlyStsHvSysRlySts 0;
BA_ "GenSigStartValue" SG_ 320 IncomingAirQlyPopUpReq 1;
BA_ "GenSigSendType" SG_ 320 IncomingAirQlyPopUpReq 0;
BA_ "GenSigStartValue" SG_ 320 SecClimaAutoSet 1;
BA_ "GenSigSendType" SG_ 320 SecClimaAutoSet 0;
BA_ "GenSigStartValue" SG_ 320 TWinRfClsdPopUpReq 1;
BA_ "GenSigSendType" SG_ 320 TWinRfClsdPopUpReq 0;
BA_ "GenSigSendType" SG_ 384 DrvrAirCdnrSetgAirCdnrSetg 0;
BA_ "GenSigSendType" SG_ 384 DrvrAirCdnrSetgIdPen 0;
BA_ "GenSigSendType" SG_ 384 HmiCmptmtCoolgReq 0;
BA_ "GenSigStartValue" SG_ 384 HmiCmptmtTSpForRowFirstLe 14;
BA_ "GenSigSendType" SG_ 384 HmiCmptmtTSpForRowFirstLe 0;
BA_ "GenSigStartValue" SG_ 384 HmiCmptmtTSpForRowFirstRi 14;
BA_ "GenSigSendType" SG_ 384 HmiCmptmtTSpForRowFirstRi 0;
BA_ "GenSigStartValue" SG_ 384 HmiCmptmtTSpForRowSecLe 14;
BA_ "GenSigSendType" SG_ 384 HmiCmptmtTSpForRowSecLe 0;
BA_ "GenSigStartValue" SG_ 384 HmiCmptmtTSpForRowSecRi 14;
BA_ "GenSigSendType" SG_ 384 HmiCmptmtTSpForRowSecRi 0;
BA_ "GenSigSendType" SG_ 384 HmiCmptmtTSpSpclForRowFirstLe 0;
BA_ "GenSigSendType" SG_ 384 HmiCmptmtTSpSpclForRowFirstRi 0;
BA_ "GenSigSendType" SG_ 384 HmiCmptmtTSpSpclForRowSecLe 0;
BA_ "GenSigSendType" SG_ 384 HmiCmptmtTSpSpclForRowSecRi 0;
BA_ "GenSigStartValue" SG_ 384 HmiElecAirDrvrSwtReq 1;
BA_ "GenSigSendType" SG_ 384 HmiElecAirDrvrSwtReq 0;
BA_ "GenSigStartValue" SG_ 384 HmiElecAirPassSwtReq 1;
BA_ "GenSigSendType" SG_ 384 HmiElecAirPassSwtReq 0;
BA_ "GenSigSendType" SG_ 384 HpcDeiceReq 0;
BA_ "GenSigSendType" SG_ 384 HpcHpCoolgPwrSts 0;
BA_ "GenSigSendType" SG_ 384 HpcHpHeatgPwrSts 0;
BA_ "GenSigSendType" SG_ 384 HpcHpModReq 0;
BA_ "GenSigSendType" SG_ 384 TrlrLiRvsgActvt 0;
VAL_ 1120 CmptmtClngPreStrtReq 0 "OnOffNoReq_NoReq" 1 "OnOffNoReq_On" 2 "OnOffNoReq_Off" ;
VAL_ 1120 SecRowLeDefdMassgProgCfgMassgBag 0 "SelectNoSelect_Select" 1 "SelectNoSelect_NoSelect" ;
VAL_ 1120 SecRowLeDefdMassgProgCfgMas_0000 0 "SelectNoSelect_Select" 1 "SelectNoSelect_NoSelect" ;
VAL_ 1120 SecRowLeDefdMassgProgCfgMas_0001 0 "SelectNoSelect_Select" 1 "SelectNoSelect_NoSelect" ;
VAL_ 1120 SecRowLeDefdMassgProgCfgMas_0002 0 "SelectNoSelect_Select" 1 "SelectNoSelect_NoSelect" ;
VAL_ 1120 SecRowLeDefdMassgProgCfgMas_0003 0 "SelectNoSelect_Select" 1 "SelectNoSelect_NoSelect" ;
VAL_ 1120 SecRowLeDefdMassgProgCfgMas_0004 0 "SelectNoSelect_Select" 1 "SelectNoSelect_NoSelect" ;
VAL_ 1120 SecRowLeDefdMassgProgCfgMas_0005 0 "SelectNoSelect_Select" 1 "SelectNoSelect_NoSelect" ;
VAL_ 1120 SecRowLeDefdMassgProgCfgMas_0006 0 "SelectNoSelect_Select" 1 "SelectNoSelect_NoSelect" ;
VAL_ 1120 SecRowLeDefdMassgProgCfgMas_0007 0 "SelectNoSelect_Select" 1 "SelectNoSelect_NoSelect" ;
VAL_ 1120 SecRowLeDefdMassgProgCfgMas_0008 0 "SelectNoSelect_Select" 1 "SelectNoSelect_NoSelect" ;
VAL_ 1120 SecRowLeDefdMassgProgCfgMas_0009 0 "SelectNoSelect_Select" 1 "SelectNoSelect_NoSelect" ;
VAL_ 1120 SecRowLeDefdMassgProgCfgMas_0010 0 "SelectNoSelect_Select" 1 "SelectNoSelect_NoSelect" ;
VAL_ 1120 SecRowLeDefdMassgProgCfgMas_0011 0 "SelectNoSelect_Select" 1 "SelectNoSelect_NoSelect" ;
VAL_ 1120 SecRowLeDefdMassgProgCfgMas_0012 0 "SelectNoSelect_Select" 1 "SelectNoSelect_NoSelect" ;
VAL_ 1120 SecRowLeDefdMassgProgCfgMas_0013 0 "SelectNoSelect_Select" 1 "SelectNoSelect_NoSelect" ;
VAL_ 1120 SecRowLeDefdMassgProgCfgMas_0014 0 "SelectNoSelect_Select" 1 "SelectNoSelect_NoSelect" ;
VAL_ 1120 SecRowLeDefdMassgProgCfgMassgFrq 0 "SelectLvl_Idle" 1 "SelectLvl_Level1" 2 "SelectLvl_Level2" 3 "SelectLvl_Level3" ;
VAL_ 1120 SecRowLeDefdMassgProgCfgMassgInt 0 "SelectLvl_Idle" 1 "SelectLvl_Level1" 2 "SelectLvl_Level2" 3 "SelectLvl_Level3" ;
VAL_ 1120 SecRowLeDefdMassgProgCfgMas_0015 0 "ProgEdit_Idle" 1 "ProgEdit_Edit" 2 "ProgEdit_Remove" 3 "ProgEdit_Save" ;
VAL_ 1171 AmbTRawQly 0 "GenQf1_UndefindDataAccur" 1 "GenQf1_TmpUndefdData" 2 "GenQf1_DataAccurNotWithinSpcn" 3 "GenQf1_AccurData" ;
VAL_ 1171 BltLockStAtDrvrBltLockSt1 0 "BltLockSt1_Unlock" 1 "BltLockSt1_Lock" ;
VAL_ 1171 BltLockStAtDrvrBltLockSts 0 "DevErrSts2_NoFlt" 1 "DevErrSts2_Flt" ;
VAL_ 1171 BltLockStAtPassBltLockSt1 0 "BltLockSt1_Unlock" 1 "BltLockSt1_Lock" ;
VAL_ 1171 BltLockStAtPassBltLockSts 0 "DevErrSts2_NoFlt" 1 "DevErrSts2_Flt" ;
VAL_ 1171 BltLockStAtRowSecLeBltLockEquid 0 "CptEquid_Equid" 1 "CptEquid_NotEquid" ;
VAL_ 1171 BltLockStAtRowSecLeBltLockSt1 0 "BltLockSt1_Unlock" 1 "BltLockSt1_Lock" ;
VAL_ 1171 BltLockStAtRowSecLeBltLockSts 0 "DevErrSts2_NoFlt" 1 "DevErrSts2_Flt" ;
VAL_ 1171 BltLockStAtRowSecMidBltLockEquid 0 "CptEquid_Equid" 1 "CptEquid_NotEquid" ;
VAL_ 1171 BltLockStAtRowSecMidBltLockSt1 0 "BltLockSt1_Unlock" 1 "BltLockSt1_Lock" ;
VAL_ 1171 BltLockStAtRowSecMidBltLockSts 0 "DevErrSts2_NoFlt" 1 "DevErrSts2_Flt" ;
VAL_ 1171 BltLockStAtRowSecRiBltLockEquid 0 "CptEquid_Equid" 1 "CptEquid_NotEquid" ;
VAL_ 1171 BltLockStAtRowSecRiBltLockSt1 0 "BltLockSt1_Unlock" 1 "BltLockSt1_Lock" ;
VAL_ 1171 BltLockStAtRowSecRiBltLockSts 0 "DevErrSts2_NoFlt" 1 "DevErrSts2_Flt" ;
VAL_ 1171 BltLockStAtRowThrdLeBltLockEquid 0 "CptEquid_Equid" 1 "CptEquid_NotEquid" ;
VAL_ 1171 BltLockStAtRowThrdLeBltLockSt1 0 "BltLockSt1_Unlock" 1 "BltLockSt1_Lock" ;
VAL_ 1171 BltLockStAtRowThrdLeBltLockSts 0 "DevErrSts2_NoFlt" 1 "DevErrSts2_Flt" ;
VAL_ 1171 BltLockStAtRowThrdRiBltLockEquid 0 "CptEquid_Equid" 1 "CptEquid_NotEquid" ;
VAL_ 1171 BltLockStAtRowThrdRiBltLockSt1 0 "BltLockSt1_Unlock" 1 "BltLockSt1_Lock" ;
VAL_ 1171 BltLockStAtRowThrdRiBltLockSts 0 "DevErrSts2_NoFlt" 1 "DevErrSts2_Flt" ;
VAL_ 1171 DrvrPfmncAlrmReq 0 "DrvrPfmncWarnReq_Unavailable" 1 "DrvrPfmncWarnReq_Unknown" 2 "DrvrPfmncWarnReq_NoWarning" 3 "DrvrPfmncWarnReq_Distractive" 4 "DrvrPfmncWarnReq_Warninglevel1" 5 "DrvrPfmncWarnReq_Warninglevel2" 6 "DrvrPfmncWarnReq_Reserved" ;
VAL_ 1171 RemChkTInVeh 0 "ReqSts1_NotReqd" 1 "ReqSts1_Reqd" ;
VAL_ 65 ChdLockReLeCtrlHmiReq 0 "LockgCenReq2_Idle" 1 "LockgCenReq2_Unlck" 2 "LockgCenReq2_Lock" ;
VAL_ 65 ChdLockReRiCtrlHmiReq 0 "LockgCenReq2_Idle" 1 "LockgCenReq2_Unlck" 2 "LockgCenReq2_Lock" ;
VAL_ 65 HmiSeatClimaTmrIdPen 0 "IdPen_ProfUkwn" 1 "IdPen_Prof1" 2 "IdPen_Prof2" 3 "IdPen_Prof3" 4 "IdPen_Prof4" 5 "IdPen_Prof5" 6 "IdPen_Prof6" 7 "IdPen_Prof7" 8 "IdPen_Prof8" 9 "IdPen_Prof9" 10 "IdPen_Prof10" 11 "IdPen_Prof11" 12 "IdPen_Prof12" 13 "IdPen_Prof13" 14 "IdPen_Resd14" 15 "IdPen_ProfAll" ;
VAL_ 234 DoorSldngLeReReqDoorOpenerReq 0 "DoorOpenerIdle" 1 "DoorOpenerOpen" 2 "DoorOpenerCls" 3 "DoorOpenerStop" ;
VAL_ 234 DoorSldngLeReReqTrigSrc 0 "NoTrigSrc" 1 "KeyRem" 2 "HMI" 3 "Telm" 4 "OutdSwt" 5 "InsdSwt" ;
VAL_ 234 DoorSldngRiReReqDoorOpenerReq 0 "DoorOpenerIdle" 1 "DoorOpenerOpen" 2 "DoorOpenerCls" 3 "DoorOpenerStop" ;
VAL_ 234 DoorSldngRiReReqTrigSrc 0 "NoTrigSrc" 1 "KeyRem" 2 "HMI" 3 "Telm" 4 "OutdSwt" 5 "InsdSwt" ;
VAL_ 234 FirstRowLeDefdMassgProgSeln 0 "ProgSeln_Dft" 1 "ProgSeln_Defd" ;
VAL_ 234 FirstRowRiDefdMassgProgSeln 0 "ProgSeln_Dft" 1 "ProgSeln_Defd" ;
VAL_ 234 FRDSDoorOpenInd 0 "OnOff1_Off" 1 "OnOff1_On" ;
VAL_ 234 FRDSLockgSts 0 "UnLockLock_UnLock" 1 "UnLockLock_Lock" ;
VAL_ 234 TrsmParkLockdTrsmParkLockd 0 "TrsmParkLock1_ParkNotEngd" 1 "TrsmParkLock1_ParkEngd" 2 "TrsmParkLock1_NotInUse" 3 "TrsmParkLock1_Undefd" ;
VAL_ 91 SeatFoldRaiseReqRowSecLe 0 "SeatFoldRaiseReq_Idle" 1 "SeatFoldRaiseReq_Fold" 2 "SeatFoldRaiseReq_Raise" 3 "SeatFoldRaiseReq_Stop" ;
VAL_ 91 SeatFoldRaiseReqRowSecMid 0 "SeatFoldRaiseReq_Idle" 1 "SeatFoldRaiseReq_Fold" 2 "SeatFoldRaiseReq_Raise" 3 "SeatFoldRaiseReq_Stop" ;
VAL_ 91 SeatFoldRaiseReqRowSecRi 0 "SeatFoldRaiseReq_Idle" 1 "SeatFoldRaiseReq_Fold" 2 "SeatFoldRaiseReq_Raise" 3 "SeatFoldRaiseReq_Stop" ;
VAL_ 91 SeatFoldRaiseReqRowThrdLe 0 "SeatFoldRaiseReq_Idle" 1 "SeatFoldRaiseReq_Fold" 2 "SeatFoldRaiseReq_Raise" 3 "SeatFoldRaiseReq_Stop" ;
VAL_ 91 SeatFoldRaiseReqRowThrdRi 0 "SeatFoldRaiseReq_Idle" 1 "SeatFoldRaiseReq_Fold" 2 "SeatFoldRaiseReq_Raise" 3 "SeatFoldRaiseReq_Stop" ;
VAL_ 91 ShortDropWinDrvrDoor 0 "ShortDrop_Idle" 1 "ShortDrop_Close" 2 "ShortDrop_Open" ;
VAL_ 91 ShortDropWinLeReDoor 0 "ShortDrop_Idle" 1 "ShortDrop_Close" 2 "ShortDrop_Open" ;
VAL_ 91 ShortDropWinPassDoor 0 "ShortDrop_Idle" 1 "ShortDrop_Close" 2 "ShortDrop_Open" ;
VAL_ 91 ShortDropWinRiReDoor 0 "ShortDrop_Idle" 1 "ShortDrop_Close" 2 "ShortDrop_Open" ;
VAL_ 132 LeReWinBtnDwn 0 "PsdNotPsd_NotPsd" 1 "PsdNotPsd_Psd" ;
VAL_ 132 LeReWinBtnRise 0 "PsdNotPsd_NotPsd" 1 "PsdNotPsd_Psd" ;
VAL_ 132 MusicInfoForMusicShow2StateFlagA 0 "Boolean_FALSE" 1 "Boolean_TRUE" ;
VAL_ 132 MusicInfoForMusicShow2StateFlagN 0 "Boolean_FALSE" 1 "Boolean_TRUE" ;
VAL_ 136 MusicInfoForMusicShow3StateFlagA 0 "Boolean_FALSE" 1 "Boolean_TRUE" ;
VAL_ 136 MusicInfoForMusicShow3StateFlagN 0 "Boolean_FALSE" 1 "Boolean_TRUE" ;
VAL_ 136 RiReWinBtnDwn 0 "PsdNotPsd_NotPsd" 1 "PsdNotPsd_Psd" ;
VAL_ 136 RiReWinBtnRise 0 "PsdNotPsd_NotPsd" 1 "PsdNotPsd_Psd" ;
VAL_ 139 MusicInfoForMusicShow4StateFlagA 0 "Boolean_FALSE" 1 "Boolean_TRUE" ;
VAL_ 139 MusicInfoForMusicShow4StateFlagN 0 "Boolean_FALSE" 1 "Boolean_TRUE" ;
VAL_ 960 HmiPassTempSyncSet 0 "OnOff1_Off" 1 "OnOff1_On" ;
VAL_ 960 LegRestRotAdjmtRowSecLe 0 "SwtVertSts1_Idle" 1 "SwtVertSts1_Up" 2 "SwtVertSts1_Dwn" ;
VAL_ 960 LegRestRotAdjmtRowSecRi 0 "SwtVertSts1_Idle" 1 "SwtVertSts1_Up" 2 "SwtVertSts1_Dwn" ;
VAL_ 960 VehTiAndDataDataValid 0 "NoYes1_No" 1 "NoYes1_Yes" ;
VAL_ 243 ActvnOfPudLi 0 "OnOff1_Off" 1 "OnOff1_On" ;
VAL_ 243 CushExtnSecRowLe 0 "SwtHozlSts1_Idle" 1 "SwtHozlSts1_Fwd" 2 "SwtHozlSts1_Backw" ;
VAL_ 243 CushExtnSecRowRi 0 "SwtHozlSts1_Idle" 1 "SwtHozlSts1_Fwd" 2 "SwtHozlSts1_Backw" ;
VAL_ 243 HmiElecAirFrntSwtReqHmiElecAirDr 0 "OnOff1_Off" 1 "OnOff1_On" ;
VAL_ 243 HmiElecAirFrntSwtReqHmiElec_0000 0 "OnOff1_Off" 1 "OnOff1_On" ;
VAL_ 243 HmiElecAirFrntSwtReqHmiElecAirPa 0 "OnOff1_Off" 1 "OnOff1_On" ;
VAL_ 243 HmiElecAirFrntSwtReqHmiElec_0001 0 "OnOff1_Off" 1 "OnOff1_On" ;
VAL_ 243 HmiElecAirReSwtReqHmiElecAirReLe 0 "OnOff1_Off" 1 "OnOff1_On" ;
VAL_ 243 HmiElecAirReSwtReqHmiElecAirReRi 0 "OnOff1_Off" 1 "OnOff1_On" ;
VAL_ 243 RearWinDimEna 0 "SunRoofAndCurtEnaTyp_Di" 1 "SunRoofAndCurtEnaTyp_LimdEna" 2 "SunRoofAndCurtEnaTyp_FullEna" 3 "SunRoofAndCurtEnaTyp_Resd" ;
VAL_ 243 RollAgGlbQf 0 "Qly2_Flt" 1 "Qly2_NoInfo" 2 "Qly2_Vld" ;
VAL_ 243 SecRowLeLoadAndStoreReqErgoPosn 0 "PassMemPosn_Idle" 1 "PassMemPosn_MemBnk1" 2 "PassMemPosn_MemBnk2" 3 "PassMemPosn_MemBnk3" ;
VAL_ 243 SecRowLeLoadAndStoreReqErgoSetgE 0 "EveMemPosn_Idle" 1 "EveMemPosn_Store" 2 "EveMemPosn_Load" 3 "EveMemPosn_Stop" 4 "EveMemPosn_AutMovmt" 5 "EveMemPosn_Upload" 6 "EveMemPosn_Download" 7 "EveMemPosn_Clear" ;
VAL_ 243 SecRowRiLoadAndStoreReqErgoPosn 0 "PassMemPosn_Idle" 1 "PassMemPosn_MemBnk1" 2 "PassMemPosn_MemBnk2" 3 "PassMemPosn_MemBnk3" ;
VAL_ 243 SecRowRiLoadAndStoreReqErgoSetgE 0 "EveMemPosn_Idle" 1 "EveMemPosn_Store" 2 "EveMemPosn_Load" 3 "EveMemPosn_Stop" 4 "EveMemPosn_AutMovmt" 5 "EveMemPosn_Upload" 6 "EveMemPosn_Download" 7 "EveMemPosn_Clear" ;
VAL_ 243 SecRowRiSeatDispMassgFctMassgInt 0 "MassgIntenLvl_IntenLo" 1 "MassgIntenLvl_IntenNorm" 2 "MassgIntenLvl_IntenHi" 3 "MassgIntenLvl_Off" ;
VAL_ 243 SecRowRiSeatDispMassgFctMassgPro 0 "MassgProgTyp_Prog1" 1 "MassgProgTyp_Prog2" 2 "MassgProgTyp_Prog3" 3 "MassgProgTyp_Prog4" 4 "MassgProgTyp_Prog5" 5 "MassgProgTyp_Prog6" 6 "MassgProgTyp_Prog7" 7 "MassgProgTyp_Prog8" ;
VAL_ 243 SecRowRiSeatDispMassgFctOnOff 0 "OnOff1_Off" 1 "OnOff1_On" ;
VAL_ 243 ShoulderAdjmtRowSecLe 0 "SwtHozlSts1_Idle" 1 "SwtHozlSts1_Fwd" 2 "SwtHozlSts1_Backw" ;
VAL_ 243 ShoulderAdjmtRowSecRi 0 "SwtHozlSts1_Idle" 1 "SwtHozlSts1_Fwd" 2 "SwtHozlSts1_Backw" ;
VAL_ 818 HmiCmptmtSecRowLeAirDistbn 0 "HmiCmptmtAirDistbnFrnt_Flr" 1 "HmiCmptmtAirDistbnFrnt_Vent" 2 "HmiCmptmtAirDistbnFrnt_Defrst" 3 "HmiCmptmtAirDistbnFrnt_FlrDefrst" 4 "HmiCmptmtAirDistbnFrnt_FlrVent" 5 "HmiCmptmtAirDistbnFrnt_VentDefrst" 6 "HmiCmptmtAirDistbnFrnt_FlrVentDefrst" 7 "HmiCmptmtAirDistbnFrnt_Aut" ;
VAL_ 818 HmiCmptmtSecRowRiAirDistbn 0 "HmiCmptmtAirDistbnFrnt_Flr" 1 "HmiCmptmtAirDistbnFrnt_Vent" 2 "HmiCmptmtAirDistbnFrnt_Defrst" 3 "HmiCmptmtAirDistbnFrnt_FlrDefrst" 4 "HmiCmptmtAirDistbnFrnt_FlrVent" 5 "HmiCmptmtAirDistbnFrnt_VentDefrst" 6 "HmiCmptmtAirDistbnFrnt_FlrVentDefrst" 7 "HmiCmptmtAirDistbnFrnt_Aut" ;
VAL_ 818 HmiDrvrClimaAutReq 0 "OnOff1_Off" 1 "OnOff1_On" ;
VAL_ 818 HmiDrvrHvacFanLvl 0 "HmiHvacFanLvl_Off" 1 "HmiHvacFanLvl_LvlMan1" 2 "HmiHvacFanLvl_LvlMan2" 3 "HmiHvacFanLvl_LvlMan3" 4 "HmiHvacFanLvl_LvlMan4" 5 "HmiHvacFanLvl_LvlMan5" 6 "HmiHvacFanLvl_LvlMan6" 7 "HmiHvacFanLvl_LvlMan7" 8 "HmiHvacFanLvl_LvlMan8" 9 "HmiHvacFanLvl_LvlMan9" 10 "HmiHvacFanLvl_LvlAutMinusMinus" 11 "HmiHvacFanLvl_LvlAutMinus" 12 "HmiHvacFanLvl_LvlAutNorm" 13 "HmiHvacFanLvl_LvlAutPlus" 14 "HmiHvacFanLvl_LvlAutPlusPlus" 15 "HmiHvacFanLvl_Reserved" ;
VAL_ 818 HmiPassClimaAutReq 0 "OnOff1_Off" 1 "OnOff1_On" ;
VAL_ 818 HmiPassHvacFanLvl 0 "HmiHvacFanLvl_Off" 1 "HmiHvacFanLvl_LvlMan1" 2 "HmiHvacFanLvl_LvlMan2" 3 "HmiHvacFanLvl_LvlMan3" 4 "HmiHvacFanLvl_LvlMan4" 5 "HmiHvacFanLvl_LvlMan5" 6 "HmiHvacFanLvl_LvlMan6" 7 "HmiHvacFanLvl_LvlMan7" 8 "HmiHvacFanLvl_LvlMan8" 9 "HmiHvacFanLvl_LvlMan9" 10 "HmiHvacFanLvl_LvlAutMinusMinus" 11 "HmiHvacFanLvl_LvlAutMinus" 12 "HmiHvacFanLvl_LvlAutNorm" 13 "HmiHvacFanLvl_LvlAutPlus" 14 "HmiHvacFanLvl_LvlAutPlusPlus" 15 "HmiHvacFanLvl_Reserved" ;
VAL_ 818 HmiSecRowLeClimaAutReq 0 "OnOff1_Off" 1 "OnOff1_On" ;
VAL_ 818 HmiSecRowLeHvacFanLvl 0 "HmiHvacFanLvl_Off" 1 "HmiHvacFanLvl_LvlMan1" 2 "HmiHvacFanLvl_LvlMan2" 3 "HmiHvacFanLvl_LvlMan3" 4 "HmiHvacFanLvl_LvlMan4" 5 "HmiHvacFanLvl_LvlMan5" 6 "HmiHvacFanLvl_LvlMan6" 7 "HmiHvacFanLvl_LvlMan7" 8 "HmiHvacFanLvl_LvlMan8" 9 "HmiHvacFanLvl_LvlMan9" 10 "HmiHvacFanLvl_LvlAutMinusMinus" 11 "HmiHvacFanLvl_LvlAutMinus" 12 "HmiHvacFanLvl_LvlAutNorm" 13 "HmiHvacFanLvl_LvlAutPlus" 14 "HmiHvacFanLvl_LvlAutPlusPlus" 15 "HmiHvacFanLvl_Reserved" ;
VAL_ 818 HmiSecRowRiClimaAutReq 0 "OnOff1_Off" 1 "OnOff1_On" ;
VAL_ 818 HmiSecRowRiHvacFanLvl 0 "HmiHvacFanLvl_Off" 1 "HmiHvacFanLvl_LvlMan1" 2 "HmiHvacFanLvl_LvlMan2" 3 "HmiHvacFanLvl_LvlMan3" 4 "HmiHvacFanLvl_LvlMan4" 5 "HmiHvacFanLvl_LvlMan5" 6 "HmiHvacFanLvl_LvlMan6" 7 "HmiHvacFanLvl_LvlMan7" 8 "HmiHvacFanLvl_LvlMan8" 9 "HmiHvacFanLvl_LvlMan9" 10 "HmiHvacFanLvl_LvlAutMinusMinus" 11 "HmiHvacFanLvl_LvlAutMinus" 12 "HmiHvacFanLvl_LvlAutNorm" 13 "HmiHvacFanLvl_LvlAutPlus" 14 "HmiHvacFanLvl_LvlAutPlusPlus" 15 "HmiHvacFanLvl_Reserved" ;
VAL_ 224 DoorPassSts 0 "DoorSts2_Ukwn" 1 "DoorSts2_Opend" 2 "DoorSts2_Clsd" ;
VAL_ 224 DoorRiReSts 0 "DoorSts2_Ukwn" 1 "DoorSts2_Opend" 2 "DoorSts2_Clsd" ;
VAL_ 224 SecRowLeSeatDispSpplFct 0 "SeatActvSpplFct1_NotAvl" 1 "SeatActvSpplFct1_LumExtnAndLumHei" 2 "SeatActvSpplFct1_BackBlster" 3 "SeatActvSpplFct1_CushExtn" 4 "SeatActvSpplFct1_HdrestHeiAndHdrestTilt" 5 "SeatActvSpplFct1_MassgFct" 6 "SeatActvSpplFct1_ShoulderFct" 7 "SeatActvSpplFct1_LegrestFct" ;
VAL_ 224 SecRowRiSeatDispSpplFct 0 "SeatActvSpplFct1_NotAvl" 1 "SeatActvSpplFct1_LumExtnAndLumHei" 2 "SeatActvSpplFct1_BackBlster" 3 "SeatActvSpplFct1_CushExtn" 4 "SeatActvSpplFct1_HdrestHeiAndHdrestTilt" 5 "SeatActvSpplFct1_MassgFct" 6 "SeatActvSpplFct1_ShoulderFct" 7 "SeatActvSpplFct1_LegrestFct" ;
VAL_ 224 SecRowSeatDispBtnPsdSecRowLeSeat 0 "Boolean_FALSE" 1 "Boolean_TRUE" ;
VAL_ 224 SecRowSeatDispBtnPsdSecRowRiSeat 0 "Boolean_FALSE" 1 "Boolean_TRUE" ;
VAL_ 224 TopPosTrFromHmi 0 "PosPerc1_NoReq" 1 "PosPerc1_0to20PercTopPos" 2 "PosPerc1_21to40PercTopPos" 3 "PosPerc1_41to60PercTopPos" 4 "PosPerc1_61to80PercTopPos" 5 "PosPerc1_81to100PercTopPos" ;
VAL_ 224 TrlrLampChkReqFromHmi 0 "StrtStopReq1_Idle" 1 "StrtStopReq1_StrtReq" 2 "StrtStopReq1_StopReq" 3 "StrtStopReq1_Resd" ;
VAL_ 224 TrlrLiFogActvt 0 "OnOff1_Off" 1 "OnOff1_On" ;
VAL_ 224 TrPosnUpprProgmReq 0 "OnOff1_Off" 1 "OnOff1_On" ;
VAL_ 224 TrSts 0 "DoorSts2_Ukwn" 1 "DoorSts2_Opend" 2 "DoorSts2_Clsd" ;
VAL_ 27 ReadLiStsFirstRowLe 0 "Boolean_FALSE" 1 "Boolean_TRUE" ;
VAL_ 27 ReadLiStsFirstRowRi 0 "Boolean_FALSE" 1 "Boolean_TRUE" ;
VAL_ 27 ReadLiStsSecondRowLe 0 "Boolean_FALSE" 1 "Boolean_TRUE" ;
VAL_ 27 ReadLiStsSecondRowRi 0 "Boolean_FALSE" 1 "Boolean_TRUE" ;
VAL_ 27 ReadLiStsThirdRowLe 0 "Boolean_FALSE" 1 "Boolean_TRUE" ;
VAL_ 27 ReadLiStsThirdRowRi 0 "Boolean_FALSE" 1 "Boolean_TRUE" ;
VAL_ 576 AmbLiThemeModSelnReqAmbLiTheme 0 "Theme1_None" 1 "Theme1_Radical" 2 "Theme1_Simple" 3 "Theme1_Liberating" 4 "Theme1_Agile" 5 "Theme1_Fashion" 6 "Theme1_EV" ;
VAL_ 576 AmbLiThemeModSelnReqIdPen 0 "IdPen_ProfUkwn" 1 "IdPen_Prof1" 2 "IdPen_Prof2" 3 "IdPen_Prof3" 4 "IdPen_Prof4" 5 "IdPen_Prof5" 6 "IdPen_Prof6" 7 "IdPen_Prof7" 8 "IdPen_Prof8" 9 "IdPen_Prof9" 10 "IdPen_Prof10" 11 "IdPen_Prof11" 12 "IdPen_Prof12" 13 "IdPen_Prof13" 14 "IdPen_Resd14" 15 "IdPen_ProfAll" ;
VAL_ 576 OneKeyAdjAllSeatDftPosn 0 "OnOff1_Off" 1 "OnOff1_On" ;
VAL_ 576 OneKeyAdjPassSeatFwdPosn 0 "OnOff1_Off" 1 "OnOff1_On" ;
VAL_ 576 Zone4SettingsIdPen 0 "IdPen_ProfUkwn" 1 "IdPen_Prof1" 2 "IdPen_Prof2" 3 "IdPen_Prof3" 4 "IdPen_Prof4" 5 "IdPen_Prof5" 6 "IdPen_Prof6" 7 "IdPen_Prof7" 8 "IdPen_Prof8" 9 "IdPen_Prof9" 10 "IdPen_Prof10" 11 "IdPen_Prof11" 12 "IdPen_Prof12" 13 "IdPen_Prof13" 14 "IdPen_Resd14" 15 "IdPen_ProfAll" ;
VAL_ 576 Zone4SettingsZoneStatus 0 "OnOff1_Off" 1 "OnOff1_On" ;
VAL_ 592 AmbLiSpeechCorrlnReqIdPen 0 "IdPen_ProfUkwn" 1 "IdPen_Prof1" 2 "IdPen_Prof2" 3 "IdPen_Prof3" 4 "IdPen_Prof4" 5 "IdPen_Prof5" 6 "IdPen_Prof6" 7 "IdPen_Prof7" 8 "IdPen_Prof8" 9 "IdPen_Prof9" 10 "IdPen_Prof10" 11 "IdPen_Prof11" 12 "IdPen_Prof12" 13 "IdPen_Prof13" 14 "IdPen_Resd14" 15 "IdPen_ProfAll" ;
VAL_ 592 AmbLiSpeechCorrlnReqOnOff1 0 "OnOff1_Off" 1 "OnOff1_On" ;
VAL_ 592 DrvrSeatFldUnfld 0 "SeatFoldRaiseReq_Idle" 1 "SeatFoldRaiseReq_Fold" 2 "SeatFoldRaiseReq_Raise" 3 "SeatFoldRaiseReq_Stop" ;
VAL_ 592 DrvrSeatHMIpivtCntrl 0 "SwtHozlSts1_Idle" 1 "SwtHozlSts1_Fwd" 2 "SwtHozlSts1_Backw" ;
VAL_ 592 DrvrSeatSts 0 "OccptPresSt1_Undefd1" 1 "OccptPresSt1_OccptNotPrsnt" 2 "OccptPresSt1_OccptPrsnt" 3 "OccptPresSt1_Undefd2" ;
VAL_ 592 RoadInclnForPOD 0 "PitchAndRoll_Invalid" 1 "PitchAndRoll_Neg14" 2 "PitchAndRoll_Neg13" 3 "PitchAndRoll_Neg12" 4 "PitchAndRoll_Neg11" 5 "PitchAndRoll_Neg10" 6 "PitchAndRoll_Neg9" 7 "PitchAndRoll_Neg8" 8 "PitchAndRoll_Neg7" 9 "PitchAndRoll_Neg6" 10 "PitchAndRoll_Neg5" 11 "PitchAndRoll_Neg4" 12 "PitchAndRoll_Neg3" 13 "PitchAndRoll_Neg2" 14 "PitchAndRoll_Neg1" 15 "PitchAndRoll_Pos0" 16 "PitchAndRoll_Pos1" 17 "PitchAndRoll_Pos2" 18 "PitchAndRoll_Pos3" 19 "PitchAndRoll_Pos4" 20 "PitchAndRoll_Pos5" 21 "PitchAndRoll_Pos6" 22 "PitchAndRoll_Pos7" 23 "PitchAndRoll_Pos8" 24 "PitchAndRoll_Pos9" 25 "PitchAndRoll_Pos10" 26 "PitchAndRoll_Pos11" 27 "PitchAndRoll_Pos12" 28 "PitchAndRoll_Pos13" 29 "PitchAndRoll_Pos14" 30 "PitchAndRoll_Reserved1" 31 "PitchAndRoll_Reserved2" ;
VAL_ 592 RollAgGlbForPOD 0 "PitchAndRoll_Invalid" 1 "PitchAndRoll_Neg14" 2 "PitchAndRoll_Neg13" 3 "PitchAndRoll_Neg12" 4 "PitchAndRoll_Neg11" 5 "PitchAndRoll_Neg10" 6 "PitchAndRoll_Neg9" 7 "PitchAndRoll_Neg8" 8 "PitchAndRoll_Neg7" 9 "PitchAndRoll_Neg6" 10 "PitchAndRoll_Neg5" 11 "PitchAndRoll_Neg4" 12 "PitchAndRoll_Neg3" 13 "PitchAndRoll_Neg2" 14 "PitchAndRoll_Neg1" 15 "PitchAndRoll_Pos0" 16 "PitchAndRoll_Pos1" 17 "PitchAndRoll_Pos2" 18 "PitchAndRoll_Pos3" 19 "PitchAndRoll_Pos4" 20 "PitchAndRoll_Pos5" 21 "PitchAndRoll_Pos6" 22 "PitchAndRoll_Pos7" 23 "PitchAndRoll_Pos8" 24 "PitchAndRoll_Pos9" 25 "PitchAndRoll_Pos10" 26 "PitchAndRoll_Pos11" 27 "PitchAndRoll_Pos12" 28 "PitchAndRoll_Pos13" 29 "PitchAndRoll_Pos14" 30 "PitchAndRoll_Reserved1" 31 "PitchAndRoll_Reserved2" ;
VAL_ 592 Zone5SettingsIdPen 0 "IdPen_ProfUkwn" 1 "IdPen_Prof1" 2 "IdPen_Prof2" 3 "IdPen_Prof3" 4 "IdPen_Prof4" 5 "IdPen_Prof5" 6 "IdPen_Prof6" 7 "IdPen_Prof7" 8 "IdPen_Prof8" 9 "IdPen_Prof9" 10 "IdPen_Prof10" 11 "IdPen_Prof11" 12 "IdPen_Prof12" 13 "IdPen_Prof13" 14 "IdPen_Resd14" 15 "IdPen_ProfAll" ;
VAL_ 592 Zone5SettingsZoneStatus 0 "OnOff1_Off" 1 "OnOff1_On" ;
VAL_ 529 AirClngReq 0 "OnOffNoReq_NoReq" 1 "OnOffNoReq_On" 2 "OnOffNoReq_Off" ;
VAL_ 529 AmbLiBriAutAdjmtIdPen 0 "IdPen_ProfUkwn" 1 "IdPen_Prof1" 2 "IdPen_Prof2" 3 "IdPen_Prof3" 4 "IdPen_Prof4" 5 "IdPen_Prof5" 6 "IdPen_Prof6" 7 "IdPen_Prof7" 8 "IdPen_Prof8" 9 "IdPen_Prof9" 10 "IdPen_Prof10" 11 "IdPen_Prof11" 12 "IdPen_Prof12" 13 "IdPen_Prof13" 14 "IdPen_Resd14" 15 "IdPen_ProfAll" ;
VAL_ 529 AmbLiBriAutAdjmtOnOff1 0 "OnOff1_Off" 1 "OnOff1_On" ;
VAL_ 529 AmbLiChrgCorrlnReqIdPen 0 "IdPen_ProfUkwn" 1 "IdPen_Prof1" 2 "IdPen_Prof2" 3 "IdPen_Prof3" 4 "IdPen_Prof4" 5 "IdPen_Prof5" 6 "IdPen_Prof6" 7 "IdPen_Prof7" 8 "IdPen_Prof8" 9 "IdPen_Prof9" 10 "IdPen_Prof10" 11 "IdPen_Prof11" 12 "IdPen_Prof12" 13 "IdPen_Prof13" 14 "IdPen_Resd14" 15 "IdPen_ProfAll" ;
VAL_ 529 AmbLiChrgCorrlnReqOnOff1 0 "OnOff1_Off" 1 "OnOff1_On" ;
VAL_ 529 AmbLiClimateCorrlnReqIdPen 0 "IdPen_ProfUkwn" 1 "IdPen_Prof1" 2 "IdPen_Prof2" 3 "IdPen_Prof3" 4 "IdPen_Prof4" 5 "IdPen_Prof5" 6 "IdPen_Prof6" 7 "IdPen_Prof7" 8 "IdPen_Prof8" 9 "IdPen_Prof9" 10 "IdPen_Prof10" 11 "IdPen_Prof11" 12 "IdPen_Prof12" 13 "IdPen_Prof13" 14 "IdPen_Resd14" 15 "IdPen_ProfAll" ;
VAL_ 529 AmbLiClimateCorrlnReqOnOff1 0 "OnOff1_Off" 1 "OnOff1_On" ;
VAL_ 529 AmbLiDrvModCorrlnReqIdPen 0 "IdPen_ProfUkwn" 1 "IdPen_Prof1" 2 "IdPen_Prof2" 3 "IdPen_Prof3" 4 "IdPen_Prof4" 5 "IdPen_Prof5" 6 "IdPen_Prof6" 7 "IdPen_Prof7" 8 "IdPen_Prof8" 9 "IdPen_Prof9" 10 "IdPen_Prof10" 11 "IdPen_Prof11" 12 "IdPen_Prof12" 13 "IdPen_Prof13" 14 "IdPen_Resd14" 15 "IdPen_ProfAll" ;
VAL_ 529 AmbLiDrvModCorrlnReqOnOff1 0 "OnOff1_Off" 1 "OnOff1_On" ;
VAL_ 529 AmbLiModAmbLiMod 0 "AmbLiMod_None" 1 "AmbLiMod_CustomizedMode" 2 "AmbLiMod_DriveMode" 3 "AmbLiMod_MusicShowMode" 4 "AmbLiMod_WeatherIndn" 5 "AmbLiMod_ThemeMode" 6 "AmbLiMod_TimeMode" 7 "AmbLiMod_ColorStyleMode" ;
VAL_ 529 AmbLiModIdPen 0 "IdPen_ProfUkwn" 1 "IdPen_Prof1" 2 "IdPen_Prof2" 3 "IdPen_Prof3" 4 "IdPen_Prof4" 5 "IdPen_Prof5" 6 "IdPen_Prof6" 7 "IdPen_Prof7" 8 "IdPen_Prof8" 9 "IdPen_Prof9" 10 "IdPen_Prof10" 11 "IdPen_Prof11" 12 "IdPen_Prof12" 13 "IdPen_Prof13" 14 "IdPen_Resd14" 15 "IdPen_ProfAll" ;
VAL_ 529 AmbLiStrtCorrlnReqIdPen 0 "IdPen_ProfUkwn" 1 "IdPen_Prof1" 2 "IdPen_Prof2" 3 "IdPen_Prof3" 4 "IdPen_Prof4" 5 "IdPen_Prof5" 6 "IdPen_Prof6" 7 "IdPen_Prof7" 8 "IdPen_Prof8" 9 "IdPen_Prof9" 10 "IdPen_Prof10" 11 "IdPen_Prof11" 12 "IdPen_Prof12" 13 "IdPen_Prof13" 14 "IdPen_Resd14" 15 "IdPen_ProfAll" ;
VAL_ 529 AmbLiStrtCorrlnReqOnOff1 0 "OnOff1_Off" 1 "OnOff1_On" ;
VAL_ 529 AmbLiStyleSelnReqIdPen 0 "IdPen_ProfUkwn" 1 "IdPen_Prof1" 2 "IdPen_Prof2" 3 "IdPen_Prof3" 4 "IdPen_Prof4" 5 "IdPen_Prof5" 6 "IdPen_Prof6" 7 "IdPen_Prof7" 8 "IdPen_Prof8" 9 "IdPen_Prof9" 10 "IdPen_Prof10" 11 "IdPen_Prof11" 12 "IdPen_Prof12" 13 "IdPen_Prof13" 14 "IdPen_Resd14" 15 "IdPen_ProfAll" ;
VAL_ 529 AmbLiStyleSelnReqScene 0 "SelnReq_NoReq" 1 "SelnReq_Pacific" 2 "SelnReq_Sunset" 3 "SelnReq_Sunrise" 4 "SelnReq_Morning" 5 "SelnReq_Energize" 6 "SelnReq_Moonlight" ;
VAL_ 641 ExtSysClimaAirDist 0 "HmiCmptmtAirDistbnFrnt_Flr" 1 "HmiCmptmtAirDistbnFrnt_Vent" 2 "HmiCmptmtAirDistbnFrnt_Defrst" 3 "HmiCmptmtAirDistbnFrnt_FlrDefrst" 4 "HmiCmptmtAirDistbnFrnt_FlrVent" 5 "HmiCmptmtAirDistbnFrnt_VentDefrst" 6 "HmiCmptmtAirDistbnFrnt_FlrVentDefrst" 7 "HmiCmptmtAirDistbnFrnt_Aut" ;
VAL_ 641 ExtSysClimaAutDefrst 0 "OnOff1_Off" 1 "OnOff1_On" ;
VAL_ 641 ExtSysClimaRecirc 0 "OnOff1_Off" 1 "OnOff1_On" ;
VAL_ 641 ExtSysClimaReq 0 "OnOff1_Off" 1 "OnOff1_On" ;
VAL_ 392 DISClimaDefrstReq 0 "OnOff1_Off" 1 "OnOff1_On" ;
VAL_ 392 DISClimaRecircReq 0 "OnOff1_Off" 1 "OnOff1_On" ;
VAL_ 392 DoorSwipDrvrOperReqDoorOpenerReq 0 "DoorOpenerIdle" 1 "DoorOpenerOpen" 2 "DoorOpenerCls" 3 "DoorOpenerStop" ;
VAL_ 392 DoorSwipDrvrOperReqTrigSrc 0 "NoTrigSrc" 1 "KeyRem" 2 "HMI" 3 "Telm" 4 "OutdSwt" 5 "InsdSwt" ;
VAL_ 392 DoorSwipLeReOperReqDoorOpenerReq 0 "DoorOpenerIdle" 1 "DoorOpenerOpen" 2 "DoorOpenerCls" 3 "DoorOpenerStop" ;
VAL_ 392 DoorSwipLeReOperReqTrigSrc 0 "NoTrigSrc" 1 "KeyRem" 2 "HMI" 3 "Telm" 4 "OutdSwt" 5 "InsdSwt" ;
VAL_ 392 PassSeatHMIpivtCntrl 0 "SwtHozlSts1_Idle" 1 "SwtHozlSts1_Fwd" 2 "SwtHozlSts1_Backw" ;
VAL_ 392 SwipDoorDrvrDisb 0 "Boolean_FALSE" 1 "Boolean_TRUE" ;
VAL_ 392 SwipDoorLeReDisb 0 "Boolean_FALSE" 1 "Boolean_TRUE" ;
VAL_ 392 SwipDoorPassDisb 0 "Boolean_FALSE" 1 "Boolean_TRUE" ;
VAL_ 392 SwipDoorRiReDisb 0 "Boolean_FALSE" 1 "Boolean_TRUE" ;
VAL_ 613 FLDSDoorOpenInd 0 "OnOff1_Off" 1 "OnOff1_On" ;
VAL_ 613 FLDSLockgSts 0 "UnLockLock_UnLock" 1 "UnLockLock_Lock" ;
VAL_ 613 PassSeatFldUnfld 0 "SeatFoldRaiseReq_Idle" 1 "SeatFoldRaiseReq_Fold" 2 "SeatFoldRaiseReq_Raise" 3 "SeatFoldRaiseReq_Stop" ;
VAL_ 613 RLDSDoorOpenInd 0 "OnOff1_Off" 1 "OnOff1_On" ;
VAL_ 613 RLDSLockgSts 0 "UnLockLock_UnLock" 1 "UnLockLock_Lock" ;
VAL_ 613 RRDSDoorOpenInd 0 "OnOff1_Off" 1 "OnOff1_On" ;
VAL_ 613 RRDSLockgSts 0 "UnLockLock_UnLock" 1 "UnLockLock_Lock" ;
VAL_ 240 DoorDrvrHndlCmd 0 "DoorHndlCmd_Idle" 1 "DoorHndlCmd_Deploy" 2 "DoorHndlCmd_Retract" ;
VAL_ 240 DoorLeReHndlCmd 0 "DoorHndlCmd_Idle" 1 "DoorHndlCmd_Deploy" 2 "DoorHndlCmd_Retract" ;
VAL_ 240 DoorPassHndlCmd 0 "DoorHndlCmd_Idle" 1 "DoorHndlCmd_Deploy" 2 "DoorHndlCmd_Retract" ;
VAL_ 240 DoorRiReHndlCmd 0 "DoorHndlCmd_Idle" 1 "DoorHndlCmd_Deploy" 2 "DoorHndlCmd_Retract" ;
VAL_ 240 DrvrCtrlOfPassSeatFrntReqd 0 "OnOff1_Off" 1 "OnOff1_On" ;
VAL_ 240 OnBdChrgrHndlSts1 0 "OnBdChrgrHndlSts1_Disconnected" 1 "OnBdChrgrHndlSts1_ConnectedWithoutPower" 2 "OnBdChrgrHndlSts1_PowerAvailableButNotActivated" 3 "OnBdChrgrHndlSts1_ConnectedWithPower" 4 "OnBdChrgrHndlSts1_DischargeConnectwithoutpowerincar" 5 "OnBdChrgrHndlSts1_DischargeConnectwithoutpoweroutcar" 6 "OnBdChrgrHndlSts1_DischargeConnectwithpowerincar" 7 "OnBdChrgrHndlSts1_DischargeConnectwithpoweroutcar" 8 "OnBdChrgrHndlSts1_Init" 9 "OnBdChrgrHndlSts1_Fault" 10 "OnBdChrgrHndlSts1_NotCompleteConnnected" 11 "OnBdChrgrHndlSts1_Reserved0" 12 "OnBdChrgrHndlSts1_Reserved1" 13 "OnBdChrgrHndlSts1_Reserved2" ;
VAL_ 240 TrlrLiPosnActvt 0 "OnOffCrit1_NotVld1" 1 "OnOffCrit1_Off" 2 "OnOffCrit1_On" 3 "OnOffCrit1_NotVld2" ;
VAL_ 240 VehModMngtGlbSafe1CarModSts1 0 "CarModSts1_CarModNorm" 1 "CarModSts1_CarModTrnsp" 2 "CarModSts1_CarModFcy" 3 "CarModSts1_CarModCrash" 5 "CarModSts1_CarModDyno" ;
VAL_ 240 VehModMngtGlbSafe1FltEgyCnsWdSts 0 "FltEgyCns1_NoFlt" 1 "FltEgyCns1_Flt" ;
VAL_ 240 VehModMngtGlbSafe1UsgModSts 0 "UsgModSts1_UsgModAbdnd" 1 "UsgModSts1_UsgModInActv" 2 "UsgModSts1_UsgModCnvinc" 11 "UsgModSts1_UsgModActv" 13 "UsgModSts1_UsgModDrvg" ;
VAL_ 533 DCChrgSt 0 "DCChrgrSts_Idle" 1 "DCChrgrSts_Prestart" 2 "DCChrgrSts_Charging" 3 "DCChrgrSts_DCChrgnFltVehSide" 4 "DCChrgrSts_DCChrgnFltChrgrSideTempFlt" 5 "DCChrgrSts_DCChrgnFltChrgrSideConnectFlt" 6 "DCChrgrSts_DCChrgnFltChrgrSideOtherFlt" 7 "DCChrgrSts_DCChrgnFltChrgrSideEmgyFlt" 8 "DCChrgrSts_DCChrgnFltChrgrSideComFlt" 9 "DCChrgrSts_Bookcharging" 10 "DCChrgrSts_Shuntdown" 11 "DCChrgrSts_Heating" 12 "DCChrgrSts_Supercharging" 13 "DCChrgrSts_SuperchargingEnd" ;
VAL_ 533 DoorSwipPassOperReqDoorOpenerReq 0 "DoorOpenerIdle" 1 "DoorOpenerOpen" 2 "DoorOpenerCls" 3 "DoorOpenerStop" ;
VAL_ 533 DoorSwipPassOperReqTrigSrc 0 "NoTrigSrc" 1 "KeyRem" 2 "HMI" 3 "Telm" 4 "OutdSwt" 5 "InsdSwt" ;
VAL_ 533 DoorSwipRiReOperReqDoorOpenerReq 0 "DoorOpenerIdle" 1 "DoorOpenerOpen" 2 "DoorOpenerCls" 3 "DoorOpenerStop" ;
VAL_ 533 DoorSwipRiReOperReqTrigSrc 0 "NoTrigSrc" 1 "KeyRem" 2 "HMI" 3 "Telm" 4 "OutdSwt" 5 "InsdSwt" ;
VAL_ 310 BackrestAdjmtRowSecLe 0 "SwtHozlSts1_Idle" 1 "SwtHozlSts1_Fwd" 2 "SwtHozlSts1_Backw" ;
VAL_ 310 BackrestAdjmtRowSecRi 0 "SwtHozlSts1_Idle" 1 "SwtHozlSts1_Fwd" 2 "SwtHozlSts1_Backw" ;
VAL_ 310 BackrestAdjmtRowThrdLe 0 "SwtHozlSts1_Idle" 1 "SwtHozlSts1_Fwd" 2 "SwtHozlSts1_Backw" ;
VAL_ 310 BackrestAdjmtRowThrdRi 0 "SwtHozlSts1_Idle" 1 "SwtHozlSts1_Fwd" 2 "SwtHozlSts1_Backw" ;
VAL_ 310 CushTiltAdjmtRowSecLe 0 "SwtVertSts1_Idle" 1 "SwtVertSts1_Up" 2 "SwtVertSts1_Dwn" ;
VAL_ 310 CushTiltAdjmtRowSecRi 0 "SwtVertSts1_Idle" 1 "SwtVertSts1_Up" 2 "SwtVertSts1_Dwn" ;
VAL_ 310 HdrestAdjmtRowSecLe 0 "SwtHozlSts1_Idle" 1 "SwtHozlSts1_Fwd" 2 "SwtHozlSts1_Backw" ;
VAL_ 310 HdrestAdjmtRowSecRi 0 "SwtHozlSts1_Idle" 1 "SwtHozlSts1_Fwd" 2 "SwtHozlSts1_Backw" ;
VAL_ 310 HdrestHeiAdjmtRowSecLe 0 "SwtVertSts1_Idle" 1 "SwtVertSts1_Up" 2 "SwtVertSts1_Dwn" ;
VAL_ 310 HdrestHeiAdjmtRowSecRi 0 "SwtVertSts1_Idle" 1 "SwtVertSts1_Up" 2 "SwtVertSts1_Dwn" ;
VAL_ 310 LegRestExtonAdjmtRowSecLe 0 "SwtHozlSts1_Idle" 1 "SwtHozlSts1_Fwd" 2 "SwtHozlSts1_Backw" ;
VAL_ 310 LegRestExtonAdjmtRowSecRi 0 "SwtHozlSts1_Idle" 1 "SwtHozlSts1_Fwd" 2 "SwtHozlSts1_Backw" ;
VAL_ 310 LenAdjmtRowSecLe 0 "SwtHozlSts1_Idle" 1 "SwtHozlSts1_Fwd" 2 "SwtHozlSts1_Backw" ;
VAL_ 310 LenAdjmtRowSecRi 0 "SwtHozlSts1_Idle" 1 "SwtHozlSts1_Fwd" 2 "SwtHozlSts1_Backw" ;
VAL_ 256 ExtrMirrAdjHmiReq 0 "MirrDirReqTyp_Idle" 1 "MirrDirReqTyp_Up" 2 "MirrDirReqTyp_Down" 3 "MirrDirReqTyp_Left" 4 "MirrDirReqTyp_Right" ;
VAL_ 256 ExtrMirrFoldHmiReq 0 "PsdNotPsd1_NotPsd" 1 "PsdNotPsd1_Psd" ;
VAL_ 256 ExtrMirrFoldSetgIdPen 0 "IdPen_ProfUkwn" 1 "IdPen_Prof1" 2 "IdPen_Prof2" 3 "IdPen_Prof3" 4 "IdPen_Prof4" 5 "IdPen_Prof5" 6 "IdPen_Prof6" 7 "IdPen_Prof7" 8 "IdPen_Prof8" 9 "IdPen_Prof9" 10 "IdPen_Prof10" 11 "IdPen_Prof11" 12 "IdPen_Prof12" 13 "IdPen_Prof13" 14 "IdPen_Resd14" 15 "IdPen_ProfAll" ;
VAL_ 256 ExtrMirrFoldSetgMirrDrvr 0 "OnOff2_On" 1 "OnOff2_Off" ;
VAL_ 256 ExtrMirrFoldSetgMirrPass 0 "OnOff2_On" 1 "OnOff2_Off" ;
VAL_ 256 ExtrMirrSelnHmiReq 0 "idle" 1 "left" 2 "right" ;
VAL_ 256 ExtrMirrTiltSetgIdPen 0 "IdPen_ProfUkwn" 1 "IdPen_Prof1" 2 "IdPen_Prof2" 3 "IdPen_Prof3" 4 "IdPen_Prof4" 5 "IdPen_Prof5" 6 "IdPen_Prof6" 7 "IdPen_Prof7" 8 "IdPen_Prof8" 9 "IdPen_Prof9" 10 "IdPen_Prof10" 11 "IdPen_Prof11" 12 "IdPen_Prof12" 13 "IdPen_Prof13" 14 "IdPen_Resd14" 15 "IdPen_ProfAll" ;
VAL_ 256 ExtrMirrTiltSetgMirrDrvr 0 "OnOff2_On" 1 "OnOff2_Off" ;
VAL_ 256 ExtrMirrTiltSetgMirrPass 0 "OnOff2_On" 1 "OnOff2_Off" ;
VAL_ 256 IncomingAirQlyCtrlFromHmi 0 "OnOff1_Off" 1 "OnOff1_On" ;
VAL_ 256 LockgCenStsLockSt 0 "LockSt3_LockUndefd" 1 "LockSt3_LockUnlckd" 2 "LockSt3_LockTrUnlckd" 3 "LockSt3_LockLockd" ;
VAL_ 256 LockgCenStsTrigSrc 0 "LockTrigSrc2_NoTrigSrc" 1 "LockTrigSrc2_KeyRem" 2 "LockTrigSrc2_Keyls" 3 "LockTrigSrc2_IntrSwt" 4 "LockTrigSrc2_SpdAut" 5 "LockTrigSrc2_TmrAut" 6 "LockTrigSrc2_Slam" 7 "LockTrigSrc2_Telm" 8 "LockTrigSrc2_Crash" 9 "LockTrigSrc2_Apprch" 10 "LockTrigSrc2_OutsOth" 11 "LockTrigSrc2_InsOth" ;
VAL_ 256 LockgCenStsUpdEve 0 "Boolean_FALSE" 1 "Boolean_TRUE" ;
VAL_ 256 PrkgAssiSysRemPrkgSts 0 "PrkgAssiSysRemPrkgSts_OFF" 1 "PrkgAssiSysRemPrkgSts_Remoteparkinstandby" 2 "PrkgAssiSysRemPrkgSts_Remoteparkoutstandby" 3 "PrkgAssiSysRemPrkgSts_Searching" 4 "PrkgAssiSysRemPrkgSts_Remoteparkinpreactive" 5 "PrkgAssiSysRemPrkgSts_Remoteparkactive" 6 "PrkgAssiSysRemPrkgSts_Parkprocessactive" 7 "PrkgAssiSysRemPrkgSts_Suspend" 8 "PrkgAssiSysRemPrkgSts_Abort" 9 "PrkgAssiSysRemPrkgSts_Remoteparkprocesscompleted" 10 "PrkgAssiSysRemPrkgSts_Remoteparkoutprocscompleted" 11 "PrkgAssiSysRemPrkgSts_Remoteparkcompleted" 12 "PrkgAssiSysRemPrkgSts_Quit" 13 "PrkgAssiSysRemPrkgSts_Failure" 14 "PrkgAssiSysRemPrkgSts_Cancel" ;
VAL_ 256 RelHumSnsrQf 0 "DataQf_NotOk" 1 "DataQf_Ok" ;
VAL_ 320 CbnOverHeatProtnEna 0 "OnOff1_Off" 1 "OnOff1_On" ;
VAL_ 320 CmptmtCoolgSts 0 "CmptmtCoolgSts_OffNoReq" 1 "CmptmtCoolgSts_OffByEvaprTLo" 2 "CmptmtCoolgSts_OffByPLo" 3 "CmptmtCoolgSts_OffByAmbTOutOfRng" 4 "CmptmtCoolgSts_OffBySysFailr" 5 "CmptmtCoolgSts_OffByLoadCut" 6 "CmptmtCoolgSts_OnWithBattCoolg" 7 "CmptmtCoolgSts_On" ;
VAL_ 320 FragRefrshAutSetg 0 "OnOff1_Off" 1 "OnOff1_On" ;
VAL_ 320 HmiDefrstMaxReq 0 "ActrReq_Off" 1 "ActrReq_On" 2 "ActrReq_AutOn" ;
VAL_ 320 HmiHvacFanLvlFrnt 0 "HmiHvacFanLvl_Off" 1 "HmiHvacFanLvl_LvlMan1" 2 "HmiHvacFanLvl_LvlMan2" 3 "HmiHvacFanLvl_LvlMan3" 4 "HmiHvacFanLvl_LvlMan4" 5 "HmiHvacFanLvl_LvlMan5" 6 "HmiHvacFanLvl_LvlMan6" 7 "HmiHvacFanLvl_LvlMan7" 8 "HmiHvacFanLvl_LvlMan8" 9 "HmiHvacFanLvl_LvlMan9" 10 "HmiHvacFanLvl_LvlAutMinusMinus" 11 "HmiHvacFanLvl_LvlAutMinus" 12 "HmiHvacFanLvl_LvlAutNorm" 13 "HmiHvacFanLvl_LvlAutPlus" 14 "HmiHvacFanLvl_LvlAutPlusPlus" 15 "HmiHvacFanLvl_Reserved" ;
VAL_ 320 HmiHvacFanLvlRe 0 "HmiHvacFanLvl_Off" 1 "HmiHvacFanLvl_LvlMan1" 2 "HmiHvacFanLvl_LvlMan2" 3 "HmiHvacFanLvl_LvlMan3" 4 "HmiHvacFanLvl_LvlMan4" 5 "HmiHvacFanLvl_LvlMan5" 6 "HmiHvacFanLvl_LvlMan6" 7 "HmiHvacFanLvl_LvlMan7" 8 "HmiHvacFanLvl_LvlMan8" 9 "HmiHvacFanLvl_LvlMan9" 10 "HmiHvacFanLvl_LvlAutMinusMinus" 11 "HmiHvacFanLvl_LvlAutMinus" 12 "HmiHvacFanLvl_LvlAutNorm" 13 "HmiHvacFanLvl_LvlAutPlus" 14 "HmiHvacFanLvl_LvlAutPlusPlus" 15 "HmiHvacFanLvl_Reserved" ;
VAL_ 320 HmiHvacRecircCmd 0 "HmiHvacRecircCmd_Aut" 1 "HmiHvacRecircCmd_AutWithAirQly" 2 "HmiHvacRecircCmd_RecircFull" 3 "HmiHvacRecircCmd_OscircFull" ;
VAL_ 320 HmiHvacReCtrl 0 "HmiHvacReCtrl_Off" 1 "HmiHvacReCtrl_OffWithNoOccpt" 2 "HmiHvacReCtrl_On" ;
VAL_ 320 HmiIImSptFragraReq 0 "OnOff1_Off" 1 "OnOff1_On" ;
VAL_ 320 HvClimaCmd 0 "HVBattChargnCmd_OK" 1 "HVBattChargnCmd_NOK" 2 "HVBattChargnCmd_INIT" 3 "HVBattChargnCmd_HOLD" ;
VAL_ 320 HvCooltHeatrStsSig 0 "HvCooltHeatrSts_Off" 1 "HvCooltHeatrSts_LockedUntilNextStart" 2 "HvCooltHeatrSts_LockedUntilService" 3 "HvCooltHeatrSts_LockedPermanent" 4 "HvCooltHeatrSts_Operation" 5 "HvCooltHeatrSts_Reserved1" 6 "HvCooltHeatrSts_Reserved2" 7 "HvCooltHeatrSts_Reserved3" ;
VAL_ 320 HvSysRlyStsHvSysRlySts 0 "HvActvnSts_Open" 1 "HvActvnSts_Clsd" 2 "HvActvnSts_KeepSt" 3 "HvActvnSts_OpenAndReqActvDcha" ;
VAL_ 320 IncomingAirQlyPopUpReq 0 "OnOff1_Off" 1 "OnOff1_On" ;
VAL_ 320 SecClimaAutoSet 0 "OnOff1_Off" 1 "OnOff1_On" ;
VAL_ 320 TWinRfClsdPopUpReq 0 "OnOff1_Off" 1 "OnOff1_On" ;
VAL_ 384 DrvrAirCdnrSetgAirCdnrSetg 0 "AirCdnrSetg_Normal" 1 "AirCdnrSetg_ECO" 2 "AirCdnrSetg_Reserved1" ;
VAL_ 384 DrvrAirCdnrSetgIdPen 0 "IdPen_ProfUkwn" 1 "IdPen_Prof1" 2 "IdPen_Prof2" 3 "IdPen_Prof3" 4 "IdPen_Prof4" 5 "IdPen_Prof5" 6 "IdPen_Prof6" 7 "IdPen_Prof7" 8 "IdPen_Prof8" 9 "IdPen_Prof9" 10 "IdPen_Prof10" 11 "IdPen_Prof11" 12 "IdPen_Prof12" 13 "IdPen_Prof13" 14 "IdPen_Resd14" 15 "IdPen_ProfAll" ;
VAL_ 384 HmiCmptmtCoolgReq 0 "HmiCmptmtCoolgReq_Off" 1 "HmiCmptmtCoolgReq_Auto" ;
VAL_ 384 HmiCmptmtTSpSpclForRowFirstLe 0 "HmiCmptmtTSpSpcl_Norm" 1 "HmiCmptmtTSpSpcl_Lo" 2 "HmiCmptmtTSpSpcl_Hi" ;
VAL_ 384 HmiCmptmtTSpSpclForRowFirstRi 0 "HmiCmptmtTSpSpcl_Norm" 1 "HmiCmptmtTSpSpcl_Lo" 2 "HmiCmptmtTSpSpcl_Hi" ;
VAL_ 384 HmiCmptmtTSpSpclForRowSecLe 0 "HmiCmptmtTSpSpcl_Norm" 1 "HmiCmptmtTSpSpcl_Lo" 2 "HmiCmptmtTSpSpcl_Hi" ;
VAL_ 384 HmiCmptmtTSpSpclForRowSecRi 0 "HmiCmptmtTSpSpcl_Norm" 1 "HmiCmptmtTSpSpcl_Lo" 2 "HmiCmptmtTSpSpcl_Hi" ;
VAL_ 384 HmiElecAirDrvrSwtReq 0 "OnOff1_Off" 1 "OnOff1_On" ;
VAL_ 384 HmiElecAirPassSwtReq 0 "OnOff1_Off" 1 "OnOff1_On" ;
VAL_ 384 HpcDeiceReq 0 "DeiceReq_NoReq" 1 "DeiceReq_DeiceChecking" 2 "DeiceReq_Deicing" 3 "DeiceReq_Reserved" ;
VAL_ 384 HpcHpCoolgPwrSts 0 "Boolean_FALSE" 1 "Boolean_TRUE" ;
VAL_ 384 HpcHpHeatgPwrSts 0 "Boolean_FALSE" 1 "Boolean_TRUE" ;
VAL_ 384 HpcHpModReq 0 "HeatPmpModCmd_Initialization" 1 "HeatPmpModCmd_Mode1" 2 "HeatPmpModCmd_Mode2" 3 "HeatPmpModCmd_Mode3" 4 "HeatPmpModCmd_Mode4" 5 "HeatPmpModCmd_Mode5" 6 "HeatPmpModCmd_Mode6" 7 "HeatPmpModCmd_Mode7" 8 "HeatPmpModCmd_Mode8" 9 "HeatPmpModCmd_Mode9" 10 "HeatPmpModCmd_Mode10" 11 "HeatPmpModCmd_Mode11" 12 "HeatPmpModCmd_Mode12" 13 "HeatPmpModCmd_Mode13" 14 "HeatPmpModCmd_Mode14" 15 "HeatPmpModCmd_Mode15" 16 "HeatPmpModCmd_Mode16" 17 "HeatPmpModCmd_Mode17" 18 "HeatPmpModCmd_Mode18" 19 "HeatPmpModCmd_Mode19" 20 "HeatPmpModCmd_Mode20" 21 "HeatPmpModCmd_Reserved" ;
VAL_ 384 TrlrLiRvsgActvt 0 "OnOff1_Off" 1 "OnOff1_On" ;
SIG_GROUP_ 1120 SecRowLeDefdMassgProgCfg 1 : SecRowLeDefdMassgProgCfgMassgBag SecRowLeDefdMassgProgCfgMas_0000 SecRowLeDefdMassgProgCfgMas_0001 SecRowLeDefdMassgProgCfgMas_0002 SecRowLeDefdMassgProgCfgMas_0003 SecRowLeDefdMassgProgCfgMas_0004 SecRowLeDefdMassgProgCfgMas_0005 SecRowLeDefdMassgProgCfgMas_0006 SecRowLeDefdMassgProgCfgMas_0007 SecRowLeDefdMassgProgCfgMas_0008 SecRowLeDefdMassgProgCfgMas_0009 SecRowLeDefdMassgProgCfgMas_0010 SecRowLeDefdMassgProgCfgMas_0011 SecRowLeDefdMassgProgCfgMas_0012 SecRowLeDefdMassgProgCfgMas_0013 SecRowLeDefdMassgProgCfgMas_0014 SecRowLeDefdMassgProgCfgMassgFrq SecRowLeDefdMassgProgCfgMassgInt SecRowLeDefdMassgProgCfgMassProg SecRowLeDefdMassgProgCfgMas_0015 SecRowLeDefdMassgProgCfgMassSeqC;
SIG_GROUP_ 1171 AmbTRaw 1 : AmbTRawAmbTVal AmbTRawQly;
SIG_GROUP_ 1171 BltLockStAtDrvr 1 : BltLockStAtDrvrBltLockSt1 BltLockStAtDrvrBltLockSts;
SIG_GROUP_ 1171 BltLockStAtPass 1 : BltLockStAtPassBltLockSt1 BltLockStAtPassBltLockSts;
SIG_GROUP_ 1171 BltLockStAtRowSecLe 1 : BltLockStAtRowSecLeBltLockEquid BltLockStAtRowSecLeBltLockSt1 BltLockStAtRowSecLeBltLockSts;
SIG_GROUP_ 1171 BltLockStAtRowSecMid 1 : BltLockStAtRowSecMidBltLockEquid BltLockStAtRowSecMidBltLockSt1 BltLockStAtRowSecMidBltLockSts;
SIG_GROUP_ 1171 BltLockStAtRowSecRi 1 : BltLockStAtRowSecRiBltLockEquid BltLockStAtRowSecRiBltLockSt1 BltLockStAtRowSecRiBltLockSts;
SIG_GROUP_ 1171 BltLockStAtRowThrdLe 1 : BltLockStAtRowThrdLeBltLockEquid BltLockStAtRowThrdLeBltLockSt1 BltLockStAtRowThrdLeBltLockSts;
SIG_GROUP_ 1171 BltLockStAtRowThrdRi 1 : BltLockStAtRowThrdRiBltLockEquid BltLockStAtRowThrdRiBltLockSt1 BltLockStAtRowThrdRiBltLockSts;
SIG_GROUP_ 65 HmiSeatClimaTmr 1 : HmiSeatClimaTmrHmiSeatHeatgFirst HmiSeatClimaTmrHmiSeatHeatg_0000 HmiSeatClimaTmrHmiSeatHeatgSecLe HmiSeatClimaTmrHmiSeatHeatgSecRi HmiSeatClimaTmrHmiSeatVentnFirst HmiSeatClimaTmrHmiSeatVentn_0000 HmiSeatClimaTmrHmiSeatVentnSecLe HmiSeatClimaTmrHmiSeatVentnSecRi HmiSeatClimaTmrIdPen;
SIG_GROUP_ 1196 DrvrSeatHallPosDownLd 1 : DrvrSeatHallPosDownLdSeatFrntHei DrvrSeatHallPosDownLdSeatHeiPos DrvrSeatHallPosDownLdSeatInclPos DrvrSeatHallPosDownLdSeatSldPos;
SIG_GROUP_ 234 DoorSldngLeReReq 1 : DoorSldngLeReReqChks DoorSldngLeReReqCntr DoorSldngLeReReqDoorOpenerReq DoorSldngLeReReqTrigSrc;
SIG_GROUP_ 234 DoorSldngRiReReq 1 : DoorSldngRiReReqChks DoorSldngRiReReqCntr DoorSldngRiReReqDoorOpenerReq DoorSldngRiReReqTrigSrc;
SIG_GROUP_ 234 TrsmParkLockd 1 : TrsmParkLockdChks TrsmParkLockdCntr TrsmParkLockdTrsmParkLockd;
SIG_GROUP_ 132 MusicInfoForMusicShow2 1 : MusicInfoForMusicShow2DownSampli MusicInfoForMusicShow2MaxFFT100m MusicInfoForMusicShow2MaxFF_0000 MusicInfoForMusicShow2Segment1FF MusicInfoForMusicShow2Segment2FF MusicInfoForMusicShow2Segment3FF MusicInfoForMusicShow2Segment4FF MusicInfoForMusicShow2Segment5FF MusicInfoForMusicShow2Segment6FF MusicInfoForMusicShow2Segment7FF MusicInfoForMusicShow2Segment8FF MusicInfoForMusicShow2StateFlagA MusicInfoForMusicShow2StateFlagN MusicInfoForMusicShow2TimeFlagAu MusicInfoForMusicShow2TimeFlagMe;
SIG_GROUP_ 136 MusicInfoForMusicShow3 1 : MusicInfoForMusicShow3DownSampli MusicInfoForMusicShow3MaxFFT100m MusicInfoForMusicShow3MaxFF_0000 MusicInfoForMusicShow3Segment1FF MusicInfoForMusicShow3Segment2FF MusicInfoForMusicShow3Segment3FF MusicInfoForMusicShow3Segment4FF MusicInfoForMusicShow3Segment5FF MusicInfoForMusicShow3Segment6FF MusicInfoForMusicShow3Segment7FF MusicInfoForMusicShow3Segment8FF MusicInfoForMusicShow3StateFlagA MusicInfoForMusicShow3StateFlagN MusicInfoForMusicShow3TimeFlagAu MusicInfoForMusicShow3TimeFlagMe;
SIG_GROUP_ 139 MusicInfoForMusicShow4 1 : MusicInfoForMusicShow4DownSampli MusicInfoForMusicShow4MaxFFT100m MusicInfoForMusicShow4MaxFF_0000 MusicInfoForMusicShow4Segment1FF MusicInfoForMusicShow4Segment2FF MusicInfoForMusicShow4Segment3FF MusicInfoForMusicShow4Segment4FF MusicInfoForMusicShow4Segment5FF MusicInfoForMusicShow4Segment6FF MusicInfoForMusicShow4Segment7FF MusicInfoForMusicShow4Segment8FF MusicInfoForMusicShow4StateFlagA MusicInfoForMusicShow4StateFlagN MusicInfoForMusicShow4TimeFlagAu MusicInfoForMusicShow4TimeFlagMe;
SIG_GROUP_ 960 VehTiAndData 1 : VehTiAndDataDataValid VehTiAndDataDay VehTiAndDataHr1 VehTiAndDataMins1 VehTiAndDataMth1 VehTiAndDataSec1 VehTiAndDataYr1;
SIG_GROUP_ 243 HmiElecAirFrntSwtReq 1 : HmiElecAirFrntSwtReqHmiElecAirDr HmiElecAirFrntSwtReqHmiElec_0000 HmiElecAirFrntSwtReqHmiElecAirPa HmiElecAirFrntSwtReqHmiElec_0001;
SIG_GROUP_ 243 HmiElecAirReSwtReq 1 : HmiElecAirReSwtReqHmiElecAirReLe HmiElecAirReSwtReqHmiElecAirReRi;
SIG_GROUP_ 243 RollAgGlb 1 : RollAgGlbQf RollAgGlbVal;
SIG_GROUP_ 243 SecRowLeLoadAndStoreReq 1 : SecRowLeLoadAndStoreReqErgoPosn SecRowLeLoadAndStoreReqErgoSetgE;
SIG_GROUP_ 243 SecRowRiLoadAndStoreReq 1 : SecRowRiLoadAndStoreReqErgoPosn SecRowRiLoadAndStoreReqErgoSetgE;
SIG_GROUP_ 243 SecRowRiSeatDispMassgFct 1 : SecRowRiSeatDispMassgFctMassgInt SecRowRiSeatDispMassgFctMassgPro SecRowRiSeatDispMassgFctOnOff;
SIG_GROUP_ 224 SecRowSeatDispBtnPsd 1 : SecRowSeatDispBtnPsdSecRowLeSeat SecRowSeatDispBtnPsdSecRowRiSeat;
SIG_GROUP_ 27 ReadLiSts 1 : ReadLiStsFirstRowLe ReadLiStsFirstRowRi ReadLiStsSecondRowLe ReadLiStsSecondRowRi ReadLiStsThirdRowLe ReadLiStsThirdRowRi;
SIG_GROUP_ 1375 Vin 1 : VinBlockNr VinVINSignalPos1 VinVINSignalPos2 VinVINSignalPos3 VinVINSignalPos4 VinVINSignalPos5 VinVINSignalPos6 VinVINSignalPos7;
SIG_GROUP_ 576 AmbLiThemeModSelnReq 1 : AmbLiThemeModSelnReqAmbLiTheme AmbLiThemeModSelnReqIdPen;
SIG_GROUP_ 576 Zone4Settings 1 : Zone4SettingsBlue Zone4SettingsGreen Zone4SettingsIdPen Zone4SettingsIntensity Zone4SettingsRed Zone4SettingsZoneStatus;
SIG_GROUP_ 592 AmbLiSpeechCorrlnReq 1 : AmbLiSpeechCorrlnReqIdPen AmbLiSpeechCorrlnReqOnOff1;
SIG_GROUP_ 592 Zone5Settings 1 : Zone5SettingsBlue Zone5SettingsGreen Zone5SettingsIdPen Zone5SettingsIntensity Zone5SettingsRed Zone5SettingsZoneStatus;
SIG_GROUP_ 704 HmiReElecAirDirCrtlReq 1 : HmiReElecAirDirCrtlReqSecRowLePo HmiReElecAirDirCrtlReqSecRo_0000 HmiReElecAirDirCrtlReqSecRowRiPo HmiReElecAirDirCrtlReqSecRo_0001;
SIG_GROUP_ 529 AmbLiBriAutAdjmt 1 : AmbLiBriAutAdjmtCenDispBriSnsrRa AmbLiBriAutAdjmtIdPen AmbLiBriAutAdjmtOnOff1;
SIG_GROUP_ 529 AmbLiChrgCorrlnReq 1 : AmbLiChrgCorrlnReqIdPen AmbLiChrgCorrlnReqOnOff1;
SIG_GROUP_ 529 AmbLiClimateCorrlnReq 1 : AmbLiClimateCorrlnReqIdPen AmbLiClimateCorrlnReqOnOff1;
SIG_GROUP_ 529 AmbLiDrvModCorrlnReq 1 : AmbLiDrvModCorrlnReqIdPen AmbLiDrvModCorrlnReqOnOff1;
SIG_GROUP_ 529 AmbLiMod 1 : AmbLiModAmbLiMod AmbLiModIdPen;
SIG_GROUP_ 529 AmbLiStrtCorrlnReq 1 : AmbLiStrtCorrlnReqIdPen AmbLiStrtCorrlnReqOnOff1;
SIG_GROUP_ 529 AmbLiStyleSelnReq 1 : AmbLiStyleSelnReqIdPen AmbLiStyleSelnReqScene;
SIG_GROUP_ 641 ExtSysClimaFanLvl 1 : ExtSysClimaFanLvlFanLvlFrntRowLe ExtSysClimaFanLvlFanLvlFrntRowRi ExtSysClimaFanLvlFanLvlSecRowLef ExtSysClimaFanLvlFanLvlSecRowRig;
SIG_GROUP_ 641 ExtSysClimaTempSp 1 : ExtSysClimaTempSpTempFrntRowLeft ExtSysClimaTempSpTempFrntRowRigh ExtSysClimaTempSpTempSecRowLeft ExtSysClimaTempSpTempSecRowRight;
SIG_GROUP_ 392 DoorSwipDrvrOperReq 1 : DoorSwipDrvrOperReqChks DoorSwipDrvrOperReqCntr DoorSwipDrvrOperReqDoorOpenerReq DoorSwipDrvrOperReqTrigSrc;
SIG_GROUP_ 392 DoorSwipLeReOperReq 1 : DoorSwipLeReOperReqChks DoorSwipLeReOperReqCntr DoorSwipLeReOperReqDoorOpenerReq DoorSwipLeReOperReqTrigSrc;
SIG_GROUP_ 240 VehModMngtGlbSafe1 1 : VehModMngtGlbSafe1CarModSts1 VehModMngtGlbSafe1CarModSubtypWd VehModMngtGlbSafe1Chks VehModMngtGlbSafe1Cntr VehModMngtGlbSafe1EgyLvlElecMai VehModMngtGlbSafe1EgyLvlElecSubt VehModMngtGlbSafe1FltEgyCnsWdSts VehModMngtGlbSafe1PwrLvlElecMai VehModMngtGlbSafe1PwrLvlElecSubt VehModMngtGlbSafe1UsgModSts;
SIG_GROUP_ 533 DoorSwipPassOperReq 1 : DoorSwipPassOperReqChks DoorSwipPassOperReqCntr DoorSwipPassOperReqDoorOpenerReq DoorSwipPassOperReqTrigSrc;
SIG_GROUP_ 533 DoorSwipRiReOperReq 1 : DoorSwipRiReOperReqChks DoorSwipRiReOperReqCntr DoorSwipRiReOperReqDoorOpenerReq DoorSwipRiReOperReqTrigSrc;
SIG_GROUP_ 256 ExtrMirrFoldSetg 1 : ExtrMirrFoldSetgIdPen ExtrMirrFoldSetgMirrDrvr ExtrMirrFoldSetgMirrPass;
SIG_GROUP_ 256 ExtrMirrTiltSetg 1 : ExtrMirrTiltSetgIdPen ExtrMirrTiltSetgMirrDrvr ExtrMirrTiltSetgMirrPass;
SIG_GROUP_ 256 LockgCenSts 1 : LockgCenStsLockSt LockgCenStsTrigSrc LockgCenStsUpdEve;
SIG_GROUP_ 320 HvSysRlySts 1 : HvSysRlyStsChks HvSysRlyStsCntr HvSysRlyStsHvSysRlySts;
SIG_GROUP_ 384 DrvrAirCdnrSetg 1 : DrvrAirCdnrSetgAirCdnrSetg DrvrAirCdnrSetgIdPen;
SIG_GROUP_ 384 HmiCmptmtTSp 1 : HmiCmptmtTSpForRowFirstLe HmiCmptmtTSpForRowFirstRi HmiCmptmtTSpForRowSecLe HmiCmptmtTSpForRowSecRi HmiCmptmtTSpSpclForRowFirstLe HmiCmptmtTSpSpclForRowFirstRi HmiCmptmtTSpSpclForRowSecLe HmiCmptmtTSpSpclForRowSecRi;
